VERSION "created by dbc creator v1.0"

NS_ :

BS_:

BU_: T_Box GW DMS DVR HUT Tester

BO_ 482 HCU_HC8: 8 GW
 SG_ HCU_PhoneChrgnModeResp : 15|1@0+ (1,0) [0|1] ""  T_Box
 SG_ HCU_PhoneChrgnReqResp : 14|1@0+ (1,0) [0|1] ""  T_Box
 SG_ HCU_HUTChrgnModeResp : 13|1@0+ (1,0) [0|1] ""  T_Box
 SG_ HCU_HUTChrgnReqResp : 12|1@0+ (1,0) [0|1] ""  T_Box
 SG_ HCU_TboxEngStrtReq : 11|1@0+ (1,0) [0|1] ""  T_Box
 SG_ HCU_TotalScore : 23|3@0+ (1,0) [0|5] ""  HUT
 SG_ HCU_IntelBattTempMagResp : 19|1@0+ (1,0) [0|1] ""  T_Box
 SG_ HCU_RemtVehStartReq : 18|1@0+ (1,0) [0|1] ""  T_Box
 SG_ HCU_HC8_0x1E2 : 7|64@0+ (1,0) [0|0] ""  HUT

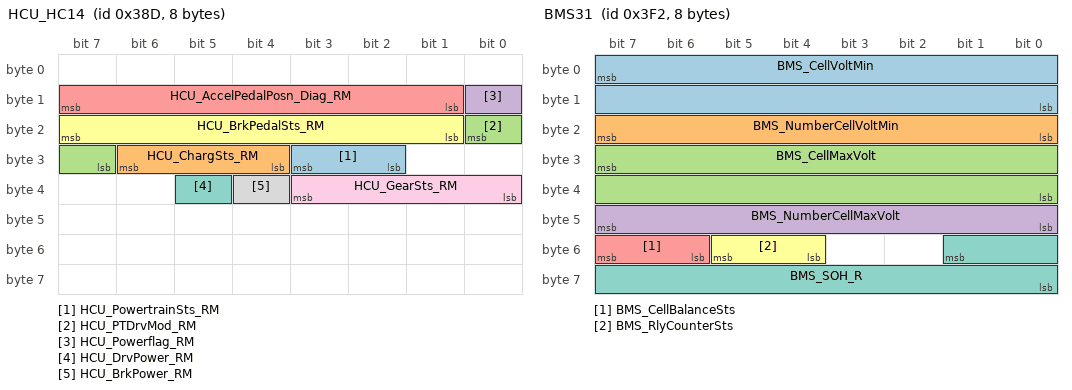
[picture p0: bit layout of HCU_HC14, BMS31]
BO_ 909 HCU_HC14: 8 GW
 SG_ HCU_PowertrainSts_RM : 27|2@0+ (1,0) [0|3] ""  T_Box
 SG_ HCU_ChargSts_RM : 30|3@0+ (1,0) [0|7] ""  T_Box
 SG_ HCU_PTDrvMod_RM : 16|2@0+ (1,0) [0|3] ""  T_Box
 SG_ HCU_Powerflag_RM : 8|1@0+ (1,0) [0|1] ""  T_Box
 SG_ HCU_AccelPedalPosn_Diag_RM : 15|7@0+ (1,0) [0|100] "%"  T_Box
 SG_ HCU_BrkPedalSts_RM : 23|7@0+ (1,0) [0|101] ""  T_Box
 SG_ HCU_DrvPower_RM : 37|1@0+ (1,0) [0|1] ""  T_Box
 SG_ HCU_BrkPower_RM : 36|1@0+ (1,0) [0|1] ""  T_Box
 SG_ HCU_GearSts_RM : 35|4@0+ (1,0) [0|15] ""  T_Box

BO_ 241 BMS4: 8 GW
 SG_ CheckSum_BMS4 : 7|8@0+ (1,0) [0|255] ""  HUT
 SG_ BMS_PowerDownCmplt : 53|1@0+ (1,0) [0|1] ""  HUT
 SG_ BMS_BattPoweErr : 48|2@0+ (1,0) [0|3] ""  HUT
 SG_ BMS_ErrCategory : 62|3@0+ (1,0) [0|7] ""  HUT
 SG_ BMS_PackCurr : 15|14@0+ (0.2,-1000) [-1000|1000] "A"  HUT
 SG_ BMS_PackVolt : 31|8@0+ (2,0) [0|490] "V"  HUT
 SG_ RollingCounter_BMS4 : 59|4@0+ (1,0) [0|15] ""  HUT
 SG_ dummy_BMS4_0 : 17|2@0+ (1,0) [0|3] ""  HUT
 SG_ dummy_BMS4_1 : 39|8@0+ (1,0) [0|255] ""  HUT
 SG_ dummy_BMS4_2 : 47|8@0+ (1,0) [0|255] ""  HUT
 SG_ dummy_BMS4_3 : 55|2@0+ (1,0) [0|3] ""  HUT
 SG_ dummy_BMS4_4 : 52|4@0+ (1,0) [0|15] ""  HUT
 SG_ BMS4_0xF1 : 7|64@0+ (1,0) [0|0] ""  HUT

BO_ 645 BMS8: 8 GW
 SG_ BMS_BattHeatRunaway : 61|2@0+ (1,0) [0|3] ""  HUT,T_Box
 SG_ BMS8_0x285 : 7|64@0+ (1,0) [0|0] ""  HUT

BO_ 708 BMS35: 8 GW
 SG_ BMS_BattSOC : 15|10@0+ (0.1,0) [0|100] "%"  HUT
 SG_ BMS_BattSOCLimResp : 42|3@0+ (1,0) [0|7] ""  HUT
 SG_ BMS35_0x2C4 : 7|64@0+ (1,0) [0|0] ""  HUT

BO_ 850 BMS19: 8 GW
 SG_ BMS_RemtPreHeatSts : 21|3@0+ (1,0) [0|7] ""  T_Box
 SG_ BMS_BattKeepTempSts : 18|1@0+ (1,0) [0|1] ""  HUT,T_Box
 SG_ BMS_IntelEngIdlChrgnSts : 45|2@0+ (1,0) [0|3] ""  HUT,T_Box
 SG_ BMS19_0x352 : 7|64@0+ (1,0) [0|0] ""  HUT

BO_ 959 BMS22: 8 GW
 SG_ BMS_ChrgDurationTime : 47|10@0+ (1,0) [0|1022] "minute"  HUT
 SG_ BMS22_0x3BF : 7|64@0+ (1,0) [0|0] ""  HUT

BO_ 976 BMS26: 8 GW
 SG_ BMS_BattTempMax : 15|8@0+ (1,-40) [-40|125] "Â°C"  T_Box
 SG_ BMS_BattTempMin : 23|8@0+ (1,-40) [-40|125] "Â°C"  T_Box

BO_ 1009 BMS30: 8 GW
 SG_ BMS_CellUnderVolt : 15|1@0+ (1,0) [0|1] ""  T_Box
 SG_ BMS_CellOverVolt : 14|1@0+ (1,0) [0|1] ""  T_Box
 SG_ BMS_CellDeltaVolt : 13|1@0+ (1,0) [0|1] ""  T_Box
 SG_ BMS_BattUnderVolt : 12|1@0+ (1,0) [0|1] ""  T_Box
 SG_ BMS_BattOverVolt : 11|1@0+ (1,0) [0|1] ""  T_Box
 SG_ BMS_BattUnderTemp : 10|1@0+ (1,0) [0|1] ""  T_Box
 SG_ BMS_SOC_Plaucheck : 9|1@0+ (1,0) [0|1] ""  T_Box
 SG_ BMS_DeltaTemp : 8|1@0+ (1,0) [0|1] ""  T_Box
 SG_ BMS_CANComErr : 23|1@0+ (1,0) [0|1] ""  T_Box
 SG_ BMS_SOCLowWarn : 31|1@0+ (1,0) [0|1] ""  HUT
 SG_ BMS_BattSOCLow : 22|1@0+ (1,0) [0|1] ""  T_Box
 SG_ BMS_BattSOCTooLow : 21|1@0+ (1,0) [0|1] ""  T_Box
 SG_ BMS_BattSOCHigh : 20|1@0+ (1,0) [0|1] ""  T_Box
 SG_ BMS_ChrgnCurrLager : 19|1@0+ (1,0) [0|1] ""  T_Box
 SG_ BMS_DischrgnCurrLager : 18|1@0+ (1,0) [0|1] ""  T_Box
 SG_ BMS_ModuleMismatchWarn : 17|1@0+ (1,0) [0|1] ""  T_Box
 SG_ BMS_cohrnc : 16|1@0+ (1,0) [0|1] ""  T_Box
 SG_ BMS_moduleNumber : 43|4@0+ (1,1) [1|9] ""  T_Box
 SG_ BMS_NumModuleTempSnsr : 28|5@0+ (1,1) [1|18] ""  T_Box
 SG_ BMS_NumCell : 39|8@0+ (1,1) [1|108] ""  T_Box
 SG_ BMS30_0x3F1 : 7|64@0+ (1,0) [0|0] ""  HUT

BO_ 1010 BMS31: 8 GW
 SG_ BMS_CellVoltMin : 7|16@0+ (0.001,0) [0|5] "V"  T_Box
 SG_ BMS_NumberCellVoltMin : 23|8@0+ (1,1) [1|108] ""  T_Box
 SG_ BMS_CellMaxVolt : 31|16@0+ (0.001,0) [0|5] "V"  T_Box
 SG_ BMS_NumberCellMaxVolt : 47|8@0+ (1,1) [1|108] ""  T_Box
 SG_ BMS_CellBalanceSts : 55|2@0+ (1,0) [0|3] ""  T_Box
 SG_ BMS_RlyCounterSts : 53|2@0+ (1,0) [0|3] ""  T_Box
 SG_ BMS_SOH_R : 49|10@0+ (0.1,100) [100|200] "%"  T_Box

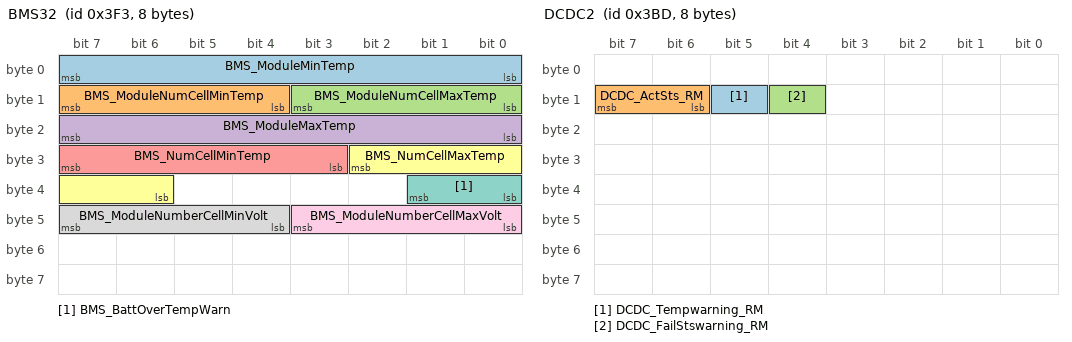
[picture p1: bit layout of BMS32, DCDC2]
BO_ 1011 BMS32: 8 GW
 SG_ BMS_ModuleMinTemp : 7|8@0+ (1,-40) [-40|90] "ÂºC"  T_Box
 SG_ BMS_ModuleNumCellMinTemp : 15|4@0+ (1,1) [1|9] ""  T_Box
 SG_ BMS_ModuleNumCellMaxTemp : 11|4@0+ (1,1) [1|9] ""  T_Box
 SG_ BMS_ModuleMaxTemp : 23|8@0+ (1,-40) [-40|90] "ÂºC"  T_Box
 SG_ BMS_NumCellMinTemp : 31|5@0+ (1,1) [1|18] "_"  T_Box
 SG_ BMS_NumCellMaxTemp : 26|5@0+ (1,1) [1|18] "_"  T_Box
 SG_ BMS_BattOverTempWarn : 33|2@0+ (1,0) [0|3] ""  T_Box
 SG_ BMS_ModuleNumberCellMinVolt : 47|4@0+ (1,1) [1|9] ""  T_Box
 SG_ BMS_ModuleNumberCellMaxVolt : 43|4@0+ (1,1) [1|9] ""  T_Box

BO_ 790 OBC1: 8 GW
 SG_ OBC_ModSts : 19|4@0+ (1,0) [0|15] ""  HUT
 SG_ OBC1_0x316 : 7|64@0+ (1,0) [0|0] ""  HUT

BO_ 791 OBC2: 8 GW
 SG_ OBC_ConnectSts : 15|2@0+ (1,0) [0|3] ""  HUT
 SG_ OBC2_0x317 : 7|64@0+ (1,0) [0|0] ""  HUT

BO_ 96 HCU_FD1: 64 GW
 SG_ HCU_AccelPedalPosn_Diag : 79|8@0+ (0.3937,0) [0|100.395] "%"  HUT
 SG_ HCU_AccelPedalPosn_DiagValid : 85|1@0+ (1,0) [0|1] ""  HUT
 SG_ TMCU_ActRotSpd : 111|16@0+ (1,-16382) [-16382|16383] "rpm"  HUT
 SG_ HCU_PowertrainSts : 303|5@0+ (1,0) [0|31] ""  HUT
 SG_ HCU_RaceLaunchSts : 319|3@0+ (1,0) [0|7] ""  HUT
 SG_ HCU_RaceLaunchAvail : 287|2@0+ (1,0) [0|3] ""  HUT
 SG_ HCU_FD1_0x60 : 7|512@0+ (1,0) [0|0] ""  HUT

BO_ 330 HCU_PT5: 8 GW
 SG_ HCU_DrvMod : 15|4@0+ (1,0) [0|15] ""  HUT
 SG_ HCUImmoAuthRes : 21|2@0+ (1,0) [0|3] ""  HUT
 SG_ HCU_EVLmpSts : 16|1@0+ (1,0) [0|1] ""  HUT
 SG_ HCU_ECODrvHabit_Indcn : 31|8@0+ (0.1,-10) [-10|10] ""  HUT
 SG_ HCU_TotDrvReqPower : 39|8@0+ (1,-100) [-100|100] "%"  HUT
 SG_ HCU_AvailPower_TM : 55|8@0+ (0.5,0) [0|50] "%"  HUT
 SG_ HCU_PT5_0x14A : 7|64@0+ (1,0) [0|0] ""  HUT

BO_ 584 HCU_PT7: 8 GW
 SG_ CheckSum_HCU_PT7 : 7|8@0+ (1,0) [0|255] ""  HUT
 SG_ HCU_HybSysErr_1 : 15|1@0+ (1,0) [0|1] ""  HUT
 SG_ HCU_HybSysErr_2 : 14|1@0+ (1,0) [0|1] ""  HUT
 SG_ HCU_HybSysErr_3 : 13|1@0+ (1,0) [0|1] ""  HUT
 SG_ HCU_HybSysErr_4 : 12|1@0+ (1,0) [0|1] ""  HUT
 SG_ HCU_HybSysErr_5 : 11|1@0+ (1,0) [0|1] ""  HUT
 SG_ HCU_HybSysErr_6 : 10|1@0+ (1,0) [0|1] ""  HUT
 SG_ HCU_HybSysErr_7 : 9|1@0+ (1,0) [0|1] ""  HUT
 SG_ HCU_12VSysErrLmpSts : 8|1@0+ (1,0) [0|1] ""  HUT
 SG_ HCU_HybSysErrLmpSts : 27|2@0+ (1,0) [0|3] ""  HUT
 SG_ HCU_PowerRedWarnLmpCmd : 25|1@0+ (1,0) [0|1] ""  HUT
 SG_ HCU_12VSysErr_1 : 24|1@0+ (1,0) [0|1] ""  HUT
 SG_ HCU_12VSysErr_2 : 39|1@0+ (1,0) [0|1] ""  HUT
 SG_ HCU_RdyLmpSts : 37|1@0+ (1,0) [0|1] ""  HUT
 SG_ HCU_ModSwtFail : 63|4@0+ (1,0) [0|15] ""  HUT
 SG_ HCU_EnrgFlowInd : 55|5@0+ (1,0) [0|31] ""  HUT
 SG_ HCU_OPDSts : 43|3@0+ (1,0) [0|7] ""  HUT
 SG_ HCU_OPDLmpSts : 36|1@0+ (1,0) [0|1] ""  HUT
 SG_ RollingCounter_HCU_PT7 : 59|4@0+ (1,0) [0|15] ""  HUT
 SG_ dummy_HCU_PT7_0 : 23|8@0+ (1,0) [0|255] ""  HUT
 SG_ dummy_HCU_PT7_1 : 31|4@0+ (1,0) [0|15] ""  HUT
 SG_ dummy_HCU_PT7_2 : 38|1@0+ (1,0) [0|1] ""  HUT
 SG_ dummy_HCU_PT7_3 : 35|4@0+ (1,0) [0|15] ""  HUT
 SG_ dummy_HCU_PT7_4 : 47|4@0+ (1,0) [0|15] ""  HUT
 SG_ dummy_HCU_PT7_5 : 40|1@0+ (1,0) [0|1] ""  HUT
 SG_ dummy_HCU_PT7_6 : 50|3@0+ (1,0) [0|7] ""  HUT
 SG_ HCU_PT7_0x248 : 7|64@0+ (1,0) [0|0] ""  HUT

BO_ 448 HCU_PT8: 8 GW
 SG_ HCU_ChrgSysLmpSts : 18|3@0+ (1,0) [0|7] ""  HUT
 SG_ HCU_ChrgSysErr_1 : 31|1@0+ (1,0) [0|1] ""  HUT
 SG_ HCU_ChrgSysErr_2 : 30|1@0+ (1,0) [0|1] ""  HUT
 SG_ HCU_ChrgSysErr_3 : 29|1@0+ (1,0) [0|1] ""  HUT
 SG_ HCU_ChrgSysErr_4 : 28|1@0+ (1,0) [0|1] ""  HUT
 SG_ HCU_ChrgSysErr_5 : 27|1@0+ (1,0) [0|1] ""  HUT
 SG_ HCU_ChrgSysErr_6 : 26|1@0+ (1,0) [0|1] ""  HUT
 SG_ HCU_ChrgSysErr_7 : 25|1@0+ (1,0) [0|1] ""  HUT
 SG_ HCU_ChrgSysErr_8 : 24|1@0+ (1,0) [0|1] ""  HUT
 SG_ HCU_PT8_0x1C0 : 7|64@0+ (1,0) [0|0] ""  HUT

BO_ 762 HCU_PT4: 8 GW
 SG_ CheckSum_HCU_PT4 : 7|8@0+ (1,0) [0|255] ""  HUT
 SG_ HCU_BattPowerRedWarn : 17|2@0+ (1,0) [0|3] ""  HUT
 SG_ HCU_EnerSavePowerMod : 29|2@0+ (1,0) [0|3] ""  HUT
 SG_ HCU_SOCLow_Indcn : 25|1@0+ (1,0) [0|1] ""  HUT
 SG_ HCU_RemoveChrgLine_Indcn : 24|1@0+ (1,0) [0|1] ""  HUT
 SG_ HCU_WadeModeSetSts : 37|1@0+ (1,0) [0|1] ""  HUT
 SG_ HCU_Shift_P_Indcn : 36|1@0+ (1,0) [0|1] ""  HUT
 SG_ HCU_ConnectChrgLine_Indcn : 35|1@0+ (1,0) [0|1] ""  HUT
 SG_ HCU_EgyRecFB : 47|2@0+ (1,0) [0|3] ""  HUT
 SG_ HCU_ACStsReq : 50|2@0+ (1,0) [0|3] ""  HUT
 SG_ HCU_RefuReq : 23|3@0+ (1,0) [0|7] ""  HUT
 SG_ HCU_OilTankCoverSts : 45|1@0+ (1,0) [0|1] ""  HUT
 SG_ HCU_InhbChrgInfo : 44|1@0+ (1,0) [0|1] ""  HUT
 SG_ OPDParkWarnReq : 27|1@0+ (1,0) [0|1] ""  HUT
 SG_ HCU_OPDFail : 31|2@0+ (1,0) [0|3] ""  HUT
 SG_ CarWashMode_StsDisp : 62|3@0+ (1,0) [0|7] ""  HUT
 SG_ CarWashMode_Sts : 63|1@0+ (1,0) [0|1] ""  HUT
 SG_ HCU_RefuBtnSts : 48|1@0+ (1,0) [0|1] ""  T_Box,HUT
 SG_ RollingCounter_HCU_PT4 : 59|4@0+ (1,0) [0|15] ""  HUT
 SG_ dummy_HCU_PT4_0 : 15|8@0+ (1,0) [0|255] ""  HUT
 SG_ dummy_HCU_PT4_1 : 20|3@0+ (1,0) [0|7] ""  HUT
 SG_ dummy_HCU_PT4_2 : 26|1@0+ (1,0) [0|1] ""  HUT
 SG_ dummy_HCU_PT4_3 : 39|2@0+ (1,0) [0|3] ""  HUT
 SG_ dummy_HCU_PT4_4 : 34|3@0+ (1,0) [0|7] ""  HUT
 SG_ dummy_HCU_PT4_5 : 43|4@0+ (1,0) [0|15] ""  HUT
 SG_ dummy_HCU_PT4_6 : 55|5@0+ (1,0) [0|31] ""  HUT
 SG_ HCU_PT4_0x2FA : 7|64@0+ (1,0) [0|0] ""  HUT

BO_ 513 HCU_HP5: 8 GW
 SG_ Checksum_HCU_HP5 : 7|8@0+ (1,0) [0|255] ""  HUT
 SG_ HCU_EnrgFlowInd_DHT : 15|6@0+ (1,0) [0|63] ""  HUT
 SG_ HCU_PrsBrkWarn : 23|2@0+ (1,0) [0|3] ""  HUT
 SG_ DrvModDisp_0x201 : 39|3@0+ (1,0) [0|7] ""  HUT
 SG_ DrvModDispSts_0x201 : 36|2@0+ (1,0) [0|3] ""  HUT
 SG_ DrvGearDisp : 34|3@0+ (1,0) [0|7] ""  HUT
 SG_ DrvGearDispSts_0x201 : 47|2@0+ (1,0) [0|3] ""  HUT
 SG_ HCU_ShftNotAlwd_Warn : 45|2@0+ (1,0) [0|3] ""  HUT
 SG_ DrvFaiMsg_0x201 : 43|4@0+ (1,0) [0|15] ""  HUT
 SG_ RollingCounter_HCU_HP5 : 59|4@0+ (1,0) [0|15] ""  HUT
 SG_ dummy_HCU_HP5_0 : 9|2@0+ (1,0) [0|3] ""  HUT
 SG_ dummy_HCU_HP5_1 : 21|6@0+ (1,0) [0|63] ""  HUT
 SG_ dummy_HCU_HP5_2 : 31|8@0+ (1,0) [0|255] ""  HUT
 SG_ dummy_HCU_HP5_3 : 55|8@0+ (1,0) [0|255] ""  HUT
 SG_ dummy_HCU_HP5_4 : 63|4@0+ (1,0) [0|15] ""  HUT
 SG_ HCU_HP5_0x201 : 7|64@0+ (1,0) [0|0] ""  HUT

BO_ 288 Ibooster_FD2: 64 GW
 SG_ IB_Warn : 46|1@0+ (1,0) [0|1] ""  HUT
 SG_ Ibooster_FD2_0x120 : 7|512@0+ (1,0) [0|0] ""  HUT

BO_ 200 ESP11: 8 GW
 SG_ ESP_HMI_WarningOn : 41|2@0+ (1,0) [0|3] ""  HUT
 SG_ ESP11_0xC8 : 7|64@0+ (1,0) [0|0] ""  HUT

BO_ 216 ESP10: 8 GW
 SG_ TgtRcprtnTrqSts : 47|2@0+ (1,0) [0|3] ""  HUT
 SG_ ESP10_0xD8 : 7|64@0+ (1,0) [0|0] ""  HUT

BO_ 957 DCDC2: 8 GW
 SG_ DCDC_Tempwarning_RM : 13|1@0+ (1,0) [0|1] ""  T_Box
 SG_ DCDC_ActSts_RM : 15|2@0+ (1,0) [0|3] ""  T_Box
 SG_ DCDC_FailStswarning_RM : 12|1@0+ (1,0) [0|1] ""  T_Box

BO_ 969 TMCU_FD3: 8 GW
 SG_ TMCU_Amount_RM : 15|8@0+ (1,0) [1|253] ""  T_Box
 SG_ TMCU_MotorSerNumber_RM : 7|8@0+ (1,0) [1|253] ""  T_Box
 SG_ TMCU_InvActTemp_RM : 23|8@0+ (1,-40) [-40|210] "Â°C"  T_Box
 SG_ TMCU_ActSpd_RM : 31|16@0+ (1,-20000) [-20000|45531] "rpm"  HUT,T_Box
 SG_ TMCU_ActTrq_RM : 47|16@0+ (0.1,-2000) [-2000|4553.1] "Nm"  T_Box
 SG_ TMCU_FD3_0x3C9 : 7|64@0+ (1,0) [0|0] ""  HUT

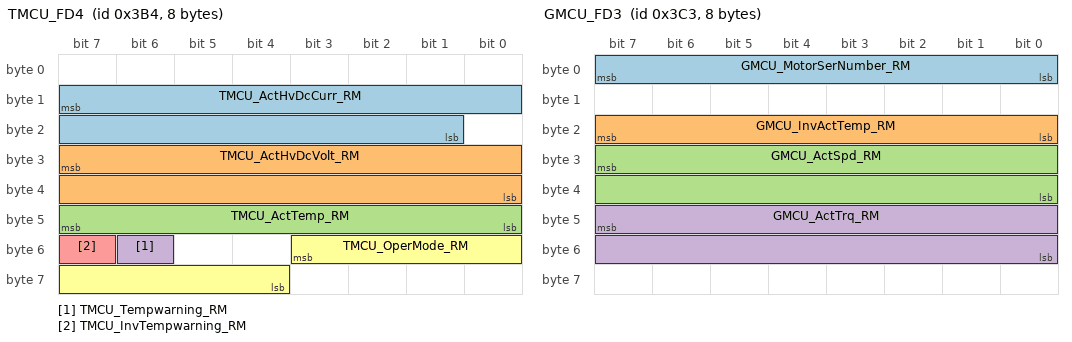
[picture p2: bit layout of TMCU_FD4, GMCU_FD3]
BO_ 948 TMCU_FD4: 8 GW
 SG_ TMCU_ActHvDcCurr_RM : 15|15@0+ (0.1,-1000) [-1000|1000] "A"  T_Box
 SG_ TMCU_ActHvDcVolt_RM : 31|16@0+ (0.1,0) [0|6000] "V"  T_Box
 SG_ TMCU_ActTemp_RM : 47|8@0+ (1,-40) [-40|210] "Â°C"  T_Box
 SG_ TMCU_Tempwarning_RM : 54|1@0+ (1,0) [0|1] ""  T_Box
 SG_ TMCU_InvTempwarning_RM : 55|1@0+ (1,0) [0|1] ""  T_Box
 SG_ TMCU_OperMode_RM : 51|8@0+ (1,0) [0|255] ""  T_Box

BO_ 977 BMS_FD5: 64 GW
 SG_ BMS_BattModuleTe_11 : 135|8@0+ (1,-40) [-40|125] "Â°C"  T_Box
 SG_ BMS_BattModuleTe_12 : 143|8@0+ (1,-40) [-40|125] "Â°C"  T_Box
 SG_ BMS_BattModuleTe_21 : 151|8@0+ (1,-40) [-40|125] "Â°C"  T_Box
 SG_ BMS_BattModuleTe_22 : 159|8@0+ (1,-40) [-40|125] "Â°C"  T_Box
 SG_ BMS_BattModuleTe_31 : 167|8@0+ (1,-40) [-40|125] "Â°C"  T_Box
 SG_ BMS_BattModuleTe_32 : 175|8@0+ (1,-40) [-40|125] "Â°C"  T_Box
 SG_ BMS_BattModuleTe_41 : 183|8@0+ (1,-40) [-40|125] "Â°C"  T_Box
 SG_ BMS_BattModuleTe_42 : 191|8@0+ (1,-40) [-40|125] "Â°C"  T_Box
 SG_ BMS_BattModuleTe_51 : 71|8@0+ (1,-40) [-40|125] "ÂºC"  T_Box
 SG_ BMS_BattModuleTe_52 : 79|8@0+ (1,-40) [-40|125] "ÂºC"  T_Box
 SG_ BMS_BattModuleTe_61 : 87|8@0+ (1,-40) [-40|125] "ÂºC"  T_Box
 SG_ BMS_BattModuleTe_62 : 95|8@0+ (1,-40) [-40|125] "ÂºC"  T_Box
 SG_ BMS_BattModuleTe_71 : 103|8@0+ (1,-40) [-40|125] "ÂºC"  T_Box
 SG_ BMS_BattModuleTe_72 : 111|8@0+ (1,-40) [-40|125] "ÂºC"  T_Box
 SG_ BMS_BattModuleTe_81 : 119|8@0+ (1,-40) [-40|125] "ÂºC"  T_Box
 SG_ BMS_BattModuleTe_82 : 127|8@0+ (1,-40) [-40|125] "ÂºC"  T_Box
 SG_ BMS_SingleCellVolt_1 : 263|16@0+ (0.001,0) [0|60] "V"  T_Box
 SG_ BMS_SingleCellVolt_2 : 279|16@0+ (0.001,0) [0|60] "V"  T_Box
 SG_ BMS_SingleCellVolt_3 : 295|16@0+ (0.001,0) [0|60] "V"  T_Box
 SG_ BMS_SingleCellVolt_4 : 311|16@0+ (0.001,0) [0|60] "V"  T_Box
 SG_ BMS_SingleCellVolt_5 : 327|16@0+ (0.001,0) [0|60] "V"  T_Box
 SG_ BMS_SingleCellVolt_6 : 343|16@0+ (0.001,0) [0|60] "V"  T_Box
 SG_ BMS_SingleCellVolt_7 : 359|16@0+ (0.001,0) [0|60] "V"  T_Box
 SG_ BMS_SingleCellVolt_8 : 375|16@0+ (0.001,0) [0|60] "V"  T_Box
 SG_ BMS_SingleCellVolt_9 : 391|16@0+ (0.001,0) [0|60] "V"  T_Box
 SG_ BMS_SingleCellVolt_10 : 407|16@0+ (0.001,0) [0|60] "V"  T_Box
 SG_ BMS_SingleCellVolt_11 : 423|16@0+ (0.001,0) [0|60] "V"  T_Box
 SG_ BMS_SingleCellVolt_12 : 439|16@0+ (0.001,0) [0|60] "V"  T_Box

BO_ 978 BMS_FD6: 64 GW
 SG_ BMS_SingleCellVolt_13 : 7|16@0+ (0.001,0) [0|60] "V"  T_Box
 SG_ BMS_SingleCellVolt_14 : 23|16@0+ (0.001,0) [0|60] "V"  T_Box
 SG_ BMS_SingleCellVolt_15 : 39|16@0+ (0.001,0) [0|60] "V"  T_Box
 SG_ BMS_SingleCellVolt_16 : 55|16@0+ (0.001,0) [0|60] "V"  T_Box
 SG_ BMS_SingleCellVolt_17 : 71|16@0+ (0.001,0) [0|60] "V"  T_Box
 SG_ BMS_SingleCellVolt_18 : 87|16@0+ (0.001,0) [0|60] "V"  T_Box
 SG_ BMS_SingleCellVolt_19 : 103|16@0+ (0.001,0) [0|60] "V"  T_Box
 SG_ BMS_SingleCellVolt_20 : 119|16@0+ (0.001,0) [0|60] "V"  T_Box
 SG_ BMS_SingleCellVolt_21 : 135|16@0+ (0.001,0) [0|60] "V"  T_Box
 SG_ BMS_SingleCellVolt_22 : 151|16@0+ (0.001,0) [0|60] "V"  T_Box
 SG_ BMS_SingleCellVolt_23 : 167|16@0+ (0.001,0) [0|60] "V"  T_Box
 SG_ BMS_SingleCellVolt_24 : 183|16@0+ (0.001,0) [0|60] "V"  T_Box
 SG_ BMS_SingleCellVolt_25 : 199|16@0+ (0.001,0) [0|60] "V"  T_Box
 SG_ BMS_SingleCellVolt_26 : 215|16@0+ (0.001,0) [0|60] "V"  T_Box
 SG_ BMS_SingleCellVolt_27 : 231|16@0+ (0.001,0) [0|60] "V"  T_Box
 SG_ BMS_SingleCellVolt_28 : 247|16@0+ (0.001,0) [0|60] "V"  T_Box
 SG_ BMS_SingleCellVolt_29 : 263|16@0+ (0.001,0) [0|60] "V"  T_Box
 SG_ BMS_SingleCellVolt_30 : 279|16@0+ (0.001,0) [0|60] "V"  T_Box
 SG_ BMS_SingleCellVolt_31 : 295|16@0+ (0.001,0) [0|60] "V"  T_Box
 SG_ BMS_SingleCellVolt_32 : 311|16@0+ (0.001,0) [0|60] "V"  T_Box
 SG_ BMS_SingleCellVolt_33 : 327|16@0+ (0.001,0) [0|60] "V"  T_Box
 SG_ BMS_SingleCellVolt_34 : 343|16@0+ (0.001,0) [0|60] "V"  T_Box
 SG_ BMS_SingleCellVolt_35 : 359|16@0+ (0.001,0) [0|60] "V"  T_Box
 SG_ BMS_SingleCellVolt_36 : 375|16@0+ (0.001,0) [0|60] "V"  T_Box
 SG_ BMS_SingleCellVolt_37 : 391|16@0+ (0.001,0) [0|60] "V"  T_Box
 SG_ BMS_SingleCellVolt_38 : 407|16@0+ (0.001,0) [0|60] "V"  T_Box
 SG_ BMS_SingleCellVolt_39 : 423|16@0+ (0.001,0) [0|60] "V"  T_Box
 SG_ BMS_SingleCellVolt_40 : 439|16@0+ (0.001,0) [0|60] "V"  T_Box

BO_ 979 BMS_FD7: 64 GW
 SG_ BMS_SingleCellVolt_41 : 7|16@0+ (0.001,0) [0|60] "V"  T_Box
 SG_ BMS_SingleCellVolt_42 : 23|16@0+ (0.001,0) [0|60] "V"  T_Box
 SG_ BMS_SingleCellVolt_43 : 39|16@0+ (0.001,0) [0|60] "V"  T_Box
 SG_ BMS_SingleCellVolt_44 : 55|16@0+ (0.001,0) [0|60] "V"  T_Box
 SG_ BMS_SingleCellVolt_45 : 71|16@0+ (0.001,0) [0|60] "V"  T_Box
 SG_ BMS_SingleCellVolt_46 : 87|16@0+ (0.001,0) [0|60] "V"  T_Box
 SG_ BMS_SingleCellVolt_47 : 103|16@0+ (0.001,0) [0|60] "V"  T_Box
 SG_ BMS_SingleCellVolt_48 : 119|16@0+ (0.001,0) [0|60] "V"  T_Box
 SG_ BMS_SingleCellVolt_49 : 135|16@0+ (0.001,0) [0|60] "V"  T_Box
 SG_ BMS_SingleCellVolt_50 : 151|16@0+ (0.001,0) [0|60] "V"  T_Box
 SG_ BMS_SingleCellVolt_51 : 167|16@0+ (0.001,0) [0|60] "V"  T_Box
 SG_ BMS_SingleCellVolt_52 : 183|16@0+ (0.001,0) [0|60] "V"  T_Box
 SG_ BMS_SingleCellVolt_53 : 199|16@0+ (0.001,0) [0|60] "V"  T_Box
 SG_ BMS_SingleCellVolt_54 : 215|16@0+ (0.001,0) [0|60] "V"  T_Box
 SG_ BMS_SingleCellVolt_55 : 231|16@0+ (0.001,0) [0|60] "V"  T_Box
 SG_ BMS_SingleCellVolt_56 : 247|16@0+ (0.001,0) [0|60] "V"  T_Box
 SG_ BMS_SingleCellVolt_57 : 263|16@0+ (0.001,0) [0|60] "V"  T_Box
 SG_ BMS_SingleCellVolt_58 : 279|16@0+ (0.001,0) [0|60] "V"  T_Box
 SG_ BMS_SingleCellVolt_59 : 295|16@0+ (0.001,0) [0|60] "V"  T_Box
 SG_ BMS_SingleCellVolt_60 : 311|16@0+ (0.001,0) [0|60] "V"  T_Box
 SG_ BMS_SingleCellVolt_61 : 327|16@0+ (0.001,0) [0|60] "V"  T_Box
 SG_ BMS_SingleCellVolt_62 : 343|16@0+ (0.001,0) [0|60] "V"  T_Box
 SG_ BMS_SingleCellVolt_63 : 359|16@0+ (0.001,0) [0|60] "V"  T_Box
 SG_ BMS_SingleCellVolt_64 : 375|16@0+ (0.001,0) [0|60] "V"  T_Box
 SG_ BMS_SingleCellVolt_65 : 391|16@0+ (0.001,0) [0|60] "V"  T_Box
 SG_ BMS_SingleCellVolt_66 : 407|16@0+ (0.001,0) [0|60] "V"  T_Box
 SG_ BMS_SingleCellVolt_67 : 423|16@0+ (0.001,0) [0|60] "V"  T_Box
 SG_ BMS_SingleCellVolt_68 : 439|16@0+ (0.001,0) [0|60] "V"  T_Box

BO_ 980 BMS_FD8: 64 GW
 SG_ BMS_SingleCellVolt_69 : 7|16@0+ (0.001,0) [0|60] "V"  T_Box
 SG_ BMS_SingleCellVolt_70 : 23|16@0+ (0.001,0) [0|60] "V"  T_Box
 SG_ BMS_SingleCellVolt_71 : 39|16@0+ (0.001,0) [0|60] "V"  T_Box
 SG_ BMS_SingleCellVolt_72 : 55|16@0+ (0.001,0) [0|60] "V"  T_Box
 SG_ BMS_SingleCellVolt_73 : 71|16@0+ (0.001,0) [0|60] "V"  T_Box
 SG_ BMS_SingleCellVolt_74 : 87|16@0+ (0.001,0) [0|60] "V"  T_Box
 SG_ BMS_SingleCellVolt_75 : 103|16@0+ (0.001,0) [0|60] "V"  T_Box
 SG_ BMS_SingleCellVolt_76 : 119|16@0+ (0.001,0) [0|60] "V"  T_Box
 SG_ BMS_SingleCellVolt_77 : 135|16@0+ (0.001,0) [0|60] "V"  T_Box
 SG_ BMS_SingleCellVolt_78 : 151|16@0+ (0.001,0) [0|60] "V"  T_Box
 SG_ BMS_SingleCellVolt_79 : 167|16@0+ (0.001,0) [0|60] "V"  T_Box
 SG_ BMS_SingleCellVolt_80 : 183|16@0+ (0.001,0) [0|60] "V"  T_Box
 SG_ BMS_SingleCellVolt_81 : 199|16@0+ (0.001,0) [0|60] "V"  T_Box
 SG_ BMS_SingleCellVolt_82 : 215|16@0+ (0.001,0) [0|60] "V"  T_Box
 SG_ BMS_SingleCellVolt_83 : 231|16@0+ (0.001,0) [0|60] "V"  T_Box
 SG_ BMS_SingleCellVolt_84 : 247|16@0+ (0.001,0) [0|60] "V"  T_Box
 SG_ BMS_SingleCellVolt_85 : 263|16@0+ (0.001,0) [0|60] "V"  T_Box
 SG_ BMS_SingleCellVolt_86 : 279|16@0+ (0.001,0) [0|60] "V"  T_Box
 SG_ BMS_SingleCellVolt_87 : 295|16@0+ (0.001,0) [0|60] "V"  T_Box
 SG_ BMS_SingleCellVolt_88 : 311|16@0+ (0.001,0) [0|60] "V"  T_Box
 SG_ BMS_SingleCellVolt_89 : 327|16@0+ (0.001,0) [0|60] "V"  T_Box
 SG_ BMS_SingleCellVolt_90 : 343|16@0+ (0.001,0) [0|60] "V"  T_Box
 SG_ BMS_SingleCellVolt_91 : 359|16@0+ (0.001,0) [0|60] "V"  T_Box
 SG_ BMS_SingleCellVolt_92 : 375|16@0+ (0.001,0) [0|60] "V"  T_Box
 SG_ BMS_SingleCellVolt_93 : 391|16@0+ (0.001,0) [0|60] "V"  T_Box
 SG_ BMS_SingleCellVolt_94 : 407|16@0+ (0.001,0) [0|60] "V"  T_Box
 SG_ BMS_SingleCellVolt_95 : 423|16@0+ (0.001,0) [0|60] "V"  T_Box
 SG_ BMS_SingleCellVolt_96 : 439|16@0+ (0.001,0) [0|60] "V"  T_Box

BO_ 981 BMS_FD9: 64 GW
 SG_ BMS_SingleCellVolt_97 : 7|16@0+ (0.001,0) [0|60] "V"  T_Box
 SG_ BMS_SingleCellVolt_98 : 23|16@0+ (0.001,0) [0|60] "V"  T_Box
 SG_ BMS_SingleCellVolt_99 : 39|16@0+ (0.001,0) [0|60] "V"  T_Box
 SG_ BMS_SingleCellVolt_100 : 55|16@0+ (0.001,0) [0|60] "V"  T_Box
 SG_ BMS_SingleCellVolt_101 : 71|16@0+ (0.001,0) [0|60] "V"  T_Box
 SG_ BMS_SingleCellVolt_102 : 87|16@0+ (0.001,0) [0|60] "V"  T_Box
 SG_ BMS_SingleCellVolt_103 : 103|16@0+ (0.001,0) [0|60] "V"  T_Box
 SG_ BMS_SingleCellVolt_104 : 119|16@0+ (0.001,0) [0|60] "V"  T_Box
 SG_ BMS_SingleCellVolt_105 : 135|16@0+ (0.001,0) [0|60] "V"  T_Box
 SG_ BMS_SingleCellVolt_106 : 151|16@0+ (0.001,0) [0|60] "V"  T_Box
 SG_ BMS_SingleCellVolt_107 : 167|16@0+ (0.001,0) [0|60] "V"  T_Box
 SG_ BMS_SingleCellVolt_108 : 183|16@0+ (0.001,0) [0|60] "V"  T_Box
 SG_ BMS_SingleCellVolt_109 : 199|16@0+ (0.001,0) [0|60] "V"  T_Box
 SG_ BMS_SingleCellVolt_110 : 215|16@0+ (0.001,0) [0|60] "V"  T_Box
 SG_ BMS_SingleCellVolt_111 : 231|16@0+ (0.001,0) [0|60] "V"  T_Box
 SG_ BMS_SingleCellVolt_112 : 247|16@0+ (0.001,0) [0|60] "V"  T_Box
 SG_ BMS_BattModuleTe_91 : 263|8@0+ (1,-40) [-40|125] "Â°C"  T_Box
 SG_ BMS_BattModuleTe_92 : 271|8@0+ (1,-40) [-40|125] "Â°C"  T_Box
 SG_ BMS_DTCNumber : 279|9@0+ (1,0) [0|501] ""  T_Box
 SG_ BMS_SWVersion_PHEV : 286|16@0+ (1,0) [0|65535] ""  T_Box
 SG_ BMS_NumberCellVoltMin_RM : 311|8@0+ (1,0) [1|250] ""  T_Box
 SG_ BMS_ModuleMaxTemp_RM : 319|8@0+ (1,-40) [-40|210] "â„ƒ"  T_Box
 SG_ BMS_BattModuleTe_13 : 391|8@0+ (1,-40) [-40|125] "Â°C"  T_Box
 SG_ BMS_BattModuleTe_23 : 399|8@0+ (1,-40) [-40|125] "Â°C"  T_Box
 SG_ BMS_BattModuleTe_33 : 407|8@0+ (1,-40) [-40|125] "Â°C"  T_Box
 SG_ BMS_BattModuleTe_43 : 415|8@0+ (1,-40) [-40|125] "Â°C"  T_Box
 SG_ BMS_BattModuleTe_53 : 423|8@0+ (1,-40) [-40|125] "Â°C"  T_Box
 SG_ BMS_BattModuleTe_63 : 431|8@0+ (1,-40) [-40|125] "Â°C"  T_Box

BO_ 1008 BMS_FD12: 64 GW
 SG_ BMS_CellMaxVolt_RM : 327|16@0+ (0.001,0) [0|15] "V"  T_Box
 SG_ BMS_CellVoltMin_RM : 343|16@0+ (0.001,0) [0|15] "V"  T_Box
 SG_ BMS_NumCellMaxTemp_RM : 359|8@0+ (1,0) [1|250] ""  T_Box
 SG_ BMS_NumCellMinTemp_RM : 367|8@0+ (1,0) [1|250] ""  T_Box
 SG_ BMS_ModuleMinTemp_RM : 375|8@0+ (1,-40) [-40|210] "â„ƒ"  T_Box
 SG_ BMS_NumberCellVoltMax_RM : 383|8@0+ (1,0) [1|250] ""  T_Box
 SG_ BMS_SocJumpWarn_RM : 391|1@0+ (1,0) [0|1] ""  T_Box
 SG_ BMS_PackOverChrgWarn_RM : 390|1@0+ (1,0) [0|1] ""  T_Box
 SG_ BMS_IsolationRValue_RM : 399|16@0+ (1,0) [0|60000] "Kohm"  T_Box
 SG_ BMS_PackCurr_RM : 415|15@0+ (0.1,-1000) [-1000|1000] "A"  T_Box
 SG_ BMS_SocOverWarn_RM : 416|1@0+ (1,0) [0|1] ""  T_Box
 SG_ BMS_BattOverTempRank_RM : 431|1@0+ (1,0) [0|1] ""  T_Box
 SG_ BMS_BattOverVoltRank_RM : 430|1@0+ (1,0) [0|1] ""  T_Box
 SG_ BMS_BattSOCLowRank_RM : 429|1@0+ (1,0) [0|1] ""  T_Box
 SG_ BMS_VCUIsolateErr_RM : 428|1@0+ (1,0) [0|1] ""  T_Box
 SG_ BMS_BattUnderVoltRank_RM : 427|1@0+ (1,0) [0|1] ""  T_Box
 SG_ BMS_CellDeltaVoltRank_RM : 426|1@0+ (1,0) [0|1] ""  T_Box
 SG_ BMS_CellOverVoltRank_RM : 425|1@0+ (1,0) [0|1] ""  T_Box
 SG_ BMS_CellUnderVoltRank_RM : 424|1@0+ (1,0) [0|1] ""  T_Box
 SG_ BMS_DeltaTempRank_RM : 439|1@0+ (1,0) [0|1] ""  T_Box
 SG_ BMS_PackMismatchWarn_RM : 438|1@0+ (1,0) [0|1] ""  T_Box
 SG_ BMS_PackVolt_RM : 437|14@0+ (0.1,0) [0|1000] "V"  T_Box
 SG_ BMS_SysNumberCellVoltMax_RM : 455|8@0+ (1,0) [1|250] ""  T_Box
 SG_ BMS_SysNumberCellVoltMin_RM : 463|8@0+ (1,0) [1|250] ""  T_Box
 SG_ BMS_SysNumCellMaxTemp_RM : 471|8@0+ (1,0) [0|250] ""  T_Box
 SG_ BMS_SysNumCellMinTemp_RM : 479|8@0+ (1,0) [0|250] ""  T_Box
 SG_ BMS_BattSysNum_RM : 487|8@0+ (1,0) [0|250] ""  T_Box

BO_ 483 BMS_FD14: 8 GW
 SG_ BMS_BattKeepTempResp_PHEV : 11|2@0+ (1,0) [0|3] ""  T_Box

BO_ 147 TMCU6: 8 GW
 SG_ TMCU_ActPosRotSpd : 15|16@0+ (1,0) [0|65534] "rpm"  HUT,T_Box,DMS,DVR
 SG_ TMCU6_0x93 : 7|64@0+ (1,0) [0|0] ""  HUT

BO_ 193 DHT_FD1: 64 GW
 SG_ CheckSum_DHT1 : 71|8@0+ (1,0) [0|255] ""  HUT
 SG_ TCU_ClutchHotWarning : 73|2@0+ (1,0) [0|3] ""  HUT
 SG_ TCU_ErrCategory : 103|8@0+ (1,0) [0|255] ""  HUT
 SG_ RollingCounter_DHT1 : 123|4@0+ (1,0) [0|15] ""  HUT
 SG_ dummy_DHT_FD1_8 : 79|6@0+ (1,0) [0|63] ""  HUT
 SG_ dummy_DHT_FD1_9 : 87|8@0+ (1,0) [0|255] ""  HUT
 SG_ dummy_DHT_FD1_10 : 95|8@0+ (1,0) [0|255] ""  HUT
 SG_ dummy_DHT_FD1_11 : 111|8@0+ (1,0) [0|255] ""  HUT
 SG_ dummy_DHT_FD1_12 : 119|8@0+ (1,0) [0|255] ""  HUT
 SG_ dummy_DHT_FD1_13 : 127|4@0+ (1,0) [0|15] ""  HUT
 SG_ DHT_FD1_0xC1 : 7|512@0+ (1,0) [0|0] ""  HUT

BO_ 282 HCU_HP6: 8 GW
 SG_ HCU_GearSts : 36|4@0+ (1,0) [0|15] ""  HUT,T_Box,DMS
 SG_ HCU_HP6_0x11A : 7|64@0+ (1,0) [0|0] ""  HUT

BO_ 265 IFC1: 8 GW
 SG_ IFCTrqOvlCmdProtnValue : 15|14@0+ (1,0) [0|16383] ""  HUT
 SG_ IFCTrqOvlCmdReqValue : 39|11@0+ (0.01,-10.23) [-10.23|10.24] "Nm"  HUT
 SG_ IFC1_0x109 : 7|64@0+ (1,0) [0|0] ""  HUT

BO_ 350 CR_FD1: 64 GW
 SG_ CR_FCTA_Resp : 79|1@0+ (1,0) [0|1] ""  HUT
 SG_ CR_FCTB_Resp : 78|1@0+ (1,0) [0|1] ""  HUT
 SG_ CR_BliSts : 86|1@0+ (1,0) [0|1] ""  HUT
 SG_ FCTA_Warn : 75|1@0+ (1,0) [0|1] ""  HUT
 SG_ FCTBTrig : 83|1@0+ (1,0) [0|1] ""  HUT
 SG_ FCTA_B_FuncSts : 77|2@0+ (1,0) [0|3] ""  HUT
 SG_ FCTA_B_TTC : 110|6@0+ (0.1,0) [0|6.3] "s"  HUT
 SG_ CR_FD1_0x15E : 7|512@0+ (1,0) [0|0] ""  HUT

BO_ 692 ACC_FD3: 64 GW
 SG_ AEB_LePedDetn : 41|2@0+ (1,0) [0|3] "" Vector__XXX
 SG_ AEB_LePedDy : 15|8@0+ (0.1,-8) [-8|8] "m" Vector__XXX
 SG_ AEB_LePedTyp : 55|3@0+ (1,0) [0|7] "" Vector__XXX
 SG_ AEB_LePed_collisionprob : 63|1@0+ (1,0) [0|1] "" Vector__XXX
 SG_ AEB_RiPedDetn : 49|2@0+ (1,0) [0|3] "" Vector__XXX
 SG_ AEB_RiPedDy : 23|8@0+ (0.1,-8) [-8|8] "m" Vector__XXX
 SG_ AEB_RiPedTyp : 52|3@0+ (1,0) [0|7] "" Vector__XXX
 SG_ AEB_RiPed_collisionprob : 62|1@0+ (1,0) [0|1] "" Vector__XXX
 SG_ AEB_LeCyclistDy : 31|8@0+ (0.1,-8) [-8|8] "m" Vector__XXX
 SG_ AEB_LeCyclist_collisionprob : 61|1@0+ (1,0) [0|1] "" Vector__XXX
 SG_ AEB_RiCyclistDy : 39|8@0+ (0.1,-8) [-8|8] "m" Vector__XXX
 SG_ AEB_RiCyclist_collisionprob : 60|1@0+ (1,0) [0|1] "" Vector__XXX
 SG_ JAPedObjExist : 47|6@0+ (0.015625,0) [0|0.984375] "%"  HUT
 SG_ AEBJAObjID : 79|8@0+ (1,0) [0|255] ""  HUT
 SG_ AEBJAObjExist : 87|6@0+ (0.015625,0) [0|0.984375] "%"  HUT
 SG_ JAPedObjID : 119|8@0+ (1,0) [0|255] ""  HUT
 SG_ AEBJAObjVideoCfmd : 81|1@0+ (1,0) [0|1] ""  HUT
 SG_ AEBJAObjVx : 95|12@0+ (0.0625,-128) [-128|127] "ms"  HUT
 SG_ AEBJAObjDx : 99|12@0+ (0.0625,0) [0|255.9375] "m"  HUT
 SG_ JAPedObjVideoCfmd : 80|1@0+ (1,0) [0|1] ""  HUT
 SG_ AEBJAObjState : 127|3@0+ (1,0) [0|7] ""  HUT
 SG_ AEBJAObjCntAlive : 143|12@0+ (17,0) [0|65535] ""  HUT
 SG_ AEBJAObjDy : 147|11@0+ (0.125,-128) [-128|127.875] "m"  HUT
 SG_ JAPedObjState : 191|3@0+ (1,0) [0|7] ""  HUT
 SG_ AEBJAObjObstcl : 152|5@0+ (0.03125,0) [0|0.96875] "%"  HUT
 SG_ AEBJAObjVy : 163|10@0+ (0.125,-64) [-64|63.875] "ms"  HUT
 SG_ AEBJAObjAx : 169|10@0+ (0.03125,-16) [-16|15.96875] "ms2"  HUT
 SG_ AEBJAObjAy : 207|10@0+ (0.03125,-16) [-16|15.96875] "ms2"  HUT
 SG_ JAPedObjObstcl : 213|5@0+ (0.03125,0) [0|0.96875] "%"  HUT
 SG_ JAPedObjDy : 223|11@0+ (0.125,-128) [-128|127.875] "m"  HUT
 SG_ JAPedObjDx : 228|12@0+ (0.0625,0) [0|255.9375] "m"  HUT
 SG_ FCWAEB_JATTC : 247|6@0+ (0.1,0) [0|6.3] "s"  HUT
 SG_ JAPedObjVx : 271|12@0+ (0.0625,-128) [-128|127] "ms"  HUT
 SG_ JAPedObjVy : 295|10@0+ (0.125,-64) [-64|63.875] "ms"  HUT
 SG_ JAPedObjAy : 301|10@0+ (0.03125,-16) [-16|15.96875] "ms2"  HUT
 SG_ JAPedObjCntAlive : 275|12@0+ (17,0) [0|65535] ""  HUT
 SG_ FCWAEB_longTTC : 365|6@0+ (0.1,0) [0|6.3] "s"  HUT
 SG_ FCWAEB_crossingTTC : 375|6@0+ (0.1,0) [0|6.3] "s"  HUT
 SG_ JAPedObjAx : 335|10@0+ (0.03125,-16) [-16|15.96875] "ms2"  HUT
 SG_ AEB_LePedDx : 399|9@0+ (0.5,0) [0|150] "m" Vector__XXX
 SG_ AEB_RiPedDx : 406|9@0+ (0.5,0) [0|150] "m" Vector__XXX
 SG_ AEB_LeCyclistDetn : 413|2@0+ (1,0) [0|3] "" Vector__XXX
 SG_ AEB_LeCyclistDx : 423|9@0+ (0.5,0) [0|150] "m" Vector__XXX
 SG_ AEB_LeCyclistTyp : 411|3@0+ (1,0) [0|7] "" Vector__XXX
 SG_ AEB_RiCyclistDetn : 430|2@0+ (1,0) [0|3] "" Vector__XXX
 SG_ AEB_RiCyclistDx : 428|9@0+ (0.5,0) [0|150] "m" Vector__XXX
 SG_ AEB_RiCyclistTyp : 435|3@0+ (1,0) [0|7] "" Vector__XXX
 SG_ ACC_FD3_0x2B4 : 7|512@0+ (1,0) [0|0] ""  HUT

BO_ 778 RSDS_FD2: 64 GW
 SG_ RCTA_B_TTC : 15|6@0+ (0.1,0) [0|6.3] "s"  HUT
 SG_ BSD_LCA_Left_TTC : 9|6@0+ (0.1,0) [0|6.3] "s"  HUT
 SG_ BSD_LCA_Right_TTC : 19|6@0+ (0.1,0) [0|6.3] "s"  HUT
 SG_ RCW_TTC : 29|6@0+ (0.1,0) [0|6.3] "s"  HUT
 SG_ RSDS_LeTgt_01 : 79|1@0+ (1,0) [0|1] ""  HUT
 SG_ RSDS_LeTgt_01_dx : 87|10@0+ (0.1,-90) [-90|5] "m"  HUT
 SG_ RSDS_LeTgt_01_dy : 78|7@0+ (0.1,0) [0|8] "m"  HUT
 SG_ RSDS_LeTgt_02 : 93|1@0+ (1,0) [0|1] ""  HUT
 SG_ RSDS_LeTgt_02_dx : 92|10@0+ (0.1,-90) [-90|5] "m"  HUT
 SG_ RSDS_LeTgt_02_dy : 98|7@0+ (0.1,0) [0|8] "m"  HUT
 SG_ RSDS_RiTgt_01 : 107|1@0+ (1,0) [0|1] ""  HUT
 SG_ RSDS_RiTgt_01_dx : 106|10@0+ (0.1,-90) [-90|5] "m"  HUT
 SG_ RSDS_RiTgt_01_dy : 143|7@0+ (0.1,-8) [-8|0] "m"  HUT
 SG_ RSDS_RiTgt_02 : 136|1@0+ (1,0) [0|1] ""  HUT
 SG_ RSDS_RiTgt_02_dx : 151|10@0+ (0.1,-90) [-90|5] "m"  HUT
 SG_ RSDS_RiTgt_02_dy : 157|7@0+ (0.1,-8) [-8|0] "m"  HUT
 SG_ RSDS_MidTgt_01 : 166|1@0+ (1,0) [0|1] ""  HUT
 SG_ RSDS_MidTgt_01_dx : 165|10@0+ (0.1,-90) [-90|5] "m"  HUT
 SG_ RSDS_MidTgt_01_dy : 171|7@0+ (0.1,-4) [-4|4] "m"  HUT
 SG_ RSDS_MidTgt_02 : 180|1@0+ (1,0) [0|1] ""  HUT
 SG_ RSDS_MidTgt_02_dx : 207|10@0+ (0.1,-90) [-90|5] "m"  HUT
 SG_ RSDS_MidTgt_02_dy : 213|7@0+ (0.1,-4) [-4|4] "m"  HUT
 SG_ RSDS_FD2_0x30A : 7|512@0+ (1,0) [0|0] ""  HUT

BO_ 415 IFC_FD5: 64 GW
 SG_ IFC_Line01_Dy : 15|13@0+ (0.01,-30) [-30|30] "m"  HUT
 SG_ IFC_Line01_Curv : 18|15@0+ (1.6E-005,-0.25) [-0.25|0.25] "1m"  HUT
 SG_ IFC_Line01_CurvChange : 35|20@0+ (5E-008,-0.024) [-0.024|0.024] "1(m*m)"  HUT
 SG_ IFC_Line01_Type : 63|4@0+ (1,0) [0|15] ""  HUT
 SG_ IFC_Line02_Dy : 79|13@0+ (0.01,-30) [-30|30] "m"  HUT
 SG_ IFC_Line02_Curv : 82|15@0+ (1.6E-005,-0.25) [-0.25|0.25] "1m"  HUT
 SG_ IFC_Line02_CurvChange : 99|20@0+ (5E-008,-0.024) [-0.024|0.024] "1(m*m)"  HUT
 SG_ IFC_Line02_Type : 127|4@0+ (1,0) [0|15] ""  HUT
 SG_ IFC_Line03_Dy : 143|13@0+ (0.01,-30) [-30|30] "m"  HUT
 SG_ IFC_Line03_Curv : 146|15@0+ (1.6E-005,-0.25) [-0.25|0.25] "1m"  HUT
 SG_ IFC_Line03_CurvChange : 163|20@0+ (5E-008,-0.024) [-0.024|0.024] "1(m*m)"  HUT
 SG_ IFC_Line03_Type : 191|4@0+ (1,0) [0|15] ""  HUT
 SG_ IFC_Line04_Dy : 207|13@0+ (0.01,-30) [-30|30] "m"  HUT
 SG_ IFC_Line04_Curv : 210|15@0+ (1.6E-005,-0.25) [-0.25|0.25] "1m"  HUT
 SG_ IFC_Line04_CurvChange : 227|20@0+ (5E-008,-0.024) [-0.024|0.024] "1(m*m)"  HUT
 SG_ IFC_Line04_Type : 255|4@0+ (1,0) [0|15] ""  HUT
 SG_ IFC_Roadedge01_Dy : 271|13@0+ (0.01,-30) [-30|30] "m"  HUT
 SG_ IFC_Roadedge01_Curv : 274|15@0+ (1.6E-005,-0.25) [-0.25|0.25] "1m"  HUT
 SG_ IFC_Roadedge01_CurvChange : 291|20@0+ (5E-008,-0.024) [-0.024|0.024] "1(m*m)"  HUT
 SG_ IFC_Roadedge01_Type : 319|4@0+ (1,0) [0|15] ""  HUT
 SG_ IFC_Roadedge02_Dy : 335|13@0+ (0.01,-30) [-30|30] "m"  HUT
 SG_ IFC_Roadedge02_Curv : 338|15@0+ (1.6E-005,-0.25) [-0.25|0.25] "1m"  HUT
 SG_ IFC_Roadedge02_CurvChange : 355|20@0+ (5E-008,-0.024) [-0.024|0.024] "1(m*m)"  HUT
 SG_ IFC_Roadedge02_Type : 383|4@0+ (1,0) [0|15] ""  HUT
 SG_ IFC_FD5_0x19F : 7|512@0+ (1,0) [0|0] ""  HUT

BO_ 546 IFC_FD6: 64 GW
 SG_ IFC_Line01_DxStart : 15|15@0+ (0.01,0) [0|200] "m"  HUT
 SG_ IFC_Line01_DxEnd : 16|15@0+ (0.01,0) [0|200] "m"  HUT
 SG_ IFC_Line01_HeadingAngle : 33|9@0+ (0.01,-2) [-2|2] "rad"  HUT
 SG_ IFC_Line02_HeadingAngle : 40|9@0+ (0.01,-2) [-2|2] "rad"  HUT
 SG_ IFC_Line02_DxStart : 79|15@0+ (0.01,0) [0|200] "m"  HUT
 SG_ IFC_Line02_DxEnd : 95|15@0+ (0.01,0) [0|200] "m"  HUT
 SG_ IFC_Line03_DxStart : 111|15@0+ (0.01,0) [0|200] "m"  HUT
 SG_ IFC_Line03_DxEnd : 143|15@0+ (0.01,0) [0|200] "m"  HUT
 SG_ IFC_Line03_HeadingAngle : 144|9@0+ (0.01,-2) [-2|2] "rad"  HUT
 SG_ IFC_Line04_DxStart : 167|15@0+ (0.01,0) [0|200] "m"  HUT
 SG_ IFC_Line04_HeadingAngle : 168|9@0+ (0.01,-2) [-2|2] "rad"  HUT
 SG_ IFC_Line04_DxEnd : 207|15@0+ (0.01,0) [0|200] "m"  HUT
 SG_ IFC_Roadedge01_DxStart : 223|15@0+ (0.01,0) [0|200] "m"  HUT
 SG_ IFC_Roadedge01_DxEnd : 239|15@0+ (0.01,0) [0|200] "m"  HUT
 SG_ IFC_Roadedge01_HeadingAngle : 271|9@0+ (0.01,-2) [-2|2] "rad"  HUT
 SG_ IFC_Roadedge02_DxStart : 278|15@0+ (0.01,0) [0|200] "m"  HUT
 SG_ IFC_Roadedge02_DxEnd : 295|15@0+ (0.01,0) [0|200] "m"  HUT
 SG_ IFC_Roadedge02_HeadingAngle : 296|9@0+ (0.01,-2) [-2|2] "rad"  HUT
 SG_ IFC_FD6_0x222 : 7|512@0+ (1,0) [0|0] ""  HUT

BO_ 705 DSM1: 8 GW
 SG_ ChairMemPosnSetSwtFB : 11|3@0+ (1,0) [0|7] ""  HUT
 SG_ DrvSeatMassgModeSts : 26|3@0+ (1,0) [0|7] ""  HUT
 SG_ DrvSeatMassgLvlSetSts : 39|3@0+ (1,0) [0|7] ""  HUT
 SG_ DrvSeatLumSMAdjSts : 36|3@0+ (1,0) [0|7] ""  HUT
 SG_ DSM1_0x2C1 : 7|64@0+ (1,0) [0|0] ""  HUT

BO_ 491 HUT39: 8 HUT
 SG_ DrvSeatMassgLvlSet : 23|3@0+ (1,0) [0|7] ""  GW
 SG_ DrvSeatMassgModSet : 33|3@0+ (1,0) [0|7] ""  GW
 SG_ DrvBehvTestSetUp : 17|2@0+ (1,0) [0|3] ""  DMS
 SG_ GazeAreaIntracSetUp : 25|2@0+ (1,0) [0|3] ""  DMS
 SG_ HUT39_0x1EB : 7|64@0+ (1,0) [0|0] "" Vector__XXX

BO_ 694 HUT26: 8 HUT
 SG_ DrvSeatSupportPosnSwt : 35|3@0+ (1,0) [0|7] ""  GW
 SG_ HUT26_0x2B6 : 7|64@0+ (1,0) [0|0] "" Vector__XXX

BO_ 963 GMCU_FD3: 8 GW
 SG_ GMCU_MotorSerNumber_RM : 7|8@0+ (1,0) [1|253] ""  T_Box
 SG_ GMCU_InvActTemp_RM : 23|8@0+ (1,-40) [-40|210] "Â°C"  T_Box
 SG_ GMCU_ActSpd_RM : 31|16@0+ (1,-20000) [-20000|45531] "rpm"  T_Box
 SG_ GMCU_ActTrq_RM : 47|16@0+ (0.1,-2000) [-2000|4553.1] "Nm"  T_Box

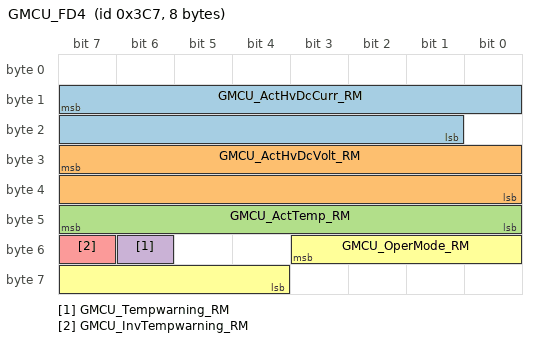
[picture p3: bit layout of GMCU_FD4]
BO_ 967 GMCU_FD4: 8 GW
 SG_ GMCU_ActHvDcCurr_RM : 15|15@0+ (0.1,-1000) [-1000|1000] "A"  T_Box
 SG_ GMCU_ActHvDcVolt_RM : 31|16@0+ (0.1,0) [0|6000] "V"  T_Box
 SG_ GMCU_ActTemp_RM : 47|8@0+ (1,-40) [-40|210] "Â°C"  T_Box
 SG_ GMCU_Tempwarning_RM : 54|1@0+ (1,0) [0|1] ""  T_Box
 SG_ GMCU_InvTempwarning_RM : 55|1@0+ (1,0) [0|1] ""  T_Box
 SG_ GMCU_OperMode_RM : 51|8@0+ (1,0) [0|255] ""  T_Box

BO_ 763 VMDR1: 8 GW
 SG_ MbrMonrEnaSts : 15|1@0+ (1,0) [0|1] ""  HUT
 SG_ VMDR1_0x2FB : 7|64@0+ (1,0) [0|0] ""  HUT

BO_ 731 ALCM1: 8 GW
 SG_ ALCMSwtSts : 8|1@0+ (1,0) [0|1] ""  HUT
 SG_ ALCM1_0x2DB : 7|64@0+ (1,0) [0|0] ""  HUT

BO_ 1888 DiagFuncReq: 8 Tester
 SG_ DiagFuncReq : 7|64@0+ (1,0) [0|1.84467440737096E+019] ""  GW,T_Box,HUT,DMS,DVR

BO_ 1889 GW_Phy_Req: 8 Tester
 SG_ GW_Phy_Req : 7|64@0+ (1,0) [0|1.84467440737096E+019] ""  GW

BO_ 1918 T_Box_Phy_Req: 8 Tester
 SG_ T_Box_Phy_Req : 7|64@0+ (1,0) [0|1.84467440737096E+019] ""  GW,T_Box

BO_ 1907 HUT_Phy_Req: 8 Tester
 SG_ HUT_Phy_Req : 7|64@0+ (1,0) [0|1.84467440737096E+019] ""  GW,HUT

BO_ 1566 DMS_Phy_Req: 8 Tester
 SG_ DMS_Phy_Req : 7|64@0+ (1,0) [0|1.84467440737096E+019] ""  GW,DMS

BO_ 1560 DVR_Phy_Req: 8 Tester
 SG_ DVR_Phy_Req : 7|64@0+ (1,0) [0|1.84467440737096E+019] ""  GW,DVR

BO_ 1953 GW_Phy_Resp: 8 GW
 SG_ GW_Phy_Resp : 7|64@0+ (1,0) [0|1.84467440737096E+019] ""  Tester

BO_ 1982 T_Box_Phy_Resp: 8 T_Box
 SG_ T_Box_Phy_Resp : 7|64@0+ (1,0) [0|1.84467440737096E+019] ""  GW

BO_ 1971 HUT_Phy_Resp: 8 HUT
 SG_ HUT_Phy_Resp : 7|64@0+ (1,0) [0|1.84467440737096E+019] ""  GW,Tester

BO_ 1567 DMS_Phy_Resp: 8 DMS
 SG_ DMS_Phy_Resp : 7|64@0+ (1,0) [0|1.84467440737096E+019] ""  GW,Tester

BO_ 1561 DVR_Phy_Resp: 8 DVR
 SG_ DVR_Phy_Resp : 7|64@0+ (1,0) [0|1.84467440737096E+019] ""  GW,Tester

BO_ 1290 T_Box_NM: 8 T_Box
 SG_ Destination_T_Box_NM : 7|8@0+ (1,0) [0|255] ""  GW,HUT,DMS,DVR
 SG_ OpCode_T_Box_NM : 15|8@0+ (1,0) [0|255] ""  GW,HUT,DMS,DVR

BO_ 1289 HUT_NM: 8 HUT
 SG_ Destination_HUT_NM : 7|8@0+ (1,0) [0|255] ""  GW,T_Box,DMS,DVR
 SG_ OpCode_HUT_NM : 15|8@0+ (1,0) [0|255] ""  GW,T_Box,DMS,DVR

BO_ 1302 DMS_NM: 8 DMS
 SG_ Destination_DMS_NM : 7|8@0+ (1,0) [0|255] ""  GW,T_Box,HUT,DVR
 SG_ OpCode_DMS_NM : 15|8@0+ (1,0) [0|255] ""  GW,T_Box,HUT,DVR

BO_ 1303 DVR_NM: 8 DVR
 SG_ Destination_DVR_NM : 7|8@0+ (1,0) [0|255] ""  GW,T_Box,HUT,DMS
 SG_ OpCode_DVR_NM : 15|8@0+ (1,0) [0|255] ""  GW,T_Box,HUT,DMS

BO_ 1281 GW_NM: 8 GW
 SG_ Destination_GW_NM : 7|8@0+ (1,0) [0|255] ""  T_Box,HUT,DMS,DVR
 SG_ OpCode_GW_NM : 15|8@0+ (1,0) [0|255] ""  T_Box,HUT,DMS,DVR

BO_ 1122 HUT_Sync_Req: 16 HUT
 SG_ SyncRequestMessageId : 7|8@0+ (1,0) [0|0] ""  GW
 SG_ SyncRequstReseverData : 15|56@0+ (1,0) [0|0] ""  GW
 SG_ HUT_Sync_Req_0x462 : 7|128@0+ (1,0) [0|0] "" Vector__XXX

BO_ 1121 GW_Sync_Req: 16 GW
 SG_ ResetCount : 31|16@0+ (1,0) [0|0] ""  HUT
 SG_ CMACMessageInfo : 47|88@0+ (1,0) [0|0] ""  HUT
 SG_ TripCount : 7|24@0+ (1,0) [0|0] ""  HUT

CM_ SG_ 482 HCU_PhoneChrgnModeResp "After HCU received signal\"Phone_ChrgnMode\" , HCU shall make a Response to TBOX to confirm wether received successful or not";
CM_ SG_ 482 HCU_PhoneChrgnReqResp "After HCU received signal\"Phone_ChrgnReq\" , HCU shall make a Response to TBOX to confirm wether received successful or not";
CM_ SG_ 482 HCU_HUTChrgnModeResp "After HCU received signal\"HUT_ChrgnMode\" , HCU shall make a Response to TBOX to confirm wether received successful or not";
CM_ SG_ 482 HCU_HUTChrgnReqResp "After HCU received signal\"HUT_ChrgnReq\" , HCU shall make a Response to TBOX to confirm wether received successful or not";
CM_ SG_ 482 HCU_TboxEngStrtReq "Start engine request by Cellphone operation for Intelligent Engine";
CM_ SG_ 482 HCU_TotalScore "the Total score of the  driverâ€˜s drive style and  energy consumption in this dirve cycle";
CM_ SG_ 482 HCU_IntelBattTempMagResp "Intelligent Battery Temperature Management Setting Request";
CM_ SG_ 482 HCU_RemtVehStartReq "Vehicle  Remot start request";
CM_ SG_ 909 HCU_PowertrainSts_RM "Powertrain Status.";
CM_ SG_ 909 HCU_ChargSts_RM "Charging  statue";
CM_ SG_ 909 HCU_PTDrvMod_RM "Powertrain current drive mode";
CM_ SG_ 909 HCU_Powerflag_RM "Power flag";
CM_ SG_ 909 HCU_AccelPedalPosn_Diag_RM "Physical acceleration pedal position.
it represents the physical value of acceleration pedal even in CCACC case, in which case normal acceleration pedal is replaced by virtual pedal position.";
CM_ SG_ 909 HCU_BrkPedalSts_RM "indicates the brake pedal is pressed or not or incorrect for
plausibility check.";
CM_ SG_ 909 HCU_DrvPower_RM "the drive power status to T_Box";
CM_ SG_ 909 HCU_BrkPower_RM "the brake power status to T_Box";
CM_ SG_ 909 HCU_GearSts_RM "the gear status to T_Box";
CM_ SG_ 241 CheckSum_BMS4 "Use the checksum strategy from document â€œEnd-to-End Communication Protection Specificationâ€";
CM_ SG_ 241 BMS_PowerDownCmplt "BMS power down complete .
BMS Inform HCU All Main relay have been open";
CM_ SG_ 241 BMS_BattPoweErr "Battray  Power Error";
CM_ SG_ 241 BMS_ErrCategory "BMS error CategoryIP Received
P0:
0x0:No Error
0x1:Warning
0x2:Derating
0x3:Reserved
0x4:Reserved
0x5:Error
0x6:Reserved
0x7:Emergency Open
P2+P4HEVPHEV:
0x0:No Error
0x1:Warning
0x2:Derating
0x3:Instrument Displayï¼ˆYellowï¼‰
0x4:Range Limitedï¼ˆYellowï¼‰
0x5:Pre-charge Lockedï¼ˆRedï¼‰
0x6:Delayed Openï¼ˆRedï¼‰
0x7:Emergency Open(Red)";
CM_ SG_ 241 BMS_PackCurr "Pack CurrentIP Received
positive value :discharging
negative value : charging";
CM_ SG_ 241 BMS_PackVolt "Pack VoltageIP Received";
CM_ SG_ 241 RollingCounter_BMS4 "Rolling counter BMS4";
CM_ SG_ 645 BMS_BattHeatRunaway "Battery  Heat  Runaway";
CM_ SG_ 708 BMS_BattSOC "Battery SOCIP Received";
CM_ SG_ 708 BMS_BattSOCLimResp "After BMS received signal\"BattSOCLim\" , BMS shall make a Response to confirm wether received successful or not";
CM_ SG_ 850 BMS_RemtPreHeatSts "Battery remote reservation heating Status feedback";
CM_ SG_ 850 BMS_BattKeepTempSts "Battery Keep Temperature state";
CM_ SG_ 850 BMS_IntelEngIdlChrgnSts "Intelligent Engine Idle Charging status";
CM_ SG_ 959 BMS_ChrgDurationTime "Charge Duration Time in minute";
CM_ SG_ 976 BMS_BattTempMax "Battery max temperature of module temperature";
CM_ SG_ 976 BMS_BattTempMin "Battery min temperature of module temperature";
CM_ SG_ 1009 BMS_CellUnderVolt "cell under voltage";
CM_ SG_ 1009 BMS_CellOverVolt "cell over voltage warning";
CM_ SG_ 1009 BMS_CellDeltaVolt "cell delta voltage is too larger";
CM_ SG_ 1009 BMS_BattUnderVolt "pack under voltage";
CM_ SG_ 1009 BMS_BattOverVolt "pack over voltage";
CM_ SG_ 1009 BMS_BattUnderTemp "battery temperature is too lower";
CM_ SG_ 1009 BMS_SOC_Plaucheck "Compared with last cycle SOC";
CM_ SG_ 1009 BMS_DeltaTemp "delta temperature is too big";
CM_ SG_ 1009 BMS_CANComErr "BMS CAN communication fault";
CM_ SG_ 1009 BMS_SOCLowWarn "SOC is too low,need to charge,IP need light the lamp.IP receive";
CM_ SG_ 1009 BMS_BattSOCLow "SOC is lower";
CM_ SG_ 1009 BMS_BattSOCTooLow "SOC is too lower";
CM_ SG_ 1009 BMS_BattSOCHigh "SOC is too higher";
CM_ SG_ 1009 BMS_ChrgnCurrLager "charging current is too larger";
CM_ SG_ 1009 BMS_DischrgnCurrLager "discharging current is too larger";
CM_ SG_ 1009 BMS_ModuleMismatchWarn "mismatch warning of module";
CM_ SG_ 1009 BMS_cohrnc "coherence of power battery is bad";
CM_ SG_ 1009 BMS_moduleNumber "number of module";
CM_ SG_ 1009 BMS_NumModuleTempSnsr "number of module temperature sensor";
CM_ SG_ 1009 BMS_NumCell "number of cell";
CM_ SG_ 1010 BMS_CellVoltMin "minimal voltage of cell";
CM_ SG_ 1010 BMS_NumberCellVoltMin "number of minimal voltage of cell";
CM_ SG_ 1010 BMS_CellMaxVolt "maximal voltage of cell";
CM_ SG_ 1010 BMS_NumberCellMaxVolt "number of maximal voltage of cell";
CM_ SG_ 1010 BMS_CellBalanceSts "cell balance state";
CM_ SG_ 1010 BMS_RlyCounterSts "BMS relay counter status";
CM_ SG_ 1010 BMS_SOH_R "SOH( resistance) value";
CM_ SG_ 1011 BMS_ModuleMinTemp "minimal temperature of module";
CM_ SG_ 1011 BMS_ModuleNumCellMinTemp "module number of minimal temperature of cell";
CM_ SG_ 1011 BMS_ModuleNumCellMaxTemp "module number of maximal temperature of cell";
CM_ SG_ 1011 BMS_ModuleMaxTemp "maximal temperature of module";
CM_ SG_ 1011 BMS_NumCellMinTemp "number of minimal temperature of Cell";
CM_ SG_ 1011 BMS_NumCellMaxTemp "number of maximal temperature of Cell";
CM_ SG_ 1011 BMS_BattOverTempWarn "battery temperature is too higher";
CM_ SG_ 1011 BMS_ModuleNumberCellMinVolt "module number of minimal voltage of cell";
CM_ SG_ 1011 BMS_ModuleNumberCellMaxVolt "module number of minimal voltage of cell";
CM_ SG_ 790 OBC_ModSts "mode status of charger";
CM_ SG_ 791 OBC_ConnectSts "OBC charge connect statusIP Received";
CM_ SG_ 96 HCU_AccelPedalPosn_Diag "Physical acceleration pedal position.
it represents the physical value of acceleration pedal even in CCACC case, in which case normal acceleration pedal is replaced by virtual pedal position.IP Received";
CM_ SG_ 96 HCU_AccelPedalPosn_DiagValid "Flag: Physical acceleration pedal position validIP Received";
CM_ SG_ 96 TMCU_ActRotSpd "Actual mechanical speed of EM(Electric Motor)
Actual Positive rotation speed TM(Traction Motor)";
CM_ SG_ 96 HCU_PowertrainSts "Powertrain Status.";
CM_ SG_ 96 HCU_RaceLaunchSts "Race Launch function is active or deactivateIP Received";
CM_ SG_ 96 HCU_RaceLaunchAvail "HCU Race Launch AvailIP Received";
CM_ SG_ 330 HCU_DrvMod "Represents currently active driving mode. It is also used to transmit terrain response modes (sand mud snow)HUTIP Received
P2é¡¹ç›®codingå‘é€:
0x0:AutoNormal Mode started
0x1:EV Mode started
0x2:Save Mode started
0x3:SPORT Mode started
0x5:Snow Mode started
0x8:ECO
0x9-0xF:Reserved
P2+P4HEVPHEVé¡¹ç›®codingå‘é€:
0x0:AutoNormal Mode started
0x1:EV Mode started
0x2:Save Mode started
0x3:SPORT Mode started
0x4:AWD Normal Mode started
0x5:Snow Mode started
0x6:Muddy Mode started
0x7:Sand Mode started
0x8:ECO
0x9-0xF:Reserved";
CM_ SG_ 330 HCUImmoAuthRes "Immo authorisation resultIP";
CM_ SG_ 330 HCU_EVLmpSts "EV lamp signalIP";
CM_ SG_ 330 HCU_ECODrvHabit_Indcn "Economic Indication of driving habitsIP";
CM_ SG_ 330 HCU_TotDrvReqPower "total driver request PowerIP";
CM_ SG_ 330 HCU_AvailPower_TM "rear emotor available powerIP";
CM_ SG_ 584 CheckSum_HCU_PT7 "Use the checksum strategy from document â€œEnd-to-End Communication Protection Specificationâ€";
CM_ SG_ 584 HCU_HybSysErr_1 "Hybrid error indicate word: Hybrid system error stop the vehicle in a safety place.IP";
CM_ SG_ 584 HCU_HybSysErr_2 "Hybrid error indicate word: Hybrid system not available due to collision .IP";
CM_ SG_ 584 HCU_HybSysErr_3 "Hybrid error indicate word: Hybrid system error ,go to the service piont.IP";
CM_ SG_ 584 HCU_HybSysErr_4 "Hybrid error indicate word:Drive system error,go to the service pointIP";
CM_ SG_ 584 HCU_HybSysErr_5 "Hybrid error indicate word: BSG system error ï¼Œgo to the service piont.IP";
CM_ SG_ 584 HCU_HybSysErr_6 "Hybrid error indicate word:  temporary hybrid system limitations drive carefullyIP";
CM_ SG_ 584 HCU_HybSysErr_7 "Hybrid error indicate word: Braking energy recovery system error,go to the service piont.IP";
CM_ SG_ 584 HCU_12VSysErrLmpSts "12V system error indicate lamp  statusIP";
CM_ SG_ 584 HCU_HybSysErrLmpSts "Hybrid system error  indicate lamp statusIP";
CM_ SG_ 584 HCU_PowerRedWarnLmpCmd "The power reduction warning lamp comes on. Whenever a power reduction warning happens.IP";
CM_ SG_ 584 HCU_12VSysErr_1 "12V system error indicate word:12V system error ï¼Œstop the vehicle in a safety place.IP";
CM_ SG_ 584 HCU_12VSysErr_2 "12V system error indicate word:12V system error ï¼Œgo to the service piont.IP";
CM_ SG_ 584 HCU_RdyLmpSts "READY lamp  statusIP";
CM_ SG_ 584 HCU_ModSwtFail "Mode Switch Failure prompt MessageIPHUT Received";
CM_ SG_ 584 HCU_EnrgFlowInd "the mode of current energy flowIP Received";
CM_ SG_ 584 HCU_OPDSts "One Pedal Driving StatusIP Received";
CM_ SG_ 584 HCU_OPDLmpSts "OPD indicator light requestIP Received";
CM_ SG_ 584 RollingCounter_HCU_PT7 "Rolling counter";
CM_ SG_ 448 HCU_ChrgSysLmpSts "Charge system indicate lamp statusIP Received";
CM_ SG_ 448 HCU_ChrgSysErr_1 "Charge system error indicate word:On board charger errorï¼Œ go to the service piont.IP Received";
CM_ SG_ 448 HCU_ChrgSysErr_2 "Charge system error indicate word: Charge system errorï¼Œ charging stoppedIP Received";
CM_ SG_ 448 HCU_ChrgSysErr_3 "Charge system error indicate word:  Charging stopped due to insuff power supply lowIP Received";
CM_ SG_ 448 HCU_ChrgSysErr_4 "Charge system error indicate word:  Charging stopped due to charger over temperatureIP Received";
CM_ SG_ 448 HCU_ChrgSysErr_5 "Charge system error indicate word:  Charging stopped due to battery over temperatureIP Received";
CM_ SG_ 448 HCU_ChrgSysErr_6 "Charge system error indicate word:  Charging stopped due to  battery temperature lowIP Received";
CM_ SG_ 448 HCU_ChrgSysErr_7 "Charge system error indicate word:  Charger output power  lowIP Received";
CM_ SG_ 448 HCU_ChrgSysErr_8 "Charge system error indicate word:  Charging stopped due to charge line not connect rightIP Received";
CM_ SG_ 762 CheckSum_HCU_PT4 "Use the checksum strategy from document â€œEnd-to-End Communication Protection Specificationâ€";
CM_ SG_ 762 HCU_BattPowerRedWarn "battery power reduction warningIP Received";
CM_ SG_ 762 HCU_EnerSavePowerMod "Storage battery power low active , vehicle enter save power mode.HUT";
CM_ SG_ 762 HCU_SOCLow_Indcn "Indicate word:
Battery lowï¼Œcharge immediatelyIP Received";
CM_ SG_ 762 HCU_RemoveChrgLine_Indcn "Indicate word:
Remove the charge lineIP Received";
CM_ SG_ 762 HCU_WadeModeSetSts "Feedback Wade Mode status to HUTHUT";
CM_ SG_ 762 HCU_Shift_P_Indcn "Indicate word:
Shift to P gear levelIP Received";
CM_ SG_ 762 HCU_ConnectChrgLine_Indcn "Indicate word:
connect  the charge lineIP Received";
CM_ SG_ 762 HCU_EgyRecFB "Energy recuperation FeedbackHUT";
CM_ SG_ 762 HCU_ACStsReq "AC status requestHUT";
CM_ SG_ 762 HCU_RefuReq "HCU refueling  RequestIP Received";
CM_ SG_ 762 HCU_OilTankCoverSts "Oil tank cover status";
CM_ SG_ 762 HCU_InhbChrgInfo "Inhibit Charge InformationIP Received";
CM_ SG_ 762 OPDParkWarnReq "OPD Parking Warning Request";
CM_ SG_ 762 HCU_OPDFail "One Pedal Driving Failure Status";
CM_ SG_ 762 CarWashMode_StsDisp "CarWashMode status display";
CM_ SG_ 762 CarWashMode_Sts "Car Wash Mode status";
CM_ SG_ 762 HCU_RefuBtnSts "Refueling button status";
CM_ SG_ 762 RollingCounter_HCU_PT4 "Rolling counter";
CM_ SG_ 513 Checksum_HCU_HP5 "Use the checksum strategy from document â€œEnd-to-End Communication Protection Specificationâ€";
CM_ SG_ 513 HCU_EnrgFlowInd_DHT "the mode of current energy flowHUT";
CM_ SG_ 513 HCU_PrsBrkWarn "Press brake to engage gear";
CM_ SG_ 513 DrvModDisp_0x201 "Driver display drive mode valueIP Received";
CM_ SG_ 513 DrvModDispSts_0x201 "Driver display drive mode statusIP Received";
CM_ SG_ 513 DrvGearDisp "Driver display gear valueIP Received";
CM_ SG_ 513 DrvGearDispSts_0x201 "Driver display gear statusIP Received";
CM_ SG_ 513 HCU_ShftNotAlwd_Warn "gear lever not allowed to switch warning messageIP Received";
CM_ SG_ 513 DrvFaiMsg_0x201 "Driver display failure messagesIP Received";
CM_ SG_ 513 RollingCounter_HCU_HP5 "Rolling counter";
CM_ SG_ 288 IB_Warn "iBooster requests the yellow warning lamp in the dashboardIP Received";
CM_ SG_ 200 ESP_HMI_WarningOn "ESP requests the warning lamp in the dashboardIP Received";
CM_ SG_ 216 TgtRcprtnTrqSts "Status of Target Recuperation torque of GeneratorIP Received";
CM_ SG_ 957 DCDC_Tempwarning_RM "DCDC temperapure warning for  remote monitor";
CM_ SG_ 957 DCDC_ActSts_RM "DCDC states";
CM_ SG_ 957 DCDC_FailStswarning_RM "DCDC state warning for  remote monitor";
CM_ SG_ 969 TMCU_Amount_RM "Actual amount of E-motor for  remote monitor";
CM_ SG_ 969 TMCU_MotorSerNumber_RM "Actual serial number of E-motor for  remote monitor";
CM_ SG_ 969 TMCU_InvActTemp_RM "Actual Virtual Junction Temperature state of hottest Inverter Power-Semiconductor";
CM_ SG_ 969 TMCU_ActSpd_RM "Actual mechanical speed of EM(Electric Motor)";
CM_ SG_ 969 TMCU_ActTrq_RM "Actual torque at EM(Electric Motor)   shaft";
CM_ SG_ 948 TMCU_ActHvDcCurr_RM "Actual HV DC(High Voltage Direct Current link) Current";
CM_ SG_ 948 TMCU_ActHvDcVolt_RM "Actual HV DC(High Voltage Direct Current) voltage";
CM_ SG_ 948 TMCU_ActTemp_RM "Actual Temperature of hottest sensor element in EM(Electric Motor)  Winding";
CM_ SG_ 948 TMCU_Tempwarning_RM "Actual Temperature warrning of hottest sensor element in EM(Electric Motor)  Winding";
CM_ SG_ 948 TMCU_InvTempwarning_RM "Actual Temperature warrning of hottest sensor element in EM Inverter(Electric Motor)  Winding";
CM_ SG_ 948 TMCU_OperMode_RM "Actual operation mode of Actuation Motor";
CM_ SG_ 977 BMS_BattModuleTe_11 "module temperature of power battery_1";
CM_ SG_ 977 BMS_BattModuleTe_12 "module temperature of power battery_1";
CM_ SG_ 977 BMS_BattModuleTe_21 "module temperature of power battery_2";
CM_ SG_ 977 BMS_BattModuleTe_22 "module temperature of power battery_2";
CM_ SG_ 977 BMS_BattModuleTe_31 "module temperature of power battery_3";
CM_ SG_ 977 BMS_BattModuleTe_32 "module temperature of power battery_3";
CM_ SG_ 977 BMS_BattModuleTe_41 "module temperature of power battery_4";
CM_ SG_ 977 BMS_BattModuleTe_42 "module temperature of power battery_4";
CM_ SG_ 977 BMS_BattModuleTe_51 "module temperature of power battery_5";
CM_ SG_ 977 BMS_BattModuleTe_52 "module temperature of power battery_5";
CM_ SG_ 977 BMS_BattModuleTe_61 "module temperature of power battery_6";
CM_ SG_ 977 BMS_BattModuleTe_62 "module temperature of power battery_6";
CM_ SG_ 977 BMS_BattModuleTe_71 "module temperature of power battery_7";
CM_ SG_ 977 BMS_BattModuleTe_72 "module temperature of power battery_7";
CM_ SG_ 977 BMS_BattModuleTe_81 "module temperature of power battery_8";
CM_ SG_ 977 BMS_BattModuleTe_82 "module temperature of power battery_8";
CM_ SG_ 977 BMS_SingleCellVolt_1 "Single cell vlotage of power battery1";
CM_ SG_ 977 BMS_SingleCellVolt_2 "Single cell vlotage of power battery2";
CM_ SG_ 977 BMS_SingleCellVolt_3 "Single cell vlotage of power battery3";
CM_ SG_ 977 BMS_SingleCellVolt_4 "Single cell vlotage of power battery4";
CM_ SG_ 977 BMS_SingleCellVolt_5 "Single cell vlotage of power battery5";
CM_ SG_ 977 BMS_SingleCellVolt_6 "Single cell vlotage of power battery6";
CM_ SG_ 977 BMS_SingleCellVolt_7 "Single cell vlotage of power battery7";
CM_ SG_ 977 BMS_SingleCellVolt_8 "Single cell vlotage of power battery8";
CM_ SG_ 977 BMS_SingleCellVolt_9 "Single cell vlotage of power battery9";
CM_ SG_ 977 BMS_SingleCellVolt_10 "Single cell vlotage of power battery10";
CM_ SG_ 977 BMS_SingleCellVolt_11 "Single cell vlotage of power battery11";
CM_ SG_ 977 BMS_SingleCellVolt_12 "Single cell vlotage of power battery12";
CM_ SG_ 978 BMS_SingleCellVolt_13 "Single cell vlotage of power battery13";
CM_ SG_ 978 BMS_SingleCellVolt_14 "Single cell vlotage of power battery14";
CM_ SG_ 978 BMS_SingleCellVolt_15 "Single cell vlotage of power battery15";
CM_ SG_ 978 BMS_SingleCellVolt_16 "Single cell vlotage of power battery16";
CM_ SG_ 978 BMS_SingleCellVolt_17 "Single cell vlotage of power battery17";
CM_ SG_ 978 BMS_SingleCellVolt_18 "Single cell vlotage of power battery18";
CM_ SG_ 978 BMS_SingleCellVolt_19 "Single cell vlotage of power battery19";
CM_ SG_ 978 BMS_SingleCellVolt_20 "Single cell vlotage of power battery20";
CM_ SG_ 978 BMS_SingleCellVolt_21 "Single cell vlotage of power battery21";
CM_ SG_ 978 BMS_SingleCellVolt_22 "Single cell vlotage of power battery22";
CM_ SG_ 978 BMS_SingleCellVolt_23 "Single cell vlotage of power battery23";
CM_ SG_ 978 BMS_SingleCellVolt_24 "Single cell vlotage of power battery24";
CM_ SG_ 978 BMS_SingleCellVolt_25 "Single cell vlotage of power battery25";
CM_ SG_ 978 BMS_SingleCellVolt_26 "Single cell vlotage of power battery26";
CM_ SG_ 978 BMS_SingleCellVolt_27 "Single cell vlotage of power battery27";
CM_ SG_ 978 BMS_SingleCellVolt_28 "Single cell vlotage of power battery28";
CM_ SG_ 978 BMS_SingleCellVolt_29 "Single cell vlotage of power battery29";
CM_ SG_ 978 BMS_SingleCellVolt_30 "Single cell vlotage of power battery30";
CM_ SG_ 978 BMS_SingleCellVolt_31 "Single cell vlotage of power battery31";
CM_ SG_ 978 BMS_SingleCellVolt_32 "Single cell vlotage of power battery32";
CM_ SG_ 978 BMS_SingleCellVolt_33 "Single cell vlotage of power battery33";
CM_ SG_ 978 BMS_SingleCellVolt_34 "Single cell vlotage of power battery34";
CM_ SG_ 978 BMS_SingleCellVolt_35 "Single cell vlotage of power battery35";
CM_ SG_ 978 BMS_SingleCellVolt_36 "Single cell vlotage of power battery36";
CM_ SG_ 978 BMS_SingleCellVolt_37 "Single cell vlotage of power battery37";
CM_ SG_ 978 BMS_SingleCellVolt_38 "Single cell vlotage of power battery38";
CM_ SG_ 978 BMS_SingleCellVolt_39 "Single cell vlotage of power battery39";
CM_ SG_ 978 BMS_SingleCellVolt_40 "Single cell vlotage of power battery40";
CM_ SG_ 979 BMS_SingleCellVolt_41 "Single cell vlotage of power battery41";
CM_ SG_ 979 BMS_SingleCellVolt_42 "Single cell vlotage of power battery42";
CM_ SG_ 979 BMS_SingleCellVolt_43 "Single cell vlotage of power battery43";
CM_ SG_ 979 BMS_SingleCellVolt_44 "Single cell vlotage of power battery44";
CM_ SG_ 979 BMS_SingleCellVolt_45 "Single cell vlotage of power battery45";
CM_ SG_ 979 BMS_SingleCellVolt_46 "Single cell vlotage of power battery46";
CM_ SG_ 979 BMS_SingleCellVolt_47 "Single cell vlotage of power battery47";
CM_ SG_ 979 BMS_SingleCellVolt_48 "Single cell vlotage of power battery48";
CM_ SG_ 979 BMS_SingleCellVolt_49 "Single cell vlotage of power battery49";
CM_ SG_ 979 BMS_SingleCellVolt_50 "Single cell vlotage of power battery50";
CM_ SG_ 979 BMS_SingleCellVolt_51 "Single cell vlotage of power battery51";
CM_ SG_ 979 BMS_SingleCellVolt_52 "Single cell vlotage of power battery52";
CM_ SG_ 979 BMS_SingleCellVolt_53 "Single cell vlotage of power battery53";
CM_ SG_ 979 BMS_SingleCellVolt_54 "Single cell vlotage of power battery54";
CM_ SG_ 979 BMS_SingleCellVolt_55 "Single cell vlotage of power battery55";
CM_ SG_ 979 BMS_SingleCellVolt_56 "Single cell vlotage of power battery56";
CM_ SG_ 979 BMS_SingleCellVolt_57 "Single cell vlotage of power battery57";
CM_ SG_ 979 BMS_SingleCellVolt_58 "Single cell vlotage of power battery58";
CM_ SG_ 979 BMS_SingleCellVolt_59 "Single cell vlotage of power battery59";
CM_ SG_ 979 BMS_SingleCellVolt_60 "Single cell vlotage of power battery60";
CM_ SG_ 979 BMS_SingleCellVolt_61 "Single cell vlotage of power battery61";
CM_ SG_ 979 BMS_SingleCellVolt_62 "Single cell vlotage of power battery62";
CM_ SG_ 979 BMS_SingleCellVolt_63 "Single cell vlotage of power battery63";
CM_ SG_ 979 BMS_SingleCellVolt_64 "Single cell vlotage of power battery64";
CM_ SG_ 979 BMS_SingleCellVolt_65 "Single cell vlotage of power battery65";
CM_ SG_ 979 BMS_SingleCellVolt_66 "Single cell vlotage of power battery66";
CM_ SG_ 979 BMS_SingleCellVolt_67 "Single cell vlotage of power battery67";
CM_ SG_ 979 BMS_SingleCellVolt_68 "Single cell vlotage of power battery68";
CM_ SG_ 980 BMS_SingleCellVolt_69 "Single cell vlotage of power battery69";
CM_ SG_ 980 BMS_SingleCellVolt_70 "Single cell vlotage of power battery70";
CM_ SG_ 980 BMS_SingleCellVolt_71 "Single cell vlotage of power battery71";
CM_ SG_ 980 BMS_SingleCellVolt_72 "Single cell vlotage of power battery72";
CM_ SG_ 980 BMS_SingleCellVolt_73 "Single cell vlotage of power battery73";
CM_ SG_ 980 BMS_SingleCellVolt_74 "Single cell vlotage of power battery74";
CM_ SG_ 980 BMS_SingleCellVolt_75 "Single cell vlotage of power battery75";
CM_ SG_ 980 BMS_SingleCellVolt_76 "Single cell vlotage of power battery76";
CM_ SG_ 980 BMS_SingleCellVolt_77 "Single cell vlotage of power battery77";
CM_ SG_ 980 BMS_SingleCellVolt_78 "Single cell vlotage of power battery78";
CM_ SG_ 980 BMS_SingleCellVolt_79 "Single cell vlotage of power battery79";
CM_ SG_ 980 BMS_SingleCellVolt_80 "Single cell vlotage of power battery80";
CM_ SG_ 980 BMS_SingleCellVolt_81 "Single cell vlotage of power battery81";
CM_ SG_ 980 BMS_SingleCellVolt_82 "Single cell vlotage of power battery82";
CM_ SG_ 980 BMS_SingleCellVolt_83 "Single cell vlotage of power battery83";
CM_ SG_ 980 BMS_SingleCellVolt_84 "Single cell vlotage of power battery84";
CM_ SG_ 980 BMS_SingleCellVolt_85 "Single cell vlotage of power battery85";
CM_ SG_ 980 BMS_SingleCellVolt_86 "Single cell vlotage of power battery86";
CM_ SG_ 980 BMS_SingleCellVolt_87 "Single cell vlotage of power battery87";
CM_ SG_ 980 BMS_SingleCellVolt_88 "Single cell vlotage of power battery88";
CM_ SG_ 980 BMS_SingleCellVolt_89 "Single cell vlotage of power battery89";
CM_ SG_ 980 BMS_SingleCellVolt_90 "Single cell vlotage of power battery90";
CM_ SG_ 980 BMS_SingleCellVolt_91 "Single cell vlotage of power battery91";
CM_ SG_ 980 BMS_SingleCellVolt_92 "Single cell vlotage of power battery92";
CM_ SG_ 980 BMS_SingleCellVolt_93 "Single cell vlotage of power battery93";
CM_ SG_ 980 BMS_SingleCellVolt_94 "Single cell vlotage of power battery94";
CM_ SG_ 980 BMS_SingleCellVolt_95 "Single cell vlotage of power battery95";
CM_ SG_ 980 BMS_SingleCellVolt_96 "Single cell vlotage of power battery96";
CM_ SG_ 981 BMS_SingleCellVolt_97 "Single cell vlotage of power battery97";
CM_ SG_ 981 BMS_SingleCellVolt_98 "Single cell vlotage of power battery98";
CM_ SG_ 981 BMS_SingleCellVolt_99 "Single cell vlotage of power battery99";
CM_ SG_ 981 BMS_SingleCellVolt_100 "Single cell vlotage of power battery100";
CM_ SG_ 981 BMS_SingleCellVolt_101 "Single cell vlotage of power battery101";
CM_ SG_ 981 BMS_SingleCellVolt_102 "Single cell vlotage of power battery102";
CM_ SG_ 981 BMS_SingleCellVolt_103 "Single cell vlotage of power battery103";
CM_ SG_ 981 BMS_SingleCellVolt_104 "Single cell vlotage of power battery104";
CM_ SG_ 981 BMS_SingleCellVolt_105 "Single cell vlotage of power battery105";
CM_ SG_ 981 BMS_SingleCellVolt_106 "Single cell vlotage of power battery106";
CM_ SG_ 981 BMS_SingleCellVolt_107 "Single cell vlotage of power battery107";
CM_ SG_ 981 BMS_SingleCellVolt_108 "Single cell vlotage of power battery108";
CM_ SG_ 981 BMS_SingleCellVolt_109 "Single cell vlotage of power battery109";
CM_ SG_ 981 BMS_SingleCellVolt_110 "Single cell vlotage of power battery110";
CM_ SG_ 981 BMS_SingleCellVolt_111 "Single cell vlotage of power battery111";
CM_ SG_ 981 BMS_SingleCellVolt_112 "Single cell vlotage of power battery112";
CM_ SG_ 981 BMS_BattModuleTe_91 "module temperature of power battery_9";
CM_ SG_ 981 BMS_BattModuleTe_92 "module temperature of power battery_9";
CM_ SG_ 981 BMS_DTCNumber "BMS DTC Number";
CM_ SG_ 981 BMS_SWVersion_PHEV "BMS software version";
CM_ SG_ 981 BMS_NumberCellVoltMin_RM "Min Cell voltage position number";
CM_ SG_ 981 BMS_ModuleMaxTemp_RM "maximun module temperature";
CM_ SG_ 981 BMS_BattModuleTe_13 "module temperature of power battery_1";
CM_ SG_ 981 BMS_BattModuleTe_23 "module temperature of power battery_2";
CM_ SG_ 981 BMS_BattModuleTe_33 "module temperature of power battery_3";
CM_ SG_ 981 BMS_BattModuleTe_43 "module temperature of power battery_4";
CM_ SG_ 981 BMS_BattModuleTe_53 "module temperature of power battery_5";
CM_ SG_ 981 BMS_BattModuleTe_63 "module temperature of power battery_6";
CM_ SG_ 1008 BMS_CellMaxVolt_RM "maximun cell voltage";
CM_ SG_ 1008 BMS_CellVoltMin_RM "minimun cell voltage";
CM_ SG_ 1008 BMS_NumCellMaxTemp_RM "Max temperature position number of sensor";
CM_ SG_ 1008 BMS_NumCellMinTemp_RM "Min temperature position number of sensor";
CM_ SG_ 1008 BMS_ModuleMinTemp_RM "minimun module temperature";
CM_ SG_ 1008 BMS_NumberCellVoltMax_RM "Max Cell voltage position number";
CM_ SG_ 1008 BMS_SocJumpWarn_RM "BMS_SocJumpWarn Rank";
CM_ SG_ 1008 BMS_PackOverChrgWarn_RM "BMS_Pack Over Charge warning Rank";
CM_ SG_ 1008 BMS_IsolationRValue_RM "Isolation resistance value";
CM_ SG_ 1008 BMS_PackCurr_RM "Pack Current";
CM_ SG_ 1008 BMS_SocOverWarn_RM "BMS_Soc over warning Rank";
CM_ SG_ 1008 BMS_BattOverTempRank_RM "battery temperature is too higher";
CM_ SG_ 1008 BMS_BattOverVoltRank_RM "battery pack over voltage Rank";
CM_ SG_ 1008 BMS_BattSOCLowRank_RM "SOC low Rank";
CM_ SG_ 1008 BMS_VCUIsolateErr_RM "BMS_VCU Isolate  Error";
CM_ SG_ 1008 BMS_BattUnderVoltRank_RM "battery pack under voltage Rank";
CM_ SG_ 1008 BMS_CellDeltaVoltRank_RM "cell delta voltage Rank";
CM_ SG_ 1008 BMS_CellOverVoltRank_RM "cell over voltage Rank";
CM_ SG_ 1008 BMS_CellUnderVoltRank_RM "cell under voltage Rank";
CM_ SG_ 1008 BMS_DeltaTempRank_RM "delta temperature Rank";
CM_ SG_ 1008 BMS_PackMismatchWarn_RM "BMS_Pack Mismatchwarning Rank";
CM_ SG_ 1008 BMS_PackVolt_RM "Pack Voltage";
CM_ SG_ 1008 BMS_SysNumberCellVoltMax_RM "Max Cell voltage position system number";
CM_ SG_ 1008 BMS_SysNumberCellVoltMin_RM "Min Cell voltage position system number";
CM_ SG_ 1008 BMS_SysNumCellMaxTemp_RM "Min temperature position system number of sensor";
CM_ SG_ 1008 BMS_SysNumCellMinTemp_RM "Max temperature position system number of sensor";
CM_ SG_ 1008 BMS_BattSysNum_RM "Power battery system number";
CM_ SG_ 483 BMS_BattKeepTempResp_PHEV "Setting battery keep temperature Request";
CM_ SG_ 147 TMCU_ActPosRotSpd "Actual Positive rotation speed TM(Traction Motor)";
CM_ SG_ 193 CheckSum_DHT1 "Use the checksum strategy from document â€œEnd-to-End Communication Protection Specificationâ€";
CM_ SG_ 193 TCU_ClutchHotWarning "Warning for clutch hot";
CM_ SG_ 193 TCU_ErrCategory "Shift system error CategoryIP receive";
CM_ SG_ 193 RollingCounter_DHT1 "Rolling Counter";
CM_ SG_ 282 HCU_GearSts "the actual gear selector lever position";
CM_ SG_ 265 IFCTrqOvlCmdProtnValue "Lane Keeping Assist Torque overlay Command Protection Value";
CM_ SG_ 265 IFCTrqOvlCmdReqValue "Lane Keeping Assist Torque overlay Command Request ValuePositive means steers left, negative means steers right";
CM_ SG_ 350 CR_FCTA_Resp "Indicate FCTAï¼ˆFront Cross Traffic AlertÂ ï¼‰ Switch status";
CM_ SG_ 350 CR_FCTB_Resp "Indicate FCTBï¼ˆFront Cross Traffic BrakeÂ ï¼‰ Switch status";
CM_ SG_ 350 CR_BliSts "indicate Corner Radar blindness Status";
CM_ SG_ 350 FCTA_Warn "indicate FCTA Warning Level";
CM_ SG_ 350 FCTBTrig "indicate Corner Radar brake Status for ESP";
CM_ SG_ 350 FCTA_B_FuncSts "Indicate FCTA_B fuction system working status";
CM_ SG_ 350 FCTA_B_TTC "FCTAFCTB TTC";
CM_ SG_ 692 AEB_LePedDetn "AEB left crossing Pedestrian detectionSC_CANFD To:AR_HUD";
CM_ SG_ 692 AEB_LePedDy "Lateral distance of the AEB left crossing PedestrianSC_CANFD To:AR_HUD";
CM_ SG_ 692 AEB_LePedTyp "Types of the AEB left crossing PedestrianSC_CANFD To:AR_HUD";
CM_ SG_ 692 AEB_LePed_collisionprob "probability of the AEB left crossing PedestrianSC_CANFD To:AR_HUD";
CM_ SG_ 692 AEB_RiPedDetn "AEB right crossing Pedestrian detectionSC_CANFD To:AR_HUD";
CM_ SG_ 692 AEB_RiPedDy "Lateral distance of the AEB right crossing PedestrianSC_CANFD To:AR_HUD";
CM_ SG_ 692 AEB_RiPedTyp "Types of the AEB right crossing PedestrianSC_CANFD To:AR_HUD";
CM_ SG_ 692 AEB_RiPed_collisionprob "probability of the AEB Right crossing PedestrianSC_CANFD To:AR_HUD";
CM_ SG_ 692 AEB_LeCyclistDy "Lateral distance of the AEB left crossing CyclistSC_CANFD To:AR_HUD";
CM_ SG_ 692 AEB_LeCyclist_collisionprob "probability of the AEB left crossing CyclistSC_CANFD To:AR_HUD";
CM_ SG_ 692 AEB_RiCyclistDy "Lateral distance of the AEB right crossing CyclistSC_CANFD To:AR_HUD";
CM_ SG_ 692 AEB_RiCyclist_collisionprob "probability of the AEB  right crossing CyclistSC_CANFD To:AR_HUD";
CM_ SG_ 692 JAPedObjExist "The possibility of Pedestrian objecttive existenceSC_CANFD:To VIMS";
CM_ SG_ 692 AEBJAObjID "AEBJA objecttive IDSC_CANFD:To VIMS";
CM_ SG_ 692 AEBJAObjExist "The possibility of AEBJA objecttive existenceSC_CANFD:To VIMS";
CM_ SG_ 692 JAPedObjID "Pedestrian objective IDSC_CANFD:To VIMS";
CM_ SG_ 692 AEBJAObjVideoCfmd "AEBJA objective and Video Camera FusionSC_CANFD:To VIMS";
CM_ SG_ 692 AEBJAObjVx "Longitudinal relative speed of the AEBJA objecttive with the ego vehicleSC_CANFD:To VIMS";
CM_ SG_ 692 AEBJAObjDx "Longitudinal distance of the AEBJA objecttive with the ego vehicleSC_CANFD:To VIMS";
CM_ SG_ 692 JAPedObjVideoCfmd "Pedestrian objective and Video Camera FusionSC_CANFD:To VIMS";
CM_ SG_ 692 AEBJAObjState "Indicate AEBJA objective StatusSC_CANFD:To VIMS";
CM_ SG_ 692 AEBJAObjCntAlive "Indicate the duration of the AEBJA objecttiveSC_CANFD:To VIMS";
CM_ SG_ 692 AEBJAObjDy "Lateral distance of the AEBJA objecttive with the ego vehicleSC_CANFD:To VIMS";
CM_ SG_ 692 JAPedObjState "Pedestrian objective StatusSC_CANFD:To VIMS";
CM_ SG_ 692 AEBJAObjObstcl "AEBJA Target are the possibility of obstaclesSC_CANFD:To VIMS";
CM_ SG_ 692 AEBJAObjVy "Lateral relative speed of the AEBJA target vehicle with the ego vehicleSC_CANFD:To VIMS";
CM_ SG_ 692 AEBJAObjAx "Longitudinal relative speed of the AEBJA target with the ego vehicleSC_CANFD:To VIMS";
CM_ SG_ 692 AEBJAObjAy "Lateral ACCeleration of the AEBJA target with the ego vehicleSC_CANFD:To VIMS";
CM_ SG_ 692 JAPedObjObstcl "Target Pedestrian are the possibility of obstaclesSC_CANFD:To VIMS";
CM_ SG_ 692 JAPedObjDy "Lateral distance of the target Pedestrian with the ego vehicleSC_CANFD:To VIMS";
CM_ SG_ 692 JAPedObjDx "Longitudinal distance of the target Pedestrian with the ego vehicleSC_CANFD:To VIMS";
CM_ SG_ 692 FCWAEB_JATTC "FCWAEB JA turn across TTCSC_CANFD:To HUT";
CM_ SG_ 692 JAPedObjVx "Longitudinal relative speed of the target Pedestrian with the ego vehicleSC_CANFD:To VIMS";
CM_ SG_ 692 JAPedObjVy "Lateral relative speed of the Pedestrian objective with the ego vehicleSC_CANFD:To VIMS";
CM_ SG_ 692 JAPedObjAy "Lateral ACCeleration of Pedestrian objective with ego vehicleSC_CANFD:To VIMS";
CM_ SG_ 692 JAPedObjCntAlive "Indicate the duration of the Pedestrian objective's existenceSC_CANFD:To VIMS";
CM_ SG_ 692 FCWAEB_longTTC "FCWAEB longitude TTC(Time to collision)SC_CANFD:To HUT";
CM_ SG_ 692 FCWAEB_crossingTTC "FCWAEB crossing TTCSC_CANFD:To HUT";
CM_ SG_ 692 JAPedObjAx "Longitudinal ACCeleration of Pedestrian objective with ego vehicleSC_CANFD:To VIMS";
CM_ SG_ 692 AEB_LePedDx "Longitudinal distance of the AEB left crossing PedestrianSC-CANFD To:AR_HUD";
CM_ SG_ 692 AEB_RiPedDx "Longitudinal distance of the AEB right crossing PedestrianSC-CANFD To:AR_HUD";
CM_ SG_ 692 AEB_LeCyclistDetn "AEB left crossing Cyclist detectionSC-CANFD To:AR_HUD";
CM_ SG_ 692 AEB_LeCyclistDx "Longitudinal distance of the AEB left crossing CyclistSC-CANFD To:AR_HUD";
CM_ SG_ 692 AEB_LeCyclistTyp "Types of the AEB left crossing CyclistSC-CANFD To:AR_HUD";
CM_ SG_ 692 AEB_RiCyclistDetn "AEB right crossing Cyclist detectionSC-CANFD To:AR_HUD";
CM_ SG_ 692 AEB_RiCyclistDx "Longitudinal distance of the AEB right crossing CyclistSC-CANFD To:AR_HUD";
CM_ SG_ 692 AEB_RiCyclistTyp "Types of the AEB right crossing CyclistSC-CANFD To:AR_HUD";
CM_ SG_ 778 RCTA_B_TTC "RCTARCTB TTCSC_CANFD To: HUT";
CM_ SG_ 778 BSD_LCA_Left_TTC "Left  BSD_LCA  TTCSC_CANFD To: HUT";
CM_ SG_ 778 BSD_LCA_Right_TTC "Right  BSD_LCA  TTCSC_CANFD To: HUT";
CM_ SG_ 778 RCW_TTC "RCW TTC(Rear collision warning)SC_CANFD To: HUT";
CM_ SG_ 778 RSDS_LeTgt_01 "left first targrt from RSDSSC_CANFD To: HUT";
CM_ SG_ 778 RSDS_LeTgt_01_dx "left first targrt of dx  from RSDSSC_CANFD To: HUT";
CM_ SG_ 778 RSDS_LeTgt_01_dy "left first targrt of dy  from RSDSSC_CANFD To: HUT";
CM_ SG_ 778 RSDS_LeTgt_02 "left second targrt from RSDSSC_CANFD To: HUT";
CM_ SG_ 778 RSDS_LeTgt_02_dx "left second targrt of dx  from RSDSSC_CANFD To: HUT";
CM_ SG_ 778 RSDS_LeTgt_02_dy "left second targrt of dy  from RSDSSC_CANFD To: HUT";
CM_ SG_ 778 RSDS_RiTgt_01 "right first targrt from RSDSSC_CANFD To: HUT";
CM_ SG_ 778 RSDS_RiTgt_01_dx "right first targrt of dx  from RSDSSC_CANFD To: HUT";
CM_ SG_ 778 RSDS_RiTgt_01_dy "right first targrt of dy  from RSDSSC_CANFD To: HUT";
CM_ SG_ 778 RSDS_RiTgt_02 "right second targrt from RSDSSC_CANFD To: HUT";
CM_ SG_ 778 RSDS_RiTgt_02_dx "right second targrt of dx  from RSDSSC_CANFD To: HUT";
CM_ SG_ 778 RSDS_RiTgt_02_dy "right second targrt of dy  from RSDSSC_CANFD To: HUT";
CM_ SG_ 778 RSDS_MidTgt_01 "left first targrt from RSDSSC_CANFD To: HUT";
CM_ SG_ 778 RSDS_MidTgt_01_dx "middle first targrt of dx  from RSDSSC_CANFD To: HUT";
CM_ SG_ 778 RSDS_MidTgt_01_dy "middle first targrt of dy  from RSDSSC_CANFD To: HUT";
CM_ SG_ 778 RSDS_MidTgt_02 "middle second targrt from RSDSSC_CANFD To: HUT";
CM_ SG_ 778 RSDS_MidTgt_02_dx "middle second targrt of dx  from RSDSSC_CANFD To: HUT";
CM_ SG_ 778 RSDS_MidTgt_02_dy "middle second targrt of dy  from RSDSSC_CANFD To: HUT";
CM_ SG_ 415 IFC_Line01_Dy "Dy at position of DxStart  (not always x=0, because of high values for 2nd segment)SC_CANFD To:HUT,AR_HUD";
CM_ SG_ 415 IFC_Line01_Curv "Curvature of the Line, also called kappaSC_CANFD To:HUT,AR_HUD";
CM_ SG_ 415 IFC_Line01_CurvChange "Currvature change or alteration of the Line, also called kappaDtSC_CANFD To:HUT,AR_HUD";
CM_ SG_ 415 IFC_Line01_Type "Type of the LineSC_CANFD To:HUT,AR_HUD";
CM_ SG_ 415 IFC_Line02_Dy "Dy at position of DxStart  (not always x=0, because of high values for 2nd segment)SC_CANFD To:HUT,AR_HUD";
CM_ SG_ 415 IFC_Line02_Curv "Curvature of the Line, also called kappaSC_CANFD To:HUT,AR_HUD";
CM_ SG_ 415 IFC_Line02_CurvChange "Currvature change or alteration of the Line, also called kappaDtSC_CANFD To:HUT,AR_HUD";
CM_ SG_ 415 IFC_Line02_Type "Type of the LineSC_CANFD To:HUT,AR_HUD";
CM_ SG_ 415 IFC_Line03_Dy "Dy at position of DxStart  (not always x=0, because of high values for 2nd segment)SC_CANFD To:HUT,AR_HUD";
CM_ SG_ 415 IFC_Line03_Curv "Curvature of the Line, also called kappaSC_CANFD To:HUT,AR_HUD";
CM_ SG_ 415 IFC_Line03_CurvChange "Currvature change or alteration of the Line, also called kappaDtSC_CANFD To:HUT,AR_HUD";
CM_ SG_ 415 IFC_Line03_Type "Type of the LineSC_CANFD To:HUT,AR_HUD";
CM_ SG_ 415 IFC_Line04_Dy "Dy at position of DxStart  (not always x=0, because of high values for 2nd segment)SC_CANFD To:HUT,AR_HUD";
CM_ SG_ 415 IFC_Line04_Curv "Curvature of the Line, also called kappaSC_CANFD To:HUT,AR_HUD";
CM_ SG_ 415 IFC_Line04_CurvChange "Currvature change or alteration of the Line, also called kappaDtSC_CANFD To:HUT,AR_HUD";
CM_ SG_ 415 IFC_Line04_Type "Type of the LineSC_CANFD To:HUT,AR_HUD";
CM_ SG_ 415 IFC_Roadedge01_Dy "Dy at position of DxStart  (not always x=0, because of high values for 2nd segment)SC_CANFD To:HUT,AR_HUD";
CM_ SG_ 415 IFC_Roadedge01_Curv "Curvature of the Line, also called kappaSC_CANFD To:HUT,AR_HUD";
CM_ SG_ 415 IFC_Roadedge01_CurvChange "Currvature change or alteration of the Line, also called kappaDtSC_CANFD To:HUT,AR_HUD";
CM_ SG_ 415 IFC_Roadedge01_Type "Type of the LineSC_CANFD To:HUT,AR_HUD";
CM_ SG_ 415 IFC_Roadedge02_Dy "Dy at position of DxStart  (not always x=0, because of high values for 2nd segment)SC_CANFD To:HUT,AR_HUD";
CM_ SG_ 415 IFC_Roadedge02_Curv "Curvature of the Line, also called kappaSC_CANFD To:HUT,AR_HUD";
CM_ SG_ 415 IFC_Roadedge02_CurvChange "Currvature change or alteration of the Line, also called kappaDtSC_CANFD To:HUT,AR_HUD";
CM_ SG_ 415 IFC_Roadedge02_Type "Type of the LineSC_CANFD To:HUT,AR_HUD";
CM_ SG_ 546 IFC_Line01_DxStart "Longitudinal start point of the line, also called dxStartSC_CANFD To:HUT,AR_HUD";
CM_ SG_ 546 IFC_Line01_DxEnd "Longitudinal range of the line, also called dxEndSC_CANFD To:HUT,AR_HUD";
CM_ SG_ 546 IFC_Line01_HeadingAngle "Heading angle, difference in yaw angle between vehicle heading and LineSC_CANFD To:HUT,AR_HUD";
CM_ SG_ 546 IFC_Line02_HeadingAngle "Heading angle, difference in yaw angle between vehicle heading and LineSC_CANFD To:HUT,AR_HUD";
CM_ SG_ 546 IFC_Line02_DxStart "Longitudinal start point of the line, also called dxStartSC_CANFD To:HUT,AR_HUD";
CM_ SG_ 546 IFC_Line02_DxEnd "Longitudinal range of the line, also called dxEndSC_CANFD To:HUT,AR_HUD";
CM_ SG_ 546 IFC_Line03_DxStart "Longitudinal start point of the line, also called dxStartSC_CANFD To:HUT,AR_HUD";
CM_ SG_ 546 IFC_Line03_DxEnd "Longitudinal range of the line, also called dxEndSC_CANFD To:HUT,AR_HUD";
CM_ SG_ 546 IFC_Line03_HeadingAngle "Heading angle, difference in yaw angle between vehicle heading and LineSC_CANFD To:HUT,AR_HUD";
CM_ SG_ 546 IFC_Line04_DxStart "Longitudinal start point of the line, also called dxStartSC_CANFD To:HUT,AR_HUD";
CM_ SG_ 546 IFC_Line04_HeadingAngle "Heading angle, difference in yaw angle between vehicle heading and LineSC_CANFD To:HUT,AR_HUD";
CM_ SG_ 546 IFC_Line04_DxEnd "Longitudinal range of the line, also called dxEndSC_CANFD To:HUT,AR_HUD";
CM_ SG_ 546 IFC_Roadedge01_DxStart "Longitudinal start point of the line, also called dxStartSC_CANFD To:HUT,AR_HUD";
CM_ SG_ 546 IFC_Roadedge01_DxEnd "Longitudinal range of the line, also called dxEndSC_CANFD To:HUT,AR_HUD";
CM_ SG_ 546 IFC_Roadedge01_HeadingAngle "Heading angle, difference in yaw angle between vehicle heading and LineSC_CANFD To:HUT,AR_HUD";
CM_ SG_ 546 IFC_Roadedge02_DxStart "Longitudinal start point of the line, also called dxStartSC_CANFD To:HUT,AR_HUD";
CM_ SG_ 546 IFC_Roadedge02_DxEnd "Longitudinal range of the line, also called dxEndSC_CANFD To:HUT,AR_HUD";
CM_ SG_ 546 IFC_Roadedge02_HeadingAngle "Heading angle, difference in yaw angle between vehicle heading and LineSC_CANFD To:HUT,AR_HUD";
CM_ SG_ 705 ChairMemPosnSetSwtFB "FeedbackÂ ofÂ Â ChairÂ MemoryÂ PositionÂ SetÂ switchSC-CANFD To:HUT";
CM_ SG_ 705 DrvSeatMassgModeSts "Driver Seat Massage Mode Status";
CM_ SG_ 705 DrvSeatMassgLvlSetSts "Driver Seat Massage Level Set Status";
CM_ SG_ 705 DrvSeatLumSMAdjSts "Driver Seat Lumbar Support Module Adjust Status";
CM_ SG_ 491 DrvSeatMassgLvlSet "Driver Seat massage level setBD1-CAN:To DSC";
CM_ SG_ 491 DrvSeatMassgModSet "Driver Seat massage mode setBD1-CAN:To DSC";
CM_ SG_ 491 DrvBehvTestSetUp "Driver Behaviora Test function disable or enable";
CM_ SG_ 491 GazeAreaIntracSetUp "Gaze Area HMI interaction function disable or enable";
CM_ SG_ 694 DrvSeatSupportPosnSwt "Driver Seat support position switchBD1-CAN:To DSC";
CM_ SG_ 963 GMCU_MotorSerNumber_RM "Actual serial number of E-motor for  remote monitor";
CM_ SG_ 963 GMCU_InvActTemp_RM "Actual Virtual Junction Temperature state of hottest Inverter Power-Semiconductor";
CM_ SG_ 963 GMCU_ActSpd_RM "Actual mechanical speed of EM(Electric Motor)";
CM_ SG_ 963 GMCU_ActTrq_RM "Actual torque at EM(Electric Motor)   shaft";
CM_ SG_ 967 GMCU_ActHvDcCurr_RM "Actual HV DC(High Voltage Direct Current link) Current";
CM_ SG_ 967 GMCU_ActHvDcVolt_RM "Actual HV DC(High Voltage Direct Current) voltage";
CM_ SG_ 967 GMCU_ActTemp_RM "Actual Temperature of hottest sensor element in EM(Electric Motor)  Winding";
CM_ SG_ 967 GMCU_Tempwarning_RM "Actual Temperature warrning of hottest sensor element in EM(Electric Motor)  Winding";
CM_ SG_ 967 GMCU_InvTempwarning_RM "Actual Temperature warrning of hottest sensor element in EM Inverter(Electric Motor)  Winding";
CM_ SG_ 967 GMCU_OperMode_RM "Actual operation mode of Actuation Motor";
CM_ SG_ 763 MbrMonrEnaSts "member monitoring enable statusSC_CANFD:To HUT";
CM_ SG_ 731 ALCMSwtSts "ALCM Switch status";
BA_DEF_ BO_  "DiagRequest" ENUM  "No","Yes";
BA_DEF_ BO_  "DiagResponse" ENUM  "No","Yes";
BA_DEF_ BO_  "DiagState" ENUM  "No","Yes";
BA_DEF_ BO_  "GenMsgCycleTime" INT 0 65535;
BA_DEF_ BO_  "GenMsgCycleTimeFast" INT 0 65535;
BA_DEF_ BO_  "GenMsgILSupport" ENUM  "No","Yes";
BA_DEF_ BO_  "GenMsgNrOfRepetition" INT 0 65535;
BA_DEF_ BO_  "GenMsgSendType" ENUM  "Cyclic","CyclicAndSpontanX","Event";
BA_DEF_ BO_  "NmAsrMessage" ENUM  "No","Yes";
BA_DEF_ BO_  "SCP_AuthInfoTxLength" INT 0 512;
BA_DEF_ BO_  "SCP_DataId" INT 0 65535;
BA_DEF_ BO_  "SCP_FreshnessValueLength" INT 0 512;
BA_DEF_ BO_  "SCP_FreshnessValueTxLength" INT 0 512;
BA_DEF_ BO_  "SC_Message" ENUM  "NO","YES";
BA_DEF_ BO_  "VFrameFormat" ENUM  "StandardCAN","ExtendedCAN","reserved","reserved","reserved","reserved","reserved","reserved","reserved","reserved","reserved","reserved","reserved","reserved","StandardCAN_FD","ExtendedCAN_FD";
BA_DEF_ SG_  "GenSigCycleTime" INT 0 65535;
BA_DEF_ SG_  "GenSigSendType" ENUM  "Cyclic","OnWrite","OnWriteWithRepetition","OnChange","OnChangeWithRepetition","NotUsed","NotUsed","NoSigSendType";
BA_DEF_ SG_  "GenSigStartValue" FLOAT 0 100000000000;
BA_DEF_ SG_  "TransparentInitValue" STRING ;
BA_DEF_ SG_  "SystemSignalLongSymbol" STRING ;
BA_DEF_DEF_  "DiagRequest" "No";
BA_DEF_DEF_  "DiagResponse" "No";
BA_DEF_DEF_  "DiagState" "No";
BA_DEF_DEF_  "GenMsgCycleTime" 0;
BA_DEF_DEF_  "GenMsgCycleTimeFast" 0;
BA_DEF_DEF_  "GenMsgILSupport" "No";
BA_DEF_DEF_  "GenMsgNrOfRepetition" 0;
BA_DEF_DEF_  "GenMsgSendType" "Cyclic";
BA_DEF_DEF_  "NmAsrMessage" "No";
BA_DEF_DEF_  "SCP_AuthInfoTxLength" 0;
BA_DEF_DEF_  "SCP_DataId" 0;
BA_DEF_DEF_  "SCP_FreshnessValueLength" 0;
BA_DEF_DEF_  "SCP_FreshnessValueTxLength" 0;
BA_DEF_DEF_  "SC_Message" "NO";
BA_DEF_DEF_  "VFrameFormat" "";
BA_DEF_DEF_  "GenSigCycleTime" 0;
BA_DEF_DEF_  "GenSigSendType" "Cyclic";
BA_DEF_DEF_  "GenSigStartValue" 0;
BA_DEF_DEF_  "TransparentInitValue" "";
BA_DEF_DEF_  "SystemSignalLongSymbol" "";
BA_ "GenMsgSendType" BO_ 482 2;
BA_ "GenMsgNrOfRepetition" BO_ 482 5;
BA_ "GenMsgILSupport" BO_ 482 1;
BA_ "GenMsgCycleTimeFast" BO_ 482 20;
BA_ "VFrameFormat" BO_ 482 14;
BA_ "GenMsgILSupport" BO_ 909 1;
BA_ "GenMsgCycleTime" BO_ 909 1000;
BA_ "VFrameFormat" BO_ 909 14;
BA_ "GenMsgILSupport" BO_ 241 1;
BA_ "GenMsgCycleTime" BO_ 241 10;
BA_ "VFrameFormat" BO_ 241 14;
BA_ "GenMsgILSupport" BO_ 645 1;
BA_ "GenMsgCycleTime" BO_ 645 100;
BA_ "VFrameFormat" BO_ 645 14;
BA_ "GenMsgILSupport" BO_ 708 1;
BA_ "GenMsgCycleTime" BO_ 708 100;
BA_ "VFrameFormat" BO_ 708 14;
BA_ "GenMsgILSupport" BO_ 850 1;
BA_ "GenMsgCycleTime" BO_ 850 500;
BA_ "VFrameFormat" BO_ 850 14;
BA_ "GenMsgILSupport" BO_ 959 1;
BA_ "GenMsgCycleTime" BO_ 959 1000;
BA_ "VFrameFormat" BO_ 959 14;
BA_ "GenMsgILSupport" BO_ 976 1;
BA_ "GenMsgCycleTime" BO_ 976 1000;
BA_ "VFrameFormat" BO_ 976 14;
BA_ "GenMsgILSupport" BO_ 1009 1;
BA_ "GenMsgCycleTime" BO_ 1009 1000;
BA_ "VFrameFormat" BO_ 1009 14;
BA_ "GenMsgILSupport" BO_ 1010 1;
BA_ "GenMsgCycleTime" BO_ 1010 1000;
BA_ "VFrameFormat" BO_ 1010 14;
BA_ "GenMsgILSupport" BO_ 1011 1;
BA_ "GenMsgCycleTime" BO_ 1011 1000;
BA_ "VFrameFormat" BO_ 1011 14;
BA_ "GenMsgILSupport" BO_ 790 1;
BA_ "GenMsgCycleTime" BO_ 790 200;
BA_ "VFrameFormat" BO_ 790 14;
BA_ "GenMsgILSupport" BO_ 791 1;
BA_ "GenMsgCycleTime" BO_ 791 200;
BA_ "VFrameFormat" BO_ 791 14;
BA_ "GenMsgILSupport" BO_ 96 1;
BA_ "GenMsgCycleTime" BO_ 96 10;
BA_ "VFrameFormat" BO_ 96 14;
BA_ "GenMsgILSupport" BO_ 330 1;
BA_ "GenMsgCycleTime" BO_ 330 20;
BA_ "VFrameFormat" BO_ 330 14;
BA_ "GenMsgILSupport" BO_ 584 1;
BA_ "GenMsgCycleTime" BO_ 584 50;
BA_ "VFrameFormat" BO_ 584 14;
BA_ "GenMsgILSupport" BO_ 448 1;
BA_ "GenMsgCycleTime" BO_ 448 50;
BA_ "VFrameFormat" BO_ 448 14;
BA_ "GenMsgILSupport" BO_ 762 1;
BA_ "GenMsgCycleTime" BO_ 762 100;
BA_ "VFrameFormat" BO_ 762 14;
BA_ "GenMsgILSupport" BO_ 513 1;
BA_ "GenMsgCycleTime" BO_ 513 50;
BA_ "VFrameFormat" BO_ 513 14;
BA_ "GenMsgILSupport" BO_ 288 1;
BA_ "GenMsgCycleTime" BO_ 288 20;
BA_ "VFrameFormat" BO_ 288 14;
BA_ "GenMsgILSupport" BO_ 200 1;
BA_ "GenMsgCycleTime" BO_ 200 10;
BA_ "VFrameFormat" BO_ 200 14;
BA_ "GenMsgILSupport" BO_ 216 1;
BA_ "GenMsgCycleTime" BO_ 216 10;
BA_ "VFrameFormat" BO_ 216 14;
BA_ "GenMsgILSupport" BO_ 957 1;
BA_ "GenMsgCycleTime" BO_ 957 1000;
BA_ "VFrameFormat" BO_ 957 14;
BA_ "GenMsgILSupport" BO_ 969 1;
BA_ "GenMsgCycleTime" BO_ 969 1000;
BA_ "VFrameFormat" BO_ 969 14;
BA_ "GenMsgILSupport" BO_ 948 1;
BA_ "GenMsgCycleTime" BO_ 948 1000;
BA_ "VFrameFormat" BO_ 948 14;
BA_ "GenMsgILSupport" BO_ 977 1;
BA_ "GenMsgCycleTime" BO_ 977 1000;
BA_ "VFrameFormat" BO_ 977 14;
BA_ "GenMsgILSupport" BO_ 978 1;
BA_ "GenMsgCycleTime" BO_ 978 1000;
BA_ "VFrameFormat" BO_ 978 14;
BA_ "GenMsgILSupport" BO_ 979 1;
BA_ "GenMsgCycleTime" BO_ 979 1000;
BA_ "VFrameFormat" BO_ 979 14;
BA_ "GenMsgILSupport" BO_ 980 1;
BA_ "GenMsgCycleTime" BO_ 980 1000;
BA_ "VFrameFormat" BO_ 980 14;
BA_ "GenMsgILSupport" BO_ 981 1;
BA_ "GenMsgCycleTime" BO_ 981 1000;
BA_ "VFrameFormat" BO_ 981 14;
BA_ "GenMsgILSupport" BO_ 1008 1;
BA_ "GenMsgCycleTime" BO_ 1008 1000;
BA_ "VFrameFormat" BO_ 1008 14;
BA_ "GenMsgSendType" BO_ 483 2;
BA_ "GenMsgNrOfRepetition" BO_ 483 5;
BA_ "GenMsgILSupport" BO_ 483 1;
BA_ "GenMsgCycleTimeFast" BO_ 483 20;
BA_ "VFrameFormat" BO_ 483 14;
BA_ "GenMsgILSupport" BO_ 147 1;
BA_ "GenMsgCycleTime" BO_ 147 10;
BA_ "VFrameFormat" BO_ 147 14;
BA_ "GenMsgILSupport" BO_ 193 1;
BA_ "GenMsgCycleTime" BO_ 193 10;
BA_ "VFrameFormat" BO_ 193 14;
BA_ "GenMsgILSupport" BO_ 282 1;
BA_ "GenMsgCycleTime" BO_ 282 20;
BA_ "VFrameFormat" BO_ 282 14;
BA_ "GenMsgILSupport" BO_ 265 1;
BA_ "GenMsgCycleTime" BO_ 265 20;
BA_ "VFrameFormat" BO_ 265 14;
BA_ "GenMsgILSupport" BO_ 350 1;
BA_ "GenMsgCycleTime" BO_ 350 20;
BA_ "VFrameFormat" BO_ 350 14;
BA_ "GenMsgILSupport" BO_ 692 1;
BA_ "GenMsgCycleTime" BO_ 692 100;
BA_ "VFrameFormat" BO_ 692 14;
BA_ "GenMsgILSupport" BO_ 778 1;
BA_ "GenMsgCycleTime" BO_ 778 200;
BA_ "VFrameFormat" BO_ 778 14;
BA_ "GenMsgILSupport" BO_ 415 1;
BA_ "GenMsgCycleTime" BO_ 415 50;
BA_ "VFrameFormat" BO_ 415 14;
BA_ "GenMsgILSupport" BO_ 546 1;
BA_ "GenMsgCycleTime" BO_ 546 50;
BA_ "VFrameFormat" BO_ 546 14;
BA_ "GenMsgILSupport" BO_ 705 1;
BA_ "GenMsgCycleTime" BO_ 705 100;
BA_ "VFrameFormat" BO_ 705 14;
BA_ "GenMsgSendType" BO_ 491 2;
BA_ "GenMsgNrOfRepetition" BO_ 491 5;
BA_ "GenMsgILSupport" BO_ 491 1;
BA_ "GenMsgCycleTimeFast" BO_ 491 20;
BA_ "VFrameFormat" BO_ 491 14;
BA_ "GenMsgILSupport" BO_ 694 1;
BA_ "GenMsgCycleTime" BO_ 694 100;
BA_ "VFrameFormat" BO_ 694 14;
BA_ "GenMsgILSupport" BO_ 963 1;
BA_ "GenMsgCycleTime" BO_ 963 1000;
BA_ "VFrameFormat" BO_ 963 14;
BA_ "GenMsgILSupport" BO_ 967 1;
BA_ "GenMsgCycleTime" BO_ 967 1000;
BA_ "VFrameFormat" BO_ 967 14;
BA_ "GenMsgILSupport" BO_ 763 1;
BA_ "GenMsgCycleTime" BO_ 763 100;
BA_ "VFrameFormat" BO_ 763 14;
BA_ "GenMsgSendType" BO_ 731 2;
BA_ "GenMsgNrOfRepetition" BO_ 731 5;
BA_ "GenMsgILSupport" BO_ 731 1;
BA_ "GenMsgCycleTimeFast" BO_ 731 20;
BA_ "VFrameFormat" BO_ 731 14;
BA_ "GenMsgSendType" BO_ 1888 2;
BA_ "DiagState" BO_ 1888 1;
BA_ "VFrameFormat" BO_ 1888 14;
BA_ "GenMsgSendType" BO_ 1889 2;
BA_ "DiagRequest" BO_ 1889 1;
BA_ "VFrameFormat" BO_ 1889 14;
BA_ "GenMsgSendType" BO_ 1918 2;
BA_ "DiagRequest" BO_ 1918 1;
BA_ "VFrameFormat" BO_ 1918 14;
BA_ "GenMsgSendType" BO_ 1907 2;
BA_ "DiagRequest" BO_ 1907 1;
BA_ "VFrameFormat" BO_ 1907 14;
BA_ "GenMsgSendType" BO_ 1566 2;
BA_ "DiagRequest" BO_ 1566 1;
BA_ "VFrameFormat" BO_ 1566 14;
BA_ "GenMsgSendType" BO_ 1560 2;
BA_ "DiagRequest" BO_ 1560 1;
BA_ "VFrameFormat" BO_ 1560 14;
BA_ "GenMsgSendType" BO_ 1953 2;
BA_ "DiagResponse" BO_ 1953 1;
BA_ "VFrameFormat" BO_ 1953 14;
BA_ "GenMsgSendType" BO_ 1982 2;
BA_ "DiagResponse" BO_ 1982 1;
BA_ "VFrameFormat" BO_ 1982 14;
BA_ "GenMsgSendType" BO_ 1971 2;
BA_ "DiagResponse" BO_ 1971 1;
BA_ "VFrameFormat" BO_ 1971 14;
BA_ "GenMsgSendType" BO_ 1567 2;
BA_ "DiagResponse" BO_ 1567 1;
BA_ "VFrameFormat" BO_ 1567 14;
BA_ "GenMsgSendType" BO_ 1561 2;
BA_ "DiagResponse" BO_ 1561 1;
BA_ "VFrameFormat" BO_ 1561 14;
BA_ "VFrameFormat" BO_ 1290 0;
BA_ "NmAsrMessage" BO_ 1290 1;
BA_ "GenMsgSendType" BO_ 1290 2;
BA_ "VFrameFormat" BO_ 1289 0;
BA_ "NmAsrMessage" BO_ 1289 1;
BA_ "GenMsgSendType" BO_ 1289 2;
BA_ "VFrameFormat" BO_ 1302 0;
BA_ "NmAsrMessage" BO_ 1302 1;
BA_ "GenMsgSendType" BO_ 1302 2;
BA_ "VFrameFormat" BO_ 1303 0;
BA_ "NmAsrMessage" BO_ 1303 1;
BA_ "GenMsgSendType" BO_ 1303 2;
BA_ "VFrameFormat" BO_ 1281 0;
BA_ "NmAsrMessage" BO_ 1281 1;
BA_ "GenMsgSendType" BO_ 1281 2;
BA_ "GenMsgSendType" BO_ 1122 2;
BA_ "GenMsgILSupport" BO_ 1122 1;
BA_ "VFrameFormat" BO_ 1122 14;
BA_ "SC_Message" BO_ 1121 1;
BA_ "SCP_FreshnessValueTxLength" BO_ 1121 40;
BA_ "SCP_FreshnessValueLength" BO_ 1121 40;
BA_ "SCP_DataId" BO_ 1121 1121;
BA_ "SCP_AuthInfoTxLength" BO_ 1121 88;
BA_ "VFrameFormat" BO_ 1121 14;
BA_ "GenSigSendType" SG_ 482 HCU_PhoneChrgnModeResp 2;
BA_ "GenSigSendType" SG_ 482 HCU_PhoneChrgnReqResp 2;
BA_ "GenSigSendType" SG_ 482 HCU_HUTChrgnModeResp 2;
BA_ "GenSigSendType" SG_ 482 HCU_HUTChrgnReqResp 2;
BA_ "GenSigSendType" SG_ 482 HCU_TboxEngStrtReq 2;
BA_ "GenSigSendType" SG_ 482 HCU_TotalScore 2;
BA_ "GenSigSendType" SG_ 482 HCU_IntelBattTempMagResp 2;
BA_ "GenSigSendType" SG_ 482 HCU_RemtVehStartReq 2;
BA_ "TransparentInitValue" SG_ 482 HCU_HC8_0x1E2 "0 0 0 0 0 0 0 0 ";
BA_ "GenSigSendType" SG_ 482 HCU_HC8_0x1E2 2;
BA_ "GenSigCycleTime" SG_ 909 HCU_PowertrainSts_RM 1000;
BA_ "GenSigStartValue" SG_ 909 HCU_ChargSts_RM 3;
BA_ "GenSigCycleTime" SG_ 909 HCU_ChargSts_RM 1000;
BA_ "GenSigCycleTime" SG_ 909 HCU_PTDrvMod_RM 1000;
BA_ "GenSigCycleTime" SG_ 909 HCU_Powerflag_RM 1000;
BA_ "GenSigCycleTime" SG_ 909 HCU_AccelPedalPosn_Diag_RM 1000;
BA_ "GenSigCycleTime" SG_ 909 HCU_BrkPedalSts_RM 1000;
BA_ "GenSigCycleTime" SG_ 909 HCU_DrvPower_RM 1000;
BA_ "GenSigCycleTime" SG_ 909 HCU_BrkPower_RM 1000;
BA_ "GenSigCycleTime" SG_ 909 HCU_GearSts_RM 1000;
BA_ "GenSigCycleTime" SG_ 241 CheckSum_BMS4 10;
BA_ "GenSigCycleTime" SG_ 241 BMS_PowerDownCmplt 10;
BA_ "GenSigCycleTime" SG_ 241 BMS_BattPoweErr 10;
BA_ "GenSigCycleTime" SG_ 241 BMS_ErrCategory 10;
BA_ "GenSigCycleTime" SG_ 241 BMS_PackCurr 10;
BA_ "GenSigStartValue" SG_ 241 BMS_PackVolt 178;
BA_ "GenSigCycleTime" SG_ 241 BMS_PackVolt 10;
BA_ "GenSigCycleTime" SG_ 241 RollingCounter_BMS4 10;
BA_ "TransparentInitValue" SG_ 241 BMS4_0xF1 "0 0 0 178 0 0 0 0 ";
BA_ "GenSigCycleTime" SG_ 241 BMS4_0xF1 10;
BA_ "GenSigCycleTime" SG_ 645 BMS_BattHeatRunaway 100;
BA_ "TransparentInitValue" SG_ 645 BMS8_0x285 "0 0 0 0 0 0 0 0 ";
BA_ "GenSigCycleTime" SG_ 645 BMS8_0x285 100;
BA_ "GenSigCycleTime" SG_ 708 BMS_BattSOC 100;
BA_ "GenSigStartValue" SG_ 708 BMS_BattSOCLimResp 6;
BA_ "GenSigCycleTime" SG_ 708 BMS_BattSOCLimResp 100;
BA_ "TransparentInitValue" SG_ 708 BMS35_0x2C4 "0 0 0 0 0 6 0 0 ";
BA_ "GenSigCycleTime" SG_ 708 BMS35_0x2C4 100;
BA_ "GenSigCycleTime" SG_ 850 BMS_RemtPreHeatSts 500;
BA_ "GenSigCycleTime" SG_ 850 BMS_BattKeepTempSts 500;
BA_ "GenSigCycleTime" SG_ 850 BMS_IntelEngIdlChrgnSts 500;
BA_ "TransparentInitValue" SG_ 850 BMS19_0x352 "0 0 0 0 0 0 0 0 ";
BA_ "GenSigCycleTime" SG_ 850 BMS19_0x352 500;
BA_ "GenSigCycleTime" SG_ 959 BMS_ChrgDurationTime 1000;
BA_ "TransparentInitValue" SG_ 959 BMS22_0x3BF "0 0 0 0 0 0 0 0 ";
BA_ "GenSigCycleTime" SG_ 959 BMS22_0x3BF 1000;
BA_ "GenSigStartValue" SG_ 976 BMS_BattTempMax 65;
BA_ "GenSigCycleTime" SG_ 976 BMS_BattTempMax 1000;
BA_ "GenSigStartValue" SG_ 976 BMS_BattTempMin 65;
BA_ "GenSigCycleTime" SG_ 976 BMS_BattTempMin 1000;
BA_ "GenSigCycleTime" SG_ 1009 BMS_CellUnderVolt 1000;
BA_ "GenSigCycleTime" SG_ 1009 BMS_CellOverVolt 1000;
BA_ "GenSigCycleTime" SG_ 1009 BMS_CellDeltaVolt 1000;
BA_ "GenSigCycleTime" SG_ 1009 BMS_BattUnderVolt 1000;
BA_ "GenSigCycleTime" SG_ 1009 BMS_BattOverVolt 1000;
BA_ "GenSigCycleTime" SG_ 1009 BMS_BattUnderTemp 1000;
BA_ "GenSigCycleTime" SG_ 1009 BMS_SOC_Plaucheck 1000;
BA_ "GenSigCycleTime" SG_ 1009 BMS_DeltaTemp 1000;
BA_ "GenSigCycleTime" SG_ 1009 BMS_CANComErr 1000;
BA_ "GenSigCycleTime" SG_ 1009 BMS_SOCLowWarn 1000;
BA_ "GenSigCycleTime" SG_ 1009 BMS_BattSOCLow 1000;
BA_ "GenSigCycleTime" SG_ 1009 BMS_BattSOCTooLow 1000;
BA_ "GenSigCycleTime" SG_ 1009 BMS_BattSOCHigh 1000;
BA_ "GenSigCycleTime" SG_ 1009 BMS_ChrgnCurrLager 1000;
BA_ "GenSigCycleTime" SG_ 1009 BMS_DischrgnCurrLager 1000;
BA_ "GenSigCycleTime" SG_ 1009 BMS_ModuleMismatchWarn 1000;
BA_ "GenSigCycleTime" SG_ 1009 BMS_cohrnc 1000;
BA_ "GenSigStartValue" SG_ 1009 BMS_moduleNumber 1;
BA_ "GenSigCycleTime" SG_ 1009 BMS_moduleNumber 1000;
BA_ "GenSigStartValue" SG_ 1009 BMS_NumModuleTempSnsr 1;
BA_ "GenSigCycleTime" SG_ 1009 BMS_NumModuleTempSnsr 1000;
BA_ "GenSigStartValue" SG_ 1009 BMS_NumCell 1;
BA_ "GenSigCycleTime" SG_ 1009 BMS_NumCell 1000;
BA_ "TransparentInitValue" SG_ 1009 BMS30_0x3F1 "0 0 0 1 1 1 0 0 ";
BA_ "GenSigCycleTime" SG_ 1009 BMS30_0x3F1 1000;
BA_ "GenSigCycleTime" SG_ 1010 BMS_CellVoltMin 1000;
BA_ "GenSigCycleTime" SG_ 1010 BMS_NumberCellVoltMin 1000;
BA_ "GenSigCycleTime" SG_ 1010 BMS_CellMaxVolt 1000;
BA_ "GenSigCycleTime" SG_ 1010 BMS_NumberCellMaxVolt 1000;
BA_ "GenSigCycleTime" SG_ 1010 BMS_CellBalanceSts 1000;
BA_ "GenSigCycleTime" SG_ 1010 BMS_RlyCounterSts 1000;
BA_ "GenSigCycleTime" SG_ 1010 BMS_SOH_R 1000;
BA_ "GenSigStartValue" SG_ 1011 BMS_ModuleMinTemp 65;
BA_ "GenSigCycleTime" SG_ 1011 BMS_ModuleMinTemp 1000;
BA_ "GenSigStartValue" SG_ 1011 BMS_ModuleNumCellMinTemp 1;
BA_ "GenSigCycleTime" SG_ 1011 BMS_ModuleNumCellMinTemp 1000;
BA_ "GenSigStartValue" SG_ 1011 BMS_ModuleNumCellMaxTemp 1;
BA_ "GenSigCycleTime" SG_ 1011 BMS_ModuleNumCellMaxTemp 1000;
BA_ "GenSigStartValue" SG_ 1011 BMS_ModuleMaxTemp 65;
BA_ "GenSigCycleTime" SG_ 1011 BMS_ModuleMaxTemp 1000;
BA_ "GenSigStartValue" SG_ 1011 BMS_NumCellMinTemp 1;
BA_ "GenSigCycleTime" SG_ 1011 BMS_NumCellMinTemp 1000;
BA_ "GenSigStartValue" SG_ 1011 BMS_NumCellMaxTemp 1;
BA_ "GenSigCycleTime" SG_ 1011 BMS_NumCellMaxTemp 1000;
BA_ "GenSigCycleTime" SG_ 1011 BMS_BattOverTempWarn 1000;
BA_ "GenSigStartValue" SG_ 1011 BMS_ModuleNumberCellMinVolt 1;
BA_ "GenSigCycleTime" SG_ 1011 BMS_ModuleNumberCellMinVolt 1000;
BA_ "GenSigStartValue" SG_ 1011 BMS_ModuleNumberCellMaxVolt 1;
BA_ "GenSigCycleTime" SG_ 1011 BMS_ModuleNumberCellMaxVolt 1000;
BA_ "GenSigStartValue" SG_ 790 OBC_ModSts 1;
BA_ "GenSigCycleTime" SG_ 790 OBC_ModSts 200;
BA_ "TransparentInitValue" SG_ 790 OBC1_0x316 "0 0 1 0 0 0 0 0 ";
BA_ "GenSigCycleTime" SG_ 790 OBC1_0x316 200;
BA_ "GenSigCycleTime" SG_ 791 OBC_ConnectSts 200;
BA_ "TransparentInitValue" SG_ 791 OBC2_0x317 "0 0 0 0 0 0 0 0 ";
BA_ "GenSigCycleTime" SG_ 791 OBC2_0x317 200;
BA_ "GenSigCycleTime" SG_ 96 HCU_AccelPedalPosn_Diag 10;
BA_ "GenSigStartValue" SG_ 96 HCU_AccelPedalPosn_DiagValid 1;
BA_ "GenSigCycleTime" SG_ 96 HCU_AccelPedalPosn_DiagValid 10;
BA_ "GenSigStartValue" SG_ 96 TMCU_ActRotSpd 65534;
BA_ "GenSigCycleTime" SG_ 96 TMCU_ActRotSpd 10;
BA_ "GenSigCycleTime" SG_ 96 HCU_PowertrainSts 10;
BA_ "GenSigCycleTime" SG_ 96 HCU_RaceLaunchSts 10;
BA_ "GenSigCycleTime" SG_ 96 HCU_RaceLaunchAvail 10;
BA_ "TransparentInitValue" SG_ 96 HCU_FD1_0x60 "0 0 0 0 0 0 0 0 0 0 32 0 0 255 254 0 0 0 0 0 0 0 0 0 0 0 0 0 0 0 0 0 0 0 0 0 0 0 0 0 0 0 0 0 0 0 0 0 0 0 0 0 0 0 0 0 0 0 0 0 0 0 0 0 ";
BA_ "GenSigCycleTime" SG_ 96 HCU_FD1_0x60 10;
BA_ "GenSigCycleTime" SG_ 330 HCU_DrvMod 20;
BA_ "GenSigCycleTime" SG_ 330 HCUImmoAuthRes 20;
BA_ "GenSigCycleTime" SG_ 330 HCU_EVLmpSts 20;
BA_ "GenSigStartValue" SG_ 330 HCU_ECODrvHabit_Indcn 100;
BA_ "GenSigCycleTime" SG_ 330 HCU_ECODrvHabit_Indcn 20;
BA_ "GenSigStartValue" SG_ 330 HCU_TotDrvReqPower 100;
BA_ "GenSigCycleTime" SG_ 330 HCU_TotDrvReqPower 20;
BA_ "GenSigCycleTime" SG_ 330 HCU_AvailPower_TM 20;
BA_ "TransparentInitValue" SG_ 330 HCU_PT5_0x14A "0 0 0 100 100 0 0 0 ";
BA_ "GenSigCycleTime" SG_ 330 HCU_PT5_0x14A 20;
BA_ "GenSigCycleTime" SG_ 584 CheckSum_HCU_PT7 50;
BA_ "GenSigCycleTime" SG_ 584 HCU_HybSysErr_1 50;
BA_ "GenSigCycleTime" SG_ 584 HCU_HybSysErr_2 50;
BA_ "GenSigCycleTime" SG_ 584 HCU_HybSysErr_3 50;
BA_ "GenSigCycleTime" SG_ 584 HCU_HybSysErr_4 50;
BA_ "GenSigCycleTime" SG_ 584 HCU_HybSysErr_5 50;
BA_ "GenSigCycleTime" SG_ 584 HCU_HybSysErr_6 50;
BA_ "GenSigCycleTime" SG_ 584 HCU_HybSysErr_7 50;
BA_ "GenSigCycleTime" SG_ 584 HCU_12VSysErrLmpSts 50;
BA_ "GenSigCycleTime" SG_ 584 HCU_HybSysErrLmpSts 50;
BA_ "GenSigCycleTime" SG_ 584 HCU_PowerRedWarnLmpCmd 50;
BA_ "GenSigCycleTime" SG_ 584 HCU_12VSysErr_1 50;
BA_ "GenSigCycleTime" SG_ 584 HCU_12VSysErr_2 50;
BA_ "GenSigCycleTime" SG_ 584 HCU_RdyLmpSts 50;
BA_ "GenSigCycleTime" SG_ 584 HCU_ModSwtFail 50;
BA_ "GenSigCycleTime" SG_ 584 HCU_EnrgFlowInd 50;
BA_ "GenSigCycleTime" SG_ 584 HCU_OPDSts 50;
BA_ "GenSigCycleTime" SG_ 584 HCU_OPDLmpSts 50;
BA_ "GenSigCycleTime" SG_ 584 RollingCounter_HCU_PT7 50;
BA_ "TransparentInitValue" SG_ 584 HCU_PT7_0x248 "0 0 0 0 0 0 0 0 ";
BA_ "GenSigCycleTime" SG_ 584 HCU_PT7_0x248 50;
BA_ "GenSigCycleTime" SG_ 448 HCU_ChrgSysLmpSts 50;
BA_ "GenSigCycleTime" SG_ 448 HCU_ChrgSysErr_1 50;
BA_ "GenSigCycleTime" SG_ 448 HCU_ChrgSysErr_2 50;
BA_ "GenSigCycleTime" SG_ 448 HCU_ChrgSysErr_3 50;
BA_ "GenSigCycleTime" SG_ 448 HCU_ChrgSysErr_4 50;
BA_ "GenSigCycleTime" SG_ 448 HCU_ChrgSysErr_5 50;
BA_ "GenSigCycleTime" SG_ 448 HCU_ChrgSysErr_6 50;
BA_ "GenSigCycleTime" SG_ 448 HCU_ChrgSysErr_7 50;
BA_ "GenSigCycleTime" SG_ 448 HCU_ChrgSysErr_8 50;
BA_ "TransparentInitValue" SG_ 448 HCU_PT8_0x1C0 "0 0 0 0 0 0 0 0 ";
BA_ "GenSigCycleTime" SG_ 448 HCU_PT8_0x1C0 50;
BA_ "GenSigCycleTime" SG_ 762 CheckSum_HCU_PT4 100;
BA_ "GenSigCycleTime" SG_ 762 HCU_BattPowerRedWarn 100;
BA_ "GenSigCycleTime" SG_ 762 HCU_EnerSavePowerMod 100;
BA_ "GenSigCycleTime" SG_ 762 HCU_SOCLow_Indcn 100;
BA_ "GenSigCycleTime" SG_ 762 HCU_RemoveChrgLine_Indcn 100;
BA_ "GenSigCycleTime" SG_ 762 HCU_WadeModeSetSts 100;
BA_ "GenSigCycleTime" SG_ 762 HCU_Shift_P_Indcn 100;
BA_ "GenSigCycleTime" SG_ 762 HCU_ConnectChrgLine_Indcn 100;
BA_ "GenSigCycleTime" SG_ 762 HCU_EgyRecFB 100;
BA_ "GenSigStartValue" SG_ 762 HCU_ACStsReq 2;
BA_ "GenSigCycleTime" SG_ 762 HCU_ACStsReq 100;
BA_ "GenSigCycleTime" SG_ 762 HCU_RefuReq 100;
BA_ "GenSigCycleTime" SG_ 762 HCU_OilTankCoverSts 100;
BA_ "GenSigCycleTime" SG_ 762 HCU_InhbChrgInfo 100;
BA_ "GenSigCycleTime" SG_ 762 OPDParkWarnReq 100;
BA_ "GenSigCycleTime" SG_ 762 HCU_OPDFail 100;
BA_ "GenSigCycleTime" SG_ 762 CarWashMode_StsDisp 100;
BA_ "GenSigCycleTime" SG_ 762 CarWashMode_Sts 100;
BA_ "GenSigCycleTime" SG_ 762 HCU_RefuBtnSts 100;
BA_ "GenSigCycleTime" SG_ 762 RollingCounter_HCU_PT4 100;
BA_ "TransparentInitValue" SG_ 762 HCU_PT4_0x2FA "0 0 0 0 0 0 4 0 ";
BA_ "GenSigCycleTime" SG_ 762 HCU_PT4_0x2FA 100;
BA_ "GenSigCycleTime" SG_ 513 Checksum_HCU_HP5 50;
BA_ "GenSigCycleTime" SG_ 513 HCU_EnrgFlowInd_DHT 50;
BA_ "GenSigCycleTime" SG_ 513 HCU_PrsBrkWarn 50;
BA_ "GenSigCycleTime" SG_ 513 DrvModDisp_0x201 50;
BA_ "GenSigCycleTime" SG_ 513 DrvModDispSts_0x201 50;
BA_ "GenSigCycleTime" SG_ 513 DrvGearDisp 50;
BA_ "GenSigCycleTime" SG_ 513 DrvGearDispSts_0x201 50;
BA_ "GenSigCycleTime" SG_ 513 HCU_ShftNotAlwd_Warn 50;
BA_ "GenSigCycleTime" SG_ 513 DrvFaiMsg_0x201 50;
BA_ "GenSigCycleTime" SG_ 513 RollingCounter_HCU_HP5 50;
BA_ "TransparentInitValue" SG_ 513 HCU_HP5_0x201 "0 0 0 0 0 0 0 0 ";
BA_ "GenSigCycleTime" SG_ 513 HCU_HP5_0x201 50;
BA_ "GenSigCycleTime" SG_ 288 IB_Warn 20;
BA_ "TransparentInitValue" SG_ 288 Ibooster_FD2_0x120 "0 0 0 0 0 0 0 0 0 0 0 0 0 0 0 0 0 0 0 0 0 0 0 0 0 0 0 0 0 0 0 0 0 0 0 0 0 0 0 0 0 0 0 0 0 0 0 0 0 0 0 0 0 0 0 0 0 0 0 0 0 0 0 0 ";
BA_ "GenSigCycleTime" SG_ 288 Ibooster_FD2_0x120 20;
BA_ "GenSigCycleTime" SG_ 200 ESP_HMI_WarningOn 10;
BA_ "TransparentInitValue" SG_ 200 ESP11_0xC8 "0 0 0 0 0 0 0 0 ";
BA_ "GenSigCycleTime" SG_ 200 ESP11_0xC8 10;
BA_ "GenSigCycleTime" SG_ 216 TgtRcprtnTrqSts 10;
BA_ "TransparentInitValue" SG_ 216 ESP10_0xD8 "0 0 0 0 0 0 0 0 ";
BA_ "GenSigCycleTime" SG_ 216 ESP10_0xD8 10;
BA_ "GenSigCycleTime" SG_ 957 DCDC_Tempwarning_RM 1000;
BA_ "GenSigCycleTime" SG_ 957 DCDC_ActSts_RM 1000;
BA_ "GenSigCycleTime" SG_ 957 DCDC_FailStswarning_RM 1000;
BA_ "GenSigCycleTime" SG_ 969 TMCU_Amount_RM 1000;
BA_ "GenSigCycleTime" SG_ 969 TMCU_MotorSerNumber_RM 1000;
BA_ "GenSigStartValue" SG_ 969 TMCU_InvActTemp_RM 65;
BA_ "GenSigCycleTime" SG_ 969 TMCU_InvActTemp_RM 1000;
BA_ "GenSigStartValue" SG_ 969 TMCU_ActSpd_RM 20000;
BA_ "GenSigCycleTime" SG_ 969 TMCU_ActSpd_RM 1000;
BA_ "GenSigStartValue" SG_ 969 TMCU_ActTrq_RM 20000;
BA_ "GenSigCycleTime" SG_ 969 TMCU_ActTrq_RM 1000;
BA_ "TransparentInitValue" SG_ 969 TMCU_FD3_0x3C9 "0 0 65 78 32 78 32 0 ";
BA_ "GenSigCycleTime" SG_ 969 TMCU_FD3_0x3C9 1000;
BA_ "GenSigStartValue" SG_ 948 TMCU_ActHvDcCurr_RM 1000;
BA_ "GenSigCycleTime" SG_ 948 TMCU_ActHvDcCurr_RM 1000;
BA_ "GenSigCycleTime" SG_ 948 TMCU_ActHvDcVolt_RM 1000;
BA_ "GenSigStartValue" SG_ 948 TMCU_ActTemp_RM 65;
BA_ "GenSigCycleTime" SG_ 948 TMCU_ActTemp_RM 1000;
BA_ "GenSigCycleTime" SG_ 948 TMCU_Tempwarning_RM 1000;
BA_ "GenSigCycleTime" SG_ 948 TMCU_InvTempwarning_RM 1000;
BA_ "GenSigStartValue" SG_ 948 TMCU_OperMode_RM 4;
BA_ "GenSigCycleTime" SG_ 948 TMCU_OperMode_RM 1000;
BA_ "GenSigStartValue" SG_ 977 BMS_BattModuleTe_11 65;
BA_ "GenSigCycleTime" SG_ 977 BMS_BattModuleTe_11 1000;
BA_ "GenSigStartValue" SG_ 977 BMS_BattModuleTe_12 65;
BA_ "GenSigCycleTime" SG_ 977 BMS_BattModuleTe_12 1000;
BA_ "GenSigStartValue" SG_ 977 BMS_BattModuleTe_21 65;
BA_ "GenSigCycleTime" SG_ 977 BMS_BattModuleTe_21 1000;
BA_ "GenSigStartValue" SG_ 977 BMS_BattModuleTe_22 65;
BA_ "GenSigCycleTime" SG_ 977 BMS_BattModuleTe_22 1000;
BA_ "GenSigStartValue" SG_ 977 BMS_BattModuleTe_31 65;
BA_ "GenSigCycleTime" SG_ 977 BMS_BattModuleTe_31 1000;
BA_ "GenSigStartValue" SG_ 977 BMS_BattModuleTe_32 65;
BA_ "GenSigCycleTime" SG_ 977 BMS_BattModuleTe_32 1000;
BA_ "GenSigStartValue" SG_ 977 BMS_BattModuleTe_41 65;
BA_ "GenSigCycleTime" SG_ 977 BMS_BattModuleTe_41 1000;
BA_ "GenSigStartValue" SG_ 977 BMS_BattModuleTe_42 65;
BA_ "GenSigCycleTime" SG_ 977 BMS_BattModuleTe_42 1000;
BA_ "GenSigStartValue" SG_ 977 BMS_BattModuleTe_51 65;
BA_ "GenSigCycleTime" SG_ 977 BMS_BattModuleTe_51 1000;
BA_ "GenSigStartValue" SG_ 977 BMS_BattModuleTe_52 65;
BA_ "GenSigCycleTime" SG_ 977 BMS_BattModuleTe_52 1000;
BA_ "GenSigStartValue" SG_ 977 BMS_BattModuleTe_61 65;
BA_ "GenSigCycleTime" SG_ 977 BMS_BattModuleTe_61 1000;
BA_ "GenSigStartValue" SG_ 977 BMS_BattModuleTe_62 65;
BA_ "GenSigCycleTime" SG_ 977 BMS_BattModuleTe_62 1000;
BA_ "GenSigStartValue" SG_ 977 BMS_BattModuleTe_71 65;
BA_ "GenSigCycleTime" SG_ 977 BMS_BattModuleTe_71 1000;
BA_ "GenSigStartValue" SG_ 977 BMS_BattModuleTe_72 65;
BA_ "GenSigCycleTime" SG_ 977 BMS_BattModuleTe_72 1000;
BA_ "GenSigStartValue" SG_ 977 BMS_BattModuleTe_81 65;
BA_ "GenSigCycleTime" SG_ 977 BMS_BattModuleTe_81 1000;
BA_ "GenSigStartValue" SG_ 977 BMS_BattModuleTe_82 65;
BA_ "GenSigCycleTime" SG_ 977 BMS_BattModuleTe_82 1000;
BA_ "GenSigCycleTime" SG_ 977 BMS_SingleCellVolt_1 1000;
BA_ "GenSigCycleTime" SG_ 977 BMS_SingleCellVolt_2 1000;
BA_ "GenSigCycleTime" SG_ 977 BMS_SingleCellVolt_3 1000;
BA_ "GenSigCycleTime" SG_ 977 BMS_SingleCellVolt_4 1000;
BA_ "GenSigCycleTime" SG_ 977 BMS_SingleCellVolt_5 1000;
BA_ "GenSigCycleTime" SG_ 977 BMS_SingleCellVolt_6 1000;
BA_ "GenSigCycleTime" SG_ 977 BMS_SingleCellVolt_7 1000;
BA_ "GenSigCycleTime" SG_ 977 BMS_SingleCellVolt_8 1000;
BA_ "GenSigCycleTime" SG_ 977 BMS_SingleCellVolt_9 1000;
BA_ "GenSigCycleTime" SG_ 977 BMS_SingleCellVolt_10 1000;
BA_ "GenSigCycleTime" SG_ 977 BMS_SingleCellVolt_11 1000;
BA_ "GenSigCycleTime" SG_ 977 BMS_SingleCellVolt_12 1000;
BA_ "GenSigCycleTime" SG_ 978 BMS_SingleCellVolt_13 1000;
BA_ "GenSigCycleTime" SG_ 978 BMS_SingleCellVolt_14 1000;
BA_ "GenSigCycleTime" SG_ 978 BMS_SingleCellVolt_15 1000;
BA_ "GenSigCycleTime" SG_ 978 BMS_SingleCellVolt_16 1000;
BA_ "GenSigCycleTime" SG_ 978 BMS_SingleCellVolt_17 1000;
BA_ "GenSigCycleTime" SG_ 978 BMS_SingleCellVolt_18 1000;
BA_ "GenSigCycleTime" SG_ 978 BMS_SingleCellVolt_19 1000;
BA_ "GenSigCycleTime" SG_ 978 BMS_SingleCellVolt_20 1000;
BA_ "GenSigCycleTime" SG_ 978 BMS_SingleCellVolt_21 1000;
BA_ "GenSigCycleTime" SG_ 978 BMS_SingleCellVolt_22 1000;
BA_ "GenSigCycleTime" SG_ 978 BMS_SingleCellVolt_23 1000;
BA_ "GenSigCycleTime" SG_ 978 BMS_SingleCellVolt_24 1000;
BA_ "GenSigCycleTime" SG_ 978 BMS_SingleCellVolt_25 1000;
BA_ "GenSigCycleTime" SG_ 978 BMS_SingleCellVolt_26 1000;
BA_ "GenSigCycleTime" SG_ 978 BMS_SingleCellVolt_27 1000;
BA_ "GenSigCycleTime" SG_ 978 BMS_SingleCellVolt_28 1000;
BA_ "GenSigCycleTime" SG_ 978 BMS_SingleCellVolt_29 1000;
BA_ "GenSigCycleTime" SG_ 978 BMS_SingleCellVolt_30 1000;
BA_ "GenSigCycleTime" SG_ 978 BMS_SingleCellVolt_31 1000;
BA_ "GenSigCycleTime" SG_ 978 BMS_SingleCellVolt_32 1000;
BA_ "GenSigCycleTime" SG_ 978 BMS_SingleCellVolt_33 1000;
BA_ "GenSigCycleTime" SG_ 978 BMS_SingleCellVolt_34 1000;
BA_ "GenSigCycleTime" SG_ 978 BMS_SingleCellVolt_35 1000;
BA_ "GenSigCycleTime" SG_ 978 BMS_SingleCellVolt_36 1000;
BA_ "GenSigCycleTime" SG_ 978 BMS_SingleCellVolt_37 1000;
BA_ "GenSigCycleTime" SG_ 978 BMS_SingleCellVolt_38 1000;
BA_ "GenSigCycleTime" SG_ 978 BMS_SingleCellVolt_39 1000;
BA_ "GenSigCycleTime" SG_ 978 BMS_SingleCellVolt_40 1000;
BA_ "GenSigCycleTime" SG_ 979 BMS_SingleCellVolt_41 1000;
BA_ "GenSigCycleTime" SG_ 979 BMS_SingleCellVolt_42 1000;
BA_ "GenSigCycleTime" SG_ 979 BMS_SingleCellVolt_43 1000;
BA_ "GenSigCycleTime" SG_ 979 BMS_SingleCellVolt_44 1000;
BA_ "GenSigCycleTime" SG_ 979 BMS_SingleCellVolt_45 1000;
BA_ "GenSigCycleTime" SG_ 979 BMS_SingleCellVolt_46 1000;
BA_ "GenSigCycleTime" SG_ 979 BMS_SingleCellVolt_47 1000;
BA_ "GenSigCycleTime" SG_ 979 BMS_SingleCellVolt_48 1000;
BA_ "GenSigCycleTime" SG_ 979 BMS_SingleCellVolt_49 1000;
BA_ "GenSigCycleTime" SG_ 979 BMS_SingleCellVolt_50 1000;
BA_ "GenSigCycleTime" SG_ 979 BMS_SingleCellVolt_51 1000;
BA_ "GenSigCycleTime" SG_ 979 BMS_SingleCellVolt_52 1000;
BA_ "GenSigCycleTime" SG_ 979 BMS_SingleCellVolt_53 1000;
BA_ "GenSigCycleTime" SG_ 979 BMS_SingleCellVolt_54 1000;
BA_ "GenSigCycleTime" SG_ 979 BMS_SingleCellVolt_55 1000;
BA_ "GenSigCycleTime" SG_ 979 BMS_SingleCellVolt_56 1000;
BA_ "GenSigCycleTime" SG_ 979 BMS_SingleCellVolt_57 1000;
BA_ "GenSigCycleTime" SG_ 979 BMS_SingleCellVolt_58 1000;
BA_ "GenSigCycleTime" SG_ 979 BMS_SingleCellVolt_59 1000;
BA_ "GenSigCycleTime" SG_ 979 BMS_SingleCellVolt_60 1000;
BA_ "GenSigCycleTime" SG_ 979 BMS_SingleCellVolt_61 1000;
BA_ "GenSigCycleTime" SG_ 979 BMS_SingleCellVolt_62 1000;
BA_ "GenSigCycleTime" SG_ 979 BMS_SingleCellVolt_63 1000;
BA_ "GenSigCycleTime" SG_ 979 BMS_SingleCellVolt_64 1000;
BA_ "GenSigCycleTime" SG_ 979 BMS_SingleCellVolt_65 1000;
BA_ "GenSigCycleTime" SG_ 979 BMS_SingleCellVolt_66 1000;
BA_ "GenSigCycleTime" SG_ 979 BMS_SingleCellVolt_67 1000;
BA_ "GenSigCycleTime" SG_ 979 BMS_SingleCellVolt_68 1000;
BA_ "GenSigCycleTime" SG_ 980 BMS_SingleCellVolt_69 1000;
BA_ "GenSigCycleTime" SG_ 980 BMS_SingleCellVolt_70 1000;
BA_ "GenSigCycleTime" SG_ 980 BMS_SingleCellVolt_71 1000;
BA_ "GenSigCycleTime" SG_ 980 BMS_SingleCellVolt_72 1000;
BA_ "GenSigCycleTime" SG_ 980 BMS_SingleCellVolt_73 1000;
BA_ "GenSigCycleTime" SG_ 980 BMS_SingleCellVolt_74 1000;
BA_ "GenSigCycleTime" SG_ 980 BMS_SingleCellVolt_75 1000;
BA_ "GenSigCycleTime" SG_ 980 BMS_SingleCellVolt_76 1000;
BA_ "GenSigCycleTime" SG_ 980 BMS_SingleCellVolt_77 1000;
BA_ "GenSigCycleTime" SG_ 980 BMS_SingleCellVolt_78 1000;
BA_ "GenSigCycleTime" SG_ 980 BMS_SingleCellVolt_79 1000;
BA_ "GenSigCycleTime" SG_ 980 BMS_SingleCellVolt_80 1000;
BA_ "GenSigCycleTime" SG_ 980 BMS_SingleCellVolt_81 1000;
BA_ "GenSigCycleTime" SG_ 980 BMS_SingleCellVolt_82 1000;
BA_ "GenSigCycleTime" SG_ 980 BMS_SingleCellVolt_83 1000;
BA_ "GenSigCycleTime" SG_ 980 BMS_SingleCellVolt_84 1000;
BA_ "GenSigCycleTime" SG_ 980 BMS_SingleCellVolt_85 1000;
BA_ "GenSigCycleTime" SG_ 980 BMS_SingleCellVolt_86 1000;
BA_ "GenSigCycleTime" SG_ 980 BMS_SingleCellVolt_87 1000;
BA_ "GenSigCycleTime" SG_ 980 BMS_SingleCellVolt_88 1000;
BA_ "GenSigCycleTime" SG_ 980 BMS_SingleCellVolt_89 1000;
BA_ "GenSigCycleTime" SG_ 980 BMS_SingleCellVolt_90 1000;
BA_ "GenSigCycleTime" SG_ 980 BMS_SingleCellVolt_91 1000;
BA_ "GenSigCycleTime" SG_ 980 BMS_SingleCellVolt_92 1000;
BA_ "GenSigCycleTime" SG_ 980 BMS_SingleCellVolt_93 1000;
BA_ "GenSigCycleTime" SG_ 980 BMS_SingleCellVolt_94 1000;
BA_ "GenSigCycleTime" SG_ 980 BMS_SingleCellVolt_95 1000;
BA_ "GenSigCycleTime" SG_ 980 BMS_SingleCellVolt_96 1000;
BA_ "GenSigCycleTime" SG_ 981 BMS_SingleCellVolt_97 1000;
BA_ "GenSigCycleTime" SG_ 981 BMS_SingleCellVolt_98 1000;
BA_ "GenSigCycleTime" SG_ 981 BMS_SingleCellVolt_99 1000;
BA_ "GenSigCycleTime" SG_ 981 BMS_SingleCellVolt_100 1000;
BA_ "GenSigCycleTime" SG_ 981 BMS_SingleCellVolt_101 1000;
BA_ "GenSigCycleTime" SG_ 981 BMS_SingleCellVolt_102 1000;
BA_ "GenSigCycleTime" SG_ 981 BMS_SingleCellVolt_103 1000;
BA_ "GenSigCycleTime" SG_ 981 BMS_SingleCellVolt_104 1000;
BA_ "GenSigCycleTime" SG_ 981 BMS_SingleCellVolt_105 1000;
BA_ "GenSigCycleTime" SG_ 981 BMS_SingleCellVolt_106 1000;
BA_ "GenSigCycleTime" SG_ 981 BMS_SingleCellVolt_107 1000;
BA_ "GenSigCycleTime" SG_ 981 BMS_SingleCellVolt_108 1000;
BA_ "GenSigCycleTime" SG_ 981 BMS_SingleCellVolt_109 1000;
BA_ "GenSigCycleTime" SG_ 981 BMS_SingleCellVolt_110 1000;
BA_ "GenSigCycleTime" SG_ 981 BMS_SingleCellVolt_111 1000;
BA_ "GenSigCycleTime" SG_ 981 BMS_SingleCellVolt_112 1000;
BA_ "GenSigStartValue" SG_ 981 BMS_BattModuleTe_91 65;
BA_ "GenSigCycleTime" SG_ 981 BMS_BattModuleTe_91 1000;
BA_ "GenSigStartValue" SG_ 981 BMS_BattModuleTe_92 65;
BA_ "GenSigCycleTime" SG_ 981 BMS_BattModuleTe_92 1000;
BA_ "GenSigCycleTime" SG_ 981 BMS_DTCNumber 1000;
BA_ "GenSigCycleTime" SG_ 981 BMS_SWVersion_PHEV 1000;
BA_ "GenSigStartValue" SG_ 981 BMS_NumberCellVoltMin_RM 1;
BA_ "GenSigCycleTime" SG_ 981 BMS_NumberCellVoltMin_RM 1000;
BA_ "GenSigCycleTime" SG_ 981 BMS_ModuleMaxTemp_RM 1000;
BA_ "GenSigStartValue" SG_ 981 BMS_BattModuleTe_13 65;
BA_ "GenSigCycleTime" SG_ 981 BMS_BattModuleTe_13 1000;
BA_ "GenSigStartValue" SG_ 981 BMS_BattModuleTe_23 65;
BA_ "GenSigCycleTime" SG_ 981 BMS_BattModuleTe_23 1000;
BA_ "GenSigStartValue" SG_ 981 BMS_BattModuleTe_33 65;
BA_ "GenSigCycleTime" SG_ 981 BMS_BattModuleTe_33 1000;
BA_ "GenSigStartValue" SG_ 981 BMS_BattModuleTe_43 65;
BA_ "GenSigCycleTime" SG_ 981 BMS_BattModuleTe_43 1000;
BA_ "GenSigStartValue" SG_ 981 BMS_BattModuleTe_53 65;
BA_ "GenSigCycleTime" SG_ 981 BMS_BattModuleTe_53 1000;
BA_ "GenSigStartValue" SG_ 981 BMS_BattModuleTe_63 65;
BA_ "GenSigCycleTime" SG_ 981 BMS_BattModuleTe_63 1000;
BA_ "GenSigCycleTime" SG_ 1008 BMS_CellMaxVolt_RM 1000;
BA_ "GenSigCycleTime" SG_ 1008 BMS_CellVoltMin_RM 1000;
BA_ "GenSigStartValue" SG_ 1008 BMS_NumCellMaxTemp_RM 1;
BA_ "GenSigCycleTime" SG_ 1008 BMS_NumCellMaxTemp_RM 1000;
BA_ "GenSigStartValue" SG_ 1008 BMS_NumCellMinTemp_RM 1;
BA_ "GenSigCycleTime" SG_ 1008 BMS_NumCellMinTemp_RM 1000;
BA_ "GenSigCycleTime" SG_ 1008 BMS_ModuleMinTemp_RM 1000;
BA_ "GenSigStartValue" SG_ 1008 BMS_NumberCellVoltMax_RM 1;
BA_ "GenSigCycleTime" SG_ 1008 BMS_NumberCellVoltMax_RM 1000;
BA_ "GenSigCycleTime" SG_ 1008 BMS_SocJumpWarn_RM 1000;
BA_ "GenSigCycleTime" SG_ 1008 BMS_PackOverChrgWarn_RM 1000;
BA_ "GenSigStartValue" SG_ 1008 BMS_IsolationRValue_RM 10000;
BA_ "GenSigCycleTime" SG_ 1008 BMS_IsolationRValue_RM 1000;
BA_ "GenSigCycleTime" SG_ 1008 BMS_PackCurr_RM 1000;
BA_ "GenSigCycleTime" SG_ 1008 BMS_SocOverWarn_RM 1000;
BA_ "GenSigCycleTime" SG_ 1008 BMS_BattOverTempRank_RM 1000;
BA_ "GenSigCycleTime" SG_ 1008 BMS_BattOverVoltRank_RM 1000;
BA_ "GenSigCycleTime" SG_ 1008 BMS_BattSOCLowRank_RM 1000;
BA_ "GenSigCycleTime" SG_ 1008 BMS_VCUIsolateErr_RM 1000;
BA_ "GenSigCycleTime" SG_ 1008 BMS_BattUnderVoltRank_RM 1000;
BA_ "GenSigCycleTime" SG_ 1008 BMS_CellDeltaVoltRank_RM 1000;
BA_ "GenSigCycleTime" SG_ 1008 BMS_CellOverVoltRank_RM 1000;
BA_ "GenSigCycleTime" SG_ 1008 BMS_CellUnderVoltRank_RM 1000;
BA_ "GenSigCycleTime" SG_ 1008 BMS_DeltaTempRank_RM 1000;
BA_ "GenSigCycleTime" SG_ 1008 BMS_PackMismatchWarn_RM 1000;
BA_ "GenSigCycleTime" SG_ 1008 BMS_PackVolt_RM 1000;
BA_ "GenSigStartValue" SG_ 1008 BMS_SysNumberCellVoltMax_RM 1;
BA_ "GenSigCycleTime" SG_ 1008 BMS_SysNumberCellVoltMax_RM 1000;
BA_ "GenSigStartValue" SG_ 1008 BMS_SysNumberCellVoltMin_RM 1;
BA_ "GenSigCycleTime" SG_ 1008 BMS_SysNumberCellVoltMin_RM 1000;
BA_ "GenSigStartValue" SG_ 1008 BMS_SysNumCellMaxTemp_RM 1;
BA_ "GenSigCycleTime" SG_ 1008 BMS_SysNumCellMaxTemp_RM 1000;
BA_ "GenSigStartValue" SG_ 1008 BMS_SysNumCellMinTemp_RM 1;
BA_ "GenSigCycleTime" SG_ 1008 BMS_SysNumCellMinTemp_RM 1000;
BA_ "GenSigStartValue" SG_ 1008 BMS_BattSysNum_RM 1;
BA_ "GenSigCycleTime" SG_ 1008 BMS_BattSysNum_RM 1000;
BA_ "GenSigSendType" SG_ 483 BMS_BattKeepTempResp_PHEV 2;
BA_ "GenSigCycleTime" SG_ 147 TMCU_ActPosRotSpd 10;
BA_ "TransparentInitValue" SG_ 147 TMCU6_0x93 "0 0 0 0 0 0 0 0 ";
BA_ "GenSigCycleTime" SG_ 147 TMCU6_0x93 10;
BA_ "GenSigCycleTime" SG_ 193 CheckSum_DHT1 10;
BA_ "GenSigCycleTime" SG_ 193 TCU_ClutchHotWarning 10;
BA_ "GenSigCycleTime" SG_ 193 TCU_ErrCategory 10;
BA_ "GenSigCycleTime" SG_ 193 RollingCounter_DHT1 10;
BA_ "TransparentInitValue" SG_ 193 DHT_FD1_0xC1 "0 0 0 0 0 0 0 0 0 0 0 0 0 0 0 0 0 0 0 0 0 0 0 0 0 0 0 0 0 0 0 0 0 0 0 0 0 0 0 0 0 0 0 0 0 0 0 0 0 0 0 0 0 0 0 0 0 0 0 0 0 0 0 0 ";
BA_ "GenSigCycleTime" SG_ 193 DHT_FD1_0xC1 10;
BA_ "GenSigStartValue" SG_ 282 HCU_GearSts 14;
BA_ "GenSigCycleTime" SG_ 282 HCU_GearSts 20;
BA_ "TransparentInitValue" SG_ 282 HCU_HP6_0x11A "0 0 0 0 28 0 0 0 ";
BA_ "GenSigCycleTime" SG_ 282 HCU_HP6_0x11A 20;
BA_ "GenSigStartValue" SG_ 265 IFCTrqOvlCmdProtnValue 7169;
BA_ "GenSigCycleTime" SG_ 265 IFCTrqOvlCmdProtnValue 20;
BA_ "GenSigStartValue" SG_ 265 IFCTrqOvlCmdReqValue 1023;
BA_ "GenSigCycleTime" SG_ 265 IFCTrqOvlCmdReqValue 20;
BA_ "TransparentInitValue" SG_ 265 IFC1_0x109 "0 112 4 0 127 224 0 0 ";
BA_ "GenSigCycleTime" SG_ 265 IFC1_0x109 20;
BA_ "GenSigCycleTime" SG_ 350 CR_FCTA_Resp 20;
BA_ "GenSigCycleTime" SG_ 350 CR_FCTB_Resp 20;
BA_ "GenSigCycleTime" SG_ 350 CR_BliSts 20;
BA_ "GenSigCycleTime" SG_ 350 FCTA_Warn 20;
BA_ "GenSigCycleTime" SG_ 350 FCTBTrig 20;
BA_ "GenSigCycleTime" SG_ 350 FCTA_B_FuncSts 20;
BA_ "GenSigCycleTime" SG_ 350 FCTA_B_TTC 20;
BA_ "TransparentInitValue" SG_ 350 CR_FD1_0x15E "0 0 0 0 0 0 0 0 0 0 0 0 0 0 0 0 0 0 0 0 0 0 0 0 0 0 0 0 0 0 0 0 0 0 0 0 0 0 0 0 0 0 0 0 0 0 0 0 0 0 0 0 0 0 0 0 0 0 0 0 0 0 0 0 ";
BA_ "GenSigCycleTime" SG_ 350 CR_FD1_0x15E 20;
BA_ "GenSigCycleTime" SG_ 692 AEB_LePedDetn 100;
BA_ "GenSigCycleTime" SG_ 692 AEB_LePedDy 100;
BA_ "GenSigCycleTime" SG_ 692 AEB_LePedTyp 100;
BA_ "GenSigCycleTime" SG_ 692 AEB_LePed_collisionprob 100;
BA_ "GenSigCycleTime" SG_ 692 AEB_RiPedDetn 100;
BA_ "GenSigCycleTime" SG_ 692 AEB_RiPedDy 100;
BA_ "GenSigCycleTime" SG_ 692 AEB_RiPedTyp 100;
BA_ "GenSigCycleTime" SG_ 692 AEB_RiPed_collisionprob 100;
BA_ "GenSigCycleTime" SG_ 692 AEB_LeCyclistDy 100;
BA_ "GenSigCycleTime" SG_ 692 AEB_LeCyclist_collisionprob 100;
BA_ "GenSigCycleTime" SG_ 692 AEB_RiCyclistDy 100;
BA_ "GenSigCycleTime" SG_ 692 AEB_RiCyclist_collisionprob 100;
BA_ "GenSigCycleTime" SG_ 692 JAPedObjExist 100;
BA_ "GenSigStartValue" SG_ 692 AEBJAObjID 255;
BA_ "GenSigCycleTime" SG_ 692 AEBJAObjID 100;
BA_ "GenSigCycleTime" SG_ 692 AEBJAObjExist 100;
BA_ "GenSigStartValue" SG_ 692 JAPedObjID 255;
BA_ "GenSigCycleTime" SG_ 692 JAPedObjID 100;
BA_ "GenSigCycleTime" SG_ 692 AEBJAObjVideoCfmd 100;
BA_ "GenSigCycleTime" SG_ 692 AEBJAObjVx 100;
BA_ "GenSigCycleTime" SG_ 692 AEBJAObjDx 100;
BA_ "GenSigCycleTime" SG_ 692 JAPedObjVideoCfmd 100;
BA_ "GenSigCycleTime" SG_ 692 AEBJAObjState 100;
BA_ "GenSigCycleTime" SG_ 692 AEBJAObjCntAlive 100;
BA_ "GenSigCycleTime" SG_ 692 AEBJAObjDy 100;
BA_ "GenSigCycleTime" SG_ 692 JAPedObjState 100;
BA_ "GenSigCycleTime" SG_ 692 AEBJAObjObstcl 100;
BA_ "GenSigCycleTime" SG_ 692 AEBJAObjVy 100;
BA_ "GenSigCycleTime" SG_ 692 AEBJAObjAx 100;
BA_ "GenSigCycleTime" SG_ 692 AEBJAObjAy 100;
BA_ "GenSigCycleTime" SG_ 692 JAPedObjObstcl 100;
BA_ "GenSigCycleTime" SG_ 692 JAPedObjDy 100;
BA_ "GenSigCycleTime" SG_ 692 JAPedObjDx 100;
BA_ "GenSigCycleTime" SG_ 692 FCWAEB_JATTC 100;
BA_ "GenSigCycleTime" SG_ 692 JAPedObjVx 100;
BA_ "GenSigCycleTime" SG_ 692 JAPedObjVy 100;
BA_ "GenSigCycleTime" SG_ 692 JAPedObjAy 100;
BA_ "GenSigCycleTime" SG_ 692 JAPedObjCntAlive 100;
BA_ "GenSigCycleTime" SG_ 692 FCWAEB_longTTC 100;
BA_ "GenSigCycleTime" SG_ 692 FCWAEB_crossingTTC 100;
BA_ "GenSigCycleTime" SG_ 692 JAPedObjAx 100;
BA_ "GenSigCycleTime" SG_ 692 AEB_LePedDx 100;
BA_ "GenSigCycleTime" SG_ 692 AEB_RiPedDx 100;
BA_ "GenSigCycleTime" SG_ 692 AEB_LeCyclistDetn 100;
BA_ "GenSigCycleTime" SG_ 692 AEB_LeCyclistDx 100;
BA_ "GenSigCycleTime" SG_ 692 AEB_LeCyclistTyp 100;
BA_ "GenSigCycleTime" SG_ 692 AEB_RiCyclistDetn 100;
BA_ "GenSigCycleTime" SG_ 692 AEB_RiCyclistDx 100;
BA_ "GenSigCycleTime" SG_ 692 AEB_RiCyclistTyp 100;
BA_ "TransparentInitValue" SG_ 692 ACC_FD3_0x2B4 "0 0 0 0 0 0 0 0 0 255 0 0 0 0 255 0 0 0 0 0 0 0 0 0 0 0 0 0 0 0 0 0 0 0 0 0 0 0 0 0 0 0 0 0 0 0 0 0 0 0 0 0 0 0 0 0 0 0 0 0 0 0 0 0 ";
BA_ "GenSigCycleTime" SG_ 692 ACC_FD3_0x2B4 100;
BA_ "GenSigCycleTime" SG_ 778 RCTA_B_TTC 200;
BA_ "GenSigCycleTime" SG_ 778 BSD_LCA_Left_TTC 200;
BA_ "GenSigCycleTime" SG_ 778 BSD_LCA_Right_TTC 200;
BA_ "GenSigCycleTime" SG_ 778 RCW_TTC 200;
BA_ "GenSigCycleTime" SG_ 778 RSDS_LeTgt_01 200;
BA_ "GenSigCycleTime" SG_ 778 RSDS_LeTgt_01_dx 200;
BA_ "GenSigCycleTime" SG_ 778 RSDS_LeTgt_01_dy 200;
BA_ "GenSigCycleTime" SG_ 778 RSDS_LeTgt_02 200;
BA_ "GenSigCycleTime" SG_ 778 RSDS_LeTgt_02_dx 200;
BA_ "GenSigCycleTime" SG_ 778 RSDS_LeTgt_02_dy 200;
BA_ "GenSigCycleTime" SG_ 778 RSDS_RiTgt_01 200;
BA_ "GenSigCycleTime" SG_ 778 RSDS_RiTgt_01_dx 200;
BA_ "GenSigCycleTime" SG_ 778 RSDS_RiTgt_01_dy 200;
BA_ "GenSigCycleTime" SG_ 778 RSDS_RiTgt_02 200;
BA_ "GenSigCycleTime" SG_ 778 RSDS_RiTgt_02_dx 200;
BA_ "GenSigCycleTime" SG_ 778 RSDS_RiTgt_02_dy 200;
BA_ "GenSigCycleTime" SG_ 778 RSDS_MidTgt_01 200;
BA_ "GenSigCycleTime" SG_ 778 RSDS_MidTgt_01_dx 200;
BA_ "GenSigCycleTime" SG_ 778 RSDS_MidTgt_01_dy 200;
BA_ "GenSigCycleTime" SG_ 778 RSDS_MidTgt_02 200;
BA_ "GenSigCycleTime" SG_ 778 RSDS_MidTgt_02_dx 200;
BA_ "GenSigCycleTime" SG_ 778 RSDS_MidTgt_02_dy 200;
BA_ "TransparentInitValue" SG_ 778 RSDS_FD2_0x30A "0 0 0 0 0 0 0 0 0 0 0 0 0 0 0 0 0 0 0 0 0 0 0 0 0 0 0 0 0 0 0 0 0 0 0 0 0 0 0 0 0 0 0 0 0 0 0 0 0 0 0 0 0 0 0 0 0 0 0 0 0 0 0 0 ";
BA_ "GenSigCycleTime" SG_ 778 RSDS_FD2_0x30A 200;
BA_ "GenSigStartValue" SG_ 415 IFC_Line01_Dy 3001;
BA_ "GenSigCycleTime" SG_ 415 IFC_Line01_Dy 50;
BA_ "GenSigStartValue" SG_ 415 IFC_Line01_Curv 31250;
BA_ "GenSigCycleTime" SG_ 415 IFC_Line01_Curv 50;
BA_ "GenSigStartValue" SG_ 415 IFC_Line01_CurvChange 960000;
BA_ "GenSigCycleTime" SG_ 415 IFC_Line01_CurvChange 50;
BA_ "GenSigCycleTime" SG_ 415 IFC_Line01_Type 50;
BA_ "GenSigStartValue" SG_ 415 IFC_Line02_Dy 3001;
BA_ "GenSigCycleTime" SG_ 415 IFC_Line02_Dy 50;
BA_ "GenSigStartValue" SG_ 415 IFC_Line02_Curv 31250;
BA_ "GenSigCycleTime" SG_ 415 IFC_Line02_Curv 50;
BA_ "GenSigStartValue" SG_ 415 IFC_Line02_CurvChange 960000;
BA_ "GenSigCycleTime" SG_ 415 IFC_Line02_CurvChange 50;
BA_ "GenSigCycleTime" SG_ 415 IFC_Line02_Type 50;
BA_ "GenSigStartValue" SG_ 415 IFC_Line03_Dy 3001;
BA_ "GenSigCycleTime" SG_ 415 IFC_Line03_Dy 50;
BA_ "GenSigStartValue" SG_ 415 IFC_Line03_Curv 31250;
BA_ "GenSigCycleTime" SG_ 415 IFC_Line03_Curv 50;
BA_ "GenSigStartValue" SG_ 415 IFC_Line03_CurvChange 960000;
BA_ "GenSigCycleTime" SG_ 415 IFC_Line03_CurvChange 50;
BA_ "GenSigCycleTime" SG_ 415 IFC_Line03_Type 50;
BA_ "GenSigStartValue" SG_ 415 IFC_Line04_Dy 3001;
BA_ "GenSigCycleTime" SG_ 415 IFC_Line04_Dy 50;
BA_ "GenSigStartValue" SG_ 415 IFC_Line04_Curv 31250;
BA_ "GenSigCycleTime" SG_ 415 IFC_Line04_Curv 50;
BA_ "GenSigStartValue" SG_ 415 IFC_Line04_CurvChange 960000;
BA_ "GenSigCycleTime" SG_ 415 IFC_Line04_CurvChange 50;
BA_ "GenSigCycleTime" SG_ 415 IFC_Line04_Type 50;
BA_ "GenSigStartValue" SG_ 415 IFC_Roadedge01_Dy 3001;
BA_ "GenSigCycleTime" SG_ 415 IFC_Roadedge01_Dy 50;
BA_ "GenSigStartValue" SG_ 415 IFC_Roadedge01_Curv 31250;
BA_ "GenSigCycleTime" SG_ 415 IFC_Roadedge01_Curv 50;
BA_ "GenSigStartValue" SG_ 415 IFC_Roadedge01_CurvChange 960000;
BA_ "GenSigCycleTime" SG_ 415 IFC_Roadedge01_CurvChange 50;
BA_ "GenSigCycleTime" SG_ 415 IFC_Roadedge01_Type 50;
BA_ "GenSigStartValue" SG_ 415 IFC_Roadedge02_Dy 3001;
BA_ "GenSigCycleTime" SG_ 415 IFC_Roadedge02_Dy 50;
BA_ "GenSigStartValue" SG_ 415 IFC_Roadedge02_Curv 31250;
BA_ "GenSigCycleTime" SG_ 415 IFC_Roadedge02_Curv 50;
BA_ "GenSigStartValue" SG_ 415 IFC_Roadedge02_CurvChange 960000;
BA_ "GenSigCycleTime" SG_ 415 IFC_Roadedge02_CurvChange 50;
BA_ "GenSigCycleTime" SG_ 415 IFC_Roadedge02_Type 50;
BA_ "TransparentInitValue" SG_ 415 IFC_FD5_0x19F "0 93 207 161 46 166 0 0 0 93 207 161 46 166 0 0 0 93 207 161 46 166 0 0 0 93 207 161 46 166 0 0 0 93 207 161 46 166 0 0 0 93 207 161 46 166 0 0 0 0 0 0 0 0 0 0 0 0 0 0 0 0 0 0 ";
BA_ "GenSigCycleTime" SG_ 415 IFC_FD5_0x19F 50;
BA_ "GenSigCycleTime" SG_ 546 IFC_Line01_DxStart 50;
BA_ "GenSigCycleTime" SG_ 546 IFC_Line01_DxEnd 50;
BA_ "GenSigStartValue" SG_ 546 IFC_Line01_HeadingAngle 201;
BA_ "GenSigCycleTime" SG_ 546 IFC_Line01_HeadingAngle 50;
BA_ "GenSigStartValue" SG_ 546 IFC_Line02_HeadingAngle 201;
BA_ "GenSigCycleTime" SG_ 546 IFC_Line02_HeadingAngle 50;
BA_ "GenSigCycleTime" SG_ 546 IFC_Line02_DxStart 50;
BA_ "GenSigCycleTime" SG_ 546 IFC_Line02_DxEnd 50;
BA_ "GenSigCycleTime" SG_ 546 IFC_Line03_DxStart 50;
BA_ "GenSigCycleTime" SG_ 546 IFC_Line03_DxEnd 50;
BA_ "GenSigStartValue" SG_ 546 IFC_Line03_HeadingAngle 201;
BA_ "GenSigCycleTime" SG_ 546 IFC_Line03_HeadingAngle 50;
BA_ "GenSigCycleTime" SG_ 546 IFC_Line04_DxStart 50;
BA_ "GenSigStartValue" SG_ 546 IFC_Line04_HeadingAngle 201;
BA_ "GenSigCycleTime" SG_ 546 IFC_Line04_HeadingAngle 50;
BA_ "GenSigCycleTime" SG_ 546 IFC_Line04_DxEnd 50;
BA_ "GenSigCycleTime" SG_ 546 IFC_Roadedge01_DxStart 50;
BA_ "GenSigCycleTime" SG_ 546 IFC_Roadedge01_DxEnd 50;
BA_ "GenSigStartValue" SG_ 546 IFC_Roadedge01_HeadingAngle 201;
BA_ "GenSigCycleTime" SG_ 546 IFC_Roadedge01_HeadingAngle 50;
BA_ "GenSigCycleTime" SG_ 546 IFC_Roadedge02_DxStart 50;
BA_ "GenSigCycleTime" SG_ 546 IFC_Roadedge02_DxEnd 50;
BA_ "GenSigStartValue" SG_ 546 IFC_Roadedge02_HeadingAngle 201;
BA_ "GenSigCycleTime" SG_ 546 IFC_Roadedge02_HeadingAngle 50;
BA_ "TransparentInitValue" SG_ 546 IFC_FD6_0x222 "0 0 0 0 1 146 201 0 0 0 0 0 0 0 0 0 0 0 0 201 0 0 201 0 0 0 0 0 0 0 0 0 0 100 128 0 0 0 201 0 0 0 0 0 0 0 0 0 0 0 0 0 0 0 0 0 0 0 0 0 0 0 0 0 ";
BA_ "GenSigCycleTime" SG_ 546 IFC_FD6_0x222 50;
BA_ "GenSigCycleTime" SG_ 705 ChairMemPosnSetSwtFB 100;
BA_ "GenSigCycleTime" SG_ 705 DrvSeatMassgModeSts 100;
BA_ "GenSigCycleTime" SG_ 705 DrvSeatMassgLvlSetSts 100;
BA_ "GenSigCycleTime" SG_ 705 DrvSeatLumSMAdjSts 100;
BA_ "TransparentInitValue" SG_ 705 DSM1_0x2C1 "0 0 0 0 0 0 0 0 ";
BA_ "GenSigCycleTime" SG_ 705 DSM1_0x2C1 100;
BA_ "GenSigSendType" SG_ 491 DrvSeatMassgLvlSet 2;
BA_ "GenSigSendType" SG_ 491 DrvSeatMassgModSet 2;
BA_ "GenSigStartValue" SG_ 491 DrvBehvTestSetUp 1;
BA_ "GenSigSendType" SG_ 491 DrvBehvTestSetUp 2;
BA_ "GenSigStartValue" SG_ 491 GazeAreaIntracSetUp 1;
BA_ "GenSigSendType" SG_ 491 GazeAreaIntracSetUp 2;
BA_ "TransparentInitValue" SG_ 491 HUT39_0x1EB "0 0 1 1 0 0 0 0 ";
BA_ "GenSigSendType" SG_ 491 HUT39_0x1EB 2;
BA_ "GenSigCycleTime" SG_ 694 DrvSeatSupportPosnSwt 100;
BA_ "TransparentInitValue" SG_ 694 HUT26_0x2B6 "0 0 0 0 0 0 0 0 ";
BA_ "GenSigCycleTime" SG_ 694 HUT26_0x2B6 100;
BA_ "GenSigCycleTime" SG_ 963 GMCU_MotorSerNumber_RM 1000;
BA_ "GenSigStartValue" SG_ 963 GMCU_InvActTemp_RM 65;
BA_ "GenSigCycleTime" SG_ 963 GMCU_InvActTemp_RM 1000;
BA_ "GenSigStartValue" SG_ 963 GMCU_ActSpd_RM 20000;
BA_ "GenSigCycleTime" SG_ 963 GMCU_ActSpd_RM 1000;
BA_ "GenSigStartValue" SG_ 963 GMCU_ActTrq_RM 20000;
BA_ "GenSigCycleTime" SG_ 963 GMCU_ActTrq_RM 1000;
BA_ "GenSigStartValue" SG_ 967 GMCU_ActHvDcCurr_RM 1000;
BA_ "GenSigCycleTime" SG_ 967 GMCU_ActHvDcCurr_RM 1000;
BA_ "GenSigCycleTime" SG_ 967 GMCU_ActHvDcVolt_RM 1000;
BA_ "GenSigStartValue" SG_ 967 GMCU_ActTemp_RM 65;
BA_ "GenSigCycleTime" SG_ 967 GMCU_ActTemp_RM 1000;
BA_ "GenSigCycleTime" SG_ 967 GMCU_Tempwarning_RM 1000;
BA_ "GenSigCycleTime" SG_ 967 GMCU_InvTempwarning_RM 1000;
BA_ "GenSigStartValue" SG_ 967 GMCU_OperMode_RM 4;
BA_ "GenSigCycleTime" SG_ 967 GMCU_OperMode_RM 1000;
BA_ "GenSigCycleTime" SG_ 763 MbrMonrEnaSts 100;
BA_ "TransparentInitValue" SG_ 763 VMDR1_0x2FB "0 0 0 0 0 0 0 0 ";
BA_ "GenSigCycleTime" SG_ 763 VMDR1_0x2FB 100;
BA_ "GenSigSendType" SG_ 731 ALCMSwtSts 2;
BA_ "TransparentInitValue" SG_ 731 ALCM1_0x2DB "0 0 0 0 0 0 0 0 ";
BA_ "GenSigSendType" SG_ 731 ALCM1_0x2DB 2;
BA_ "GenSigSendType" SG_ 1122 SyncRequestMessageId 2;
BA_ "GenSigSendType" SG_ 1122 SyncRequstReseverData 2;
BA_ "TransparentInitValue" SG_ 1122 HUT_Sync_Req_0x462 "0 0 0 0 0 0 0 0 0 0 0 0 0 0 0 0 ";
BA_ "GenSigSendType" SG_ 1122 HUT_Sync_Req_0x462 2;
VAL_ 482 HCU_PhoneChrgnModeResp 0 "inactive" 1 "active" ;
VAL_ 482 HCU_PhoneChrgnReqResp 0 "inactive" 1 "active" ;
VAL_ 482 HCU_HUTChrgnModeResp 0 "inactive" 1 "active" ;
VAL_ 482 HCU_HUTChrgnReqResp 0 "inactive" 1 "active" ;
VAL_ 482 HCU_TboxEngStrtReq 0 "NO Request" 1 "Request" ;
VAL_ 482 HCU_TotalScore 0 "Valid value" 5 "Valid value" 6 "Reserved" 7 "Reserved" ;
VAL_ 482 HCU_IntelBattTempMagResp 0 "inactive" 1 "active" ;
VAL_ 482 HCU_RemtVehStartReq 0 "No Request" 1 "Request" ;
VAL_ 909 HCU_PowertrainSts_RM 1 "ON" 2 "OFF" 3 "Other Mode" ;
VAL_ 909 HCU_ChargSts_RM 1 "Parking charging" 2 "Driving charging" 3 "Uncharged" 4 "Charge end" 5 "Reserved" 7 "Reserved" ;
VAL_ 909 HCU_PTDrvMod_RM 1 "EV Mode" 2 "Hybrid Mode" 3 "Fuel oil Mode" ;
VAL_ 909 HCU_Powerflag_RM 0 "No power" 1 "Power" ;
VAL_ 909 HCU_AccelPedalPosn_Diag_RM 0 "Vaild value" 100 "Vaild value" ;
VAL_ 909 HCU_BrkPedalSts_RM 0 "0%" 101 "Brake pedal pressed" ;
VAL_ 909 HCU_DrvPower_RM 0 "No Power" 1 "Power" ;
VAL_ 909 HCU_BrkPower_RM 0 "No Power" 1 "Power" ;
VAL_ 909 HCU_GearSts_RM 0 "N" 1 "Valid value" 12 "Valid value" 13 "R" 14 "D" 15 "P" ;
VAL_ 241 CheckSum_BMS4 0 "Valid value" 255 "Valid value" ;
VAL_ 241 BMS_PowerDownCmplt 0 "Not complete" 1 "Complete" ;
VAL_ 241 BMS_BattPoweErr 0 "No Error" 1 "TM power unavailable" 2 "P2M power unavailable" 3 "OBC power unavailable" ;
VAL_ 241 BMS_ErrCategory 0 "No Error" 1 "Warning" 2 "Derating" 3 "Instrument Displayï¼ˆYellowï¼‰" 4 "Range Limitedï¼ˆYellowï¼‰" 5 "Pre-charge Lockedï¼ˆRedï¼‰" 6 "Delayed Openï¼ˆRedï¼‰" 7 "Emergency Open(Red)" ;
VAL_ 241 BMS_PackCurr 0 "Valid value" 10000 "Valid value" 10001 "Reserved" 16382 "Reserved" 16383 "Invalid" ;
VAL_ 241 BMS_PackVolt 0 "Valid value" 245 "Valid value" 246 "Reserved" 254 "Reserved" 255 "Invalid" ;
VAL_ 241 RollingCounter_BMS4 0 "Valid value" 14 "Valid value" 15 "Invalid value" ;
VAL_ 645 BMS_BattHeatRunaway 0 "inactive" 1 "running thermalrunaway" 2 "parking thermalrunaway" 3 "reserved" ;
VAL_ 708 BMS_BattSOC 0 "Valid values" 1000 "Valid values" 1001 "Reserved" 1022 "Reserved" 1023 "Invalid values" ;
VAL_ 708 BMS_BattSOCLimResp 0 "100%" 1 "50%" 2 "60%" 3 "70%" 4 "80%" 5 "90%" 6 "Invalid" 7 "reserved" ;
VAL_ 850 BMS_RemtPreHeatSts 0 "Default" 1 "Remote Pre-Heat Successfully set but not start" 2 "start heating" 3 "Fail to start heating" 4 "Remote Pre-Heating is complete" 5 "Reserved" 7 "Reserved" ;
VAL_ 850 BMS_BattKeepTempSts 0 "Off" 1 "On" ;
VAL_ 850 BMS_IntelEngIdlChrgnSts 0 "Default" 1 "ON" 2 "Off" 3 "Reserved" ;
VAL_ 959 BMS_ChrgDurationTime 0 "Valid value" 1022 "Valid value" 1023 "Invalid" ;
VAL_ 976 BMS_BattTempMax 0 "Valid value" 165 "Valid value" 166 "Reserved" 254 "Reserved" 255 "invalid" ;
VAL_ 976 BMS_BattTempMin 0 "Valid value" 165 "Valid value" 166 "Reserved" 254 "Reserved" 255 "invalid" ;
VAL_ 1009 BMS_CellUnderVolt 0 "Normal" 1 "warning" ;
VAL_ 1009 BMS_CellOverVolt 0 "Normal" 1 "warning" ;
VAL_ 1009 BMS_CellDeltaVolt 0 "Normal" 1 "warning" ;
VAL_ 1009 BMS_BattUnderVolt 0 "Normal" 1 "warning" ;
VAL_ 1009 BMS_BattOverVolt 0 "Normal" 1 "warning" ;
VAL_ 1009 BMS_BattUnderTemp 0 "Normal" 1 "warning" ;
VAL_ 1009 BMS_SOC_Plaucheck 0 "Normal" 1 "warningï¼ˆï¼ž10%ï¼‰" ;
VAL_ 1009 BMS_DeltaTemp 0 "Normal" 1 "warning" ;
VAL_ 1009 BMS_CANComErr 0 "Normal" 1 "warning" ;
VAL_ 1009 BMS_SOCLowWarn 0 "Normal" 1 "Need to charge" ;
VAL_ 1009 BMS_BattSOCLow 0 "Normal" 1 "warning" ;
VAL_ 1009 BMS_BattSOCTooLow 0 "Normal" 1 "warning" ;
VAL_ 1009 BMS_BattSOCHigh 0 "Normal" 1 "warning" ;
VAL_ 1009 BMS_ChrgnCurrLager 0 "Normal" 1 "warning" ;
VAL_ 1009 BMS_DischrgnCurrLager 0 "Normal" 1 "warning" ;
VAL_ 1009 BMS_ModuleMismatchWarn 0 "Normal" 1 "warning" ;
VAL_ 1009 BMS_cohrnc 0 "Normal" 1 "warning" ;
VAL_ 1009 BMS_moduleNumber 0 "Module1~Module9" 8 "Module1~Module9" ;
VAL_ 1009 BMS_NumModuleTempSnsr 0 "sensor1~sensor18" 17 "sensor1~sensor18" 18 "Reserved" 31 "Reserved" ;
VAL_ 1009 BMS_NumCell 0 "Cell1~Cell108" 107 "Cell1~Cell108" 108 "Reserved" 255 "Reserved" ;
VAL_ 1010 BMS_CellVoltMin 0 "Valid value" 65535 "Valid value" ;
VAL_ 1010 BMS_NumberCellVoltMin 0 "Cell1~Cell108" 107 "Cell1~Cell108" 108 "Reserved" 255 "Reserved" ;
VAL_ 1010 BMS_CellMaxVolt 0 "Valid value" 65535 "Valid value" ;
VAL_ 1010 BMS_NumberCellMaxVolt 0 "Cell1~Cell108" 107 "Cell1~Cell108" 108 "Reserved" 255 "Reserved" ;
VAL_ 1010 BMS_CellBalanceSts 0 "not active" 1 "active normally" 2 "reserved" 3 "reserved" ;
VAL_ 1010 BMS_RlyCounterSts 0 "Normal" 1 "positive relay OUL(over use of life)" 2 "negative relay OUL" 3 "Precharge relay OUL" ;
VAL_ 1010 BMS_SOH_R 0 "Valid value" 1000 "Valid value" 1001 "Reserved" 1022 "Reserved" 1023 "Invalid" ;
VAL_ 1011 BMS_ModuleMinTemp 0 "Valid Value" 130 "Valid Value" 131 "Reserved" 254 "Reserved" 255 "Invalid" ;
VAL_ 1011 BMS_ModuleNumCellMinTemp 0 "Module1~Module9" 8 "Module1~Module9" ;
VAL_ 1011 BMS_ModuleNumCellMaxTemp 0 "Module1~Module9" 8 "Module1~Module9" ;
VAL_ 1011 BMS_ModuleMaxTemp 0 "Valid Value" 130 "Valid Value" 131 "Reserved" 254 "Reserved" 255 "Invalid" ;
VAL_ 1011 BMS_NumCellMinTemp 0 "Module1~Module18" 17 "Module1~Module18" 18 "Reserved" 31 "Reserved" ;
VAL_ 1011 BMS_NumCellMaxTemp 0 "Module1~Module18" 17 "Module1~Module18" 18 "Reserved" 31 "Reserved" ;
VAL_ 1011 BMS_BattOverTempWarn 0 "Normal" 1 "warning 1 (55~65ÂºC)" 2 "warning 2 (â‰¥65ÂºC)" 3 "Reserved" ;
VAL_ 1011 BMS_ModuleNumberCellMinVolt 0 "Number1~number9" 8 "Number1~number9" ;
VAL_ 1011 BMS_ModuleNumberCellMaxVolt 0 "Number1~number9" 8 "Number1~number9" ;
VAL_ 790 OBC_ModSts 0 "Discharging" 1 "Init" 2 "Standby" 3 "Heating" 4 "Charging Normal" 5 "Reserved" 7 "Reserved" 8 "Fault" 9 "Reduced Power" 10 "Reserved" 11 "Sleep (Shutdown)" 12 "OFF" 13 "Reserved" 15 "Reserved" ;
VAL_ 791 OBC_ConnectSts 0 "Not connected" 1 "Connected" 2 "Error" 3 "Reserved" ;
VAL_ 96 HCU_AccelPedalPosn_Diag 0 "Vaild value" 255 "Vaild value" ;
VAL_ 96 HCU_AccelPedalPosn_DiagValid 0 "Invaild" 1 "Vaild" ;
VAL_ 96 TMCU_ActRotSpd 0 "Valid value" 32765 "Valid value" 32766 "Reserved" 65533 "Reserved" 65534 "Init" 65535 "invalid" ;
VAL_ 96 HCU_PowertrainSts 0 "Sleep" 1 "Initialize Mode" 2 "power up" 3 "power down" 4 "Home" 5 "run" 6 "Charging" 7 "Cellphone AC" 8 "Limphome" 9 "Emergency Mode" 10 "V2L" 11 "Prepare Sleep" 12 "ready" 13 "LV Charging" 14 "LT Charging" 15 "IL heating" 16 "Thermal run away" 17 "End of line" 18 "BattTempKeep" 19 "Reserved" 31 "Reserved" ;
VAL_ 96 HCU_RaceLaunchSts 0 "Not active" 1 "Active" 2 "Timeout protection" 3 "Super race launch active" 4 "Super race launch is not available due to battery available power low, normal race activated" 5 "Super race launch is not available due to transmission temperature high, normal race activated" 6 "The maximum times of super race launch is reached, normal race activatedivated" 7 "Reserved" ;
VAL_ 96 HCU_RaceLaunchAvail 0 "Race Launch is available" 1 "Race Launch is not available due to ESP is not OFF" 2 "Race Launch is not available due to temporary hybrid system limitations" 3 "Race Launch is not available due to battery SOCtemperature low" ;
VAL_ 330 HCU_DrvMod 0 "AutoNormal Mode started" 1 "EV Mode started" 2 "Save Mode started" 3 "SPORT Mode started" 4 "AWD Normal Mode started" 5 "Snow Mode started" 6 "Muddy Mode started" 7 "Sand Mode started" 8 "ECO" 9 "SPORT Plus Mode started" 10 "Reserved" 15 "Reserved" ;
VAL_ 330 HCUImmoAuthRes 0 "Idle" 1 "Passed" 2 "Failed" 3 "Invalid value" ;
VAL_ 330 HCU_EVLmpSts 0 "Not active" 1 "Active" ;
VAL_ 330 HCU_ECODrvHabit_Indcn 0 "Valid values" 200 "Valid values" 201 "Reversed" 255 "Reversed" ;
VAL_ 330 HCU_TotDrvReqPower 0 "Valid values-Power percentage Valueï¼ˆ-100-0-100ï¼‰" 200 "Valid values-Power percentage Valueï¼ˆ-100-0-100ï¼‰" 201 "invalid values" 255 "invalid values" ;
VAL_ 330 HCU_AvailPower_TM 0 "Valid values" 100 "Valid values" 101 "invalid values" 255 "invalid values" ;
VAL_ 584 CheckSum_HCU_PT7 0 "Valid values" 255 "Valid values" ;
VAL_ 584 HCU_HybSysErr_1 0 "Not indicate" 1 "Indicate" ;
VAL_ 584 HCU_HybSysErr_2 0 "Not indicate" 1 "Indicate" ;
VAL_ 584 HCU_HybSysErr_3 0 "Not indicate" 1 "Indicate" ;
VAL_ 584 HCU_HybSysErr_4 0 "Not indicate" 1 "Indicate" ;
VAL_ 584 HCU_HybSysErr_5 0 "Not indicate" 1 "Indicate" ;
VAL_ 584 HCU_HybSysErr_6 0 "Not indicate" 1 "Indicate" ;
VAL_ 584 HCU_HybSysErr_7 0 "Not indicate" 1 "Indicate" ;
VAL_ 584 HCU_12VSysErrLmpSts 0 "OFF" 1 "ON" ;
VAL_ 584 HCU_HybSysErrLmpSts 0 "OFF" 1 "Yellow Light ON" 2 "Red Light ON" 3 "Reserved" ;
VAL_ 584 HCU_PowerRedWarnLmpCmd 0 "Lamp off" 1 "Lamp on" ;
VAL_ 584 HCU_12VSysErr_1 0 "Not indicate" 1 "Indicate" ;
VAL_ 584 HCU_12VSysErr_2 0 "Not indicate" 1 "Indicate" ;
VAL_ 584 HCU_RdyLmpSts 0 "OFF" 1 "ON" ;
VAL_ 584 HCU_ModSwtFail 0 "Default" 1 "EV not available due to low battery charge" 2 "EV not available due to temporary hybrid system limitations" 3 "SAVE not available due to temporary hybrid system limitations" 4 "AWD not available due to temporary hybrid system limitations" 5 "SPORT not available due to temporary hybrid system limitations" 6 "Manual gear change ,drive mode goes SPORT" 7 "Manual gear change,only SPORT available" 8 "EV mode available" 9 "Snow not available due to temporary hybrid system limitations" 10 "Muddy not available due to temporary hybrid system limitations" 11 "Sand not available due to temporary hybrid system limitations" 12 "SPORT Plus Mode not available due to temporary hybrid system limitations" 13 "EV mode is not available due to battery available power low" 14 "EV not available due to engine needs to start" 15 "Reserved" ;
VAL_ 584 HCU_EnrgFlowInd 0 "Mode 0 Vehicle standstill" 1 "Engine running and BSG is a conventional generator" 2 "Engine Auto-stopped" 3 "Boost" 4 "Energy Recovery" 5 "E-Creep" 6 "pure engine drive" 7 "Reserved" 31 "Reserved" ;
VAL_ 584 HCU_OPDSts 0 "Not active" 1 "Active" 2 "Abnormal quit" 3 "Cannot active" 4 "Have no OPD function" 5 "Reserved" 7 "Reserved" ;
VAL_ 584 HCU_OPDLmpSts 0 "Off" 1 "On" ;
VAL_ 584 RollingCounter_HCU_PT7 0 "Valid value" 14 "Valid value" 15 "Invalid value" ;
VAL_ 448 HCU_ChrgSysLmpSts 0 "OFF" 1 "Green Light ON" 2 "Red Light ON" 3 "Yellow Light with slanting line" 4 "Red Light with slanting line" 5 "Reserved" 7 "Reserved" ;
VAL_ 448 HCU_ChrgSysErr_1 0 "Not indicate" 1 "Indicate" ;
VAL_ 448 HCU_ChrgSysErr_2 0 "Not indicate" 1 "Indicate" ;
VAL_ 448 HCU_ChrgSysErr_3 0 "Not indicate" 1 "Indicate" ;
VAL_ 448 HCU_ChrgSysErr_4 0 "Not indicate" 1 "Indicate" ;
VAL_ 448 HCU_ChrgSysErr_5 0 "Not indicate" 1 "Indicate" ;
VAL_ 448 HCU_ChrgSysErr_6 0 "Not indicate" 1 "Indicate" ;
VAL_ 448 HCU_ChrgSysErr_7 0 "Not indicate" 1 "Indicate" ;
VAL_ 448 HCU_ChrgSysErr_8 0 "Not indicate" 1 "Indicate" ;
VAL_ 762 CheckSum_HCU_PT4 0 "Valid values" 255 "Valid values" ;
VAL_ 762 HCU_BattPowerRedWarn 0 "Inactive" 1 "Battery temperature is low,power may decrease" 2 "Battery temperature is high,power may decrease" 3 "Reserved" ;
VAL_ 762 HCU_EnerSavePowerMod 0 "No action" 1 "Close blower" 2 "Close seat heat" 3 "Close both blower and seat heat" ;
VAL_ 762 HCU_SOCLow_Indcn 0 "Not active" 1 "Active" ;
VAL_ 762 HCU_RemoveChrgLine_Indcn 0 "Not active" 1 "Active" ;
VAL_ 762 HCU_WadeModeSetSts 0 "OFF" 1 "ON" ;
VAL_ 762 HCU_Shift_P_Indcn 0 "Not active" 1 "Active" ;
VAL_ 762 HCU_ConnectChrgLine_Indcn 0 "Not active" 1 "Active" ;
VAL_ 762 HCU_EgyRecFB 0 "Standard" 1 "Enhanced" 2 "Low" 3 "Not Available" ;
VAL_ 762 HCU_ACStsReq 0 "Disable" 1 "Derating" 2 "Normal" 3 "Invalid" ;
VAL_ 762 HCU_RefuReq 0 "No request" 1 "Refueling request" 2 "When vehicle is ready inhibit refuel" 3 "When engine is run inhibit refuel" 4 "When charger is connected inhibit refuel" 5 "Reserved" 7 "Reserved" ;
VAL_ 762 HCU_OilTankCoverSts 0 "Closed" 1 "Open" ;
VAL_ 762 HCU_InhbChrgInfo 0 "No warning" 1 "When vehicle is refueling inhibit charge" ;
VAL_ 762 OPDParkWarnReq 0 "No Request" 1 "Request" ;
VAL_ 762 HCU_OPDFail 0 "Normal (Default)" 1 "OPD function not available due to temporary hybrid system limitations" 2 "OPD function not available due to Snow mode" 3 "Reserved" ;
VAL_ 762 CarWashMode_StsDisp 0 "No Display" 1 "Speed too high,TransportCar Wash Mode is not available" 2 "12V battery SOC too low,TransportCar Wash Mode is not available" 3 "Reserved" 7 "Reserved" ;
VAL_ 762 CarWashMode_Sts 0 "Normal Mode" 1 "Car Wash Mode" ;
VAL_ 762 HCU_RefuBtnSts 0 "No pressed" 1 "Pressed" ;
VAL_ 762 RollingCounter_HCU_PT4 0 "Valid value" 14 "Valid value" 15 "Invalid value" ;
VAL_ 513 Checksum_HCU_HP5 0 "Valid values" 255 "Valid values" ;
VAL_ 513 HCU_EnrgFlowInd_DHT 0 "Mode 1 Vehicle standstill, engine not start" 1 "mode 2 Vehicle standstill,engine start" 2 "mode 3 engine idling charging" 3 "mode 4 Pure electricity drive (T-Motor)" 4 "mode 5 Engine direct drive (battery not working)" 5 "mode 6 Series drive (battery not working) (T-Motor)" 6 "mode 7 Engine direct drive (battery discharging)" 7 "mode 8 Series drive (battery discharging)" 8 "mode 9 Engine direct drive (battery charging)" 9 "mode 10 Series drive (battery charging)" 10 "mode 11 Energy recovery (T-Motor)" 11 "mode 12 T-Motor Energy recovery (T-Motor) + Battery charging" 12 "mode 13 Plug-in-warming" 13 "mode 14 Plug-in-charging&warming" 14 "mode 15AC charging" 15 "mode 16 DC charging" 16 "Reserved" 63 "Reserved" ;
VAL_ 513 HCU_PrsBrkWarn 0 "No warning" 1 "Press brake and Unlock-button to shift" 2 "Press Unlock-button to shift" 3 "Press brake to shift" ;
VAL_ 513 DrvModDisp_0x201 0 "P" 1 "R" 2 "N" 3 "D" 4 "M" 5 "Reserved" 7 "Reserved" ;
VAL_ 513 DrvModDispSts_0x201 0 "BlankNo Display" 1 "On" 2 "Flashing" 3 "Reserved(treat as BlankNo Display)" ;
VAL_ 513 DrvGearDisp 0 "Neutral" 1 "E Gear" 2 "L Gear" 3 "M Gear" 4 "H Gear" 5 "S Gear" 6 "X Gear" 7 "Reserved" ;
VAL_ 513 DrvGearDispSts_0x201 0 "Blank  No display" 1 "On" 2 "Flashing" 3 "Reserved (treat as BlankNo display)" ;
VAL_ 513 HCU_ShftNotAlwd_Warn 0 "No warning" 1 "Vehicle speed too high, shift not allowed" 2 "Engage P not allowed due to high vehicle speed" 3 "reserved" ;
VAL_ 513 DrvFaiMsg_0x201 0 "No Message" 1 "Transmission Malfunction" 2 "Transmission P engagement fault" 3 "Transmission P disengagement fault" 4 "Please press the brake pedal untill the P-gear reference is completed" 5 "Reference is not completed,please shift gears after reference is completed" 6 "P-gear reference completed, please released the brake pedal" 7 "Reserved" 14 "Reserved" 15 "Transmission limit function" ;
VAL_ 513 RollingCounter_HCU_HP5 0 "Valid value" 14 "Valid value" 15 "Invalid value" ;
VAL_ 288 IB_Warn 0 "Warning lamp off" 1 "Warning lamp on" ;
VAL_ 200 ESP_HMI_WarningOn 0 "No warning lamp" 1 "Yellow Lamp" 2 "Red Lamp" 3 "reserved" ;
VAL_ 216 TgtRcprtnTrqSts 0 "Not Initialized" 1 "Normal" 2 "Faulty" 3 "Reserved" ;
VAL_ 957 DCDC_Tempwarning_RM 0 "No warning" 1 "warning" ;
VAL_ 957 DCDC_ActSts_RM 0 "Initial value" 1 "On" 2 "Off" 3 "Reserved" ;
VAL_ 957 DCDC_FailStswarning_RM 0 "No warning" 1 "warning" ;
VAL_ 969 TMCU_Amount_RM 0 "Reserved" 1 "Valid value" 253 "Valid value" 254 "Invalid value" 255 "Invalid value" ;
VAL_ 969 TMCU_MotorSerNumber_RM 0 "Reserved" 1 "Valid value" 253 "Valid value" 254 "Invalid value" 255 "Invalid value" ;
VAL_ 969 TMCU_InvActTemp_RM 0 "Valid value" 250 "Valid value" 251 "Reserved" 253 "Reserved" 254 "Error" 255 "Invalid value" ;
VAL_ 969 TMCU_ActSpd_RM 0 "Valid value" 65531 "Valid value" 65532 "Reserved" 65533 "Reserved" 65534 "Error" 65535 "Invalid value" ;
VAL_ 969 TMCU_ActTrq_RM 0 "Valid value" 65531 "Valid value" 65532 "Reserved" 65533 "Reserved" 65534 "Error" 65535 "Invalid value" ;
VAL_ 948 TMCU_ActHvDcCurr_RM 0 "Valid value" 20000 "Valid value" 20001 "Reserved" 65533 "Reserved" 65534 "Error" 65535 "Invalid value" ;
VAL_ 948 TMCU_ActHvDcVolt_RM 0 "Valid value" 60000 "Valid value" 60001 "Reserved" 65533 "Reserved" 65534 "Error" 65535 "Invalid value" ;
VAL_ 948 TMCU_ActTemp_RM 0 "Valid value" 250 "Valid value" 251 "Reserved" 253 "Reserved" 254 "Error" 255 "Invalid value" ;
VAL_ 948 TMCU_Tempwarning_RM 0 "Normal" 1 "Warning" ;
VAL_ 948 TMCU_InvTempwarning_RM 0 "Normal" 1 "Warning" ;
VAL_ 948 TMCU_OperMode_RM 0 "Reserved" 1 "Consume power" 2 "Generate electricity" 3 "Shut down" 4 "Ready" 5 "Reserved" 253 "Reserved" 254 "Error" 255 "Invalid value" ;
VAL_ 977 BMS_BattModuleTe_11 0 "Valid value" 165 "Valid value" 166 "Reserved" 254 "Reserved" 255 "invalid" ;
VAL_ 977 BMS_BattModuleTe_12 0 "Valid value" 165 "Valid value" 166 "Reserved" 254 "Reserved" 255 "invalid" ;
VAL_ 977 BMS_BattModuleTe_21 0 "Valid value" 165 "Valid value" 166 "Reserved" 254 "Reserved" 255 "invalid" ;
VAL_ 977 BMS_BattModuleTe_22 0 "Valid value" 165 "Valid value" 166 "Reserved" 254 "Reserved" 255 "invalid" ;
VAL_ 977 BMS_BattModuleTe_31 0 "Valid value" 165 "Valid value" 166 "Reserved" 254 "Reserved" 255 "invalid" ;
VAL_ 977 BMS_BattModuleTe_32 0 "Valid value" 165 "Valid value" 166 "Reserved" 254 "Reserved" 255 "invalid" ;
VAL_ 977 BMS_BattModuleTe_41 0 "Valid value" 165 "Valid value" 166 "Reserved" 254 "Reserved" 255 "invalid" ;
VAL_ 977 BMS_BattModuleTe_42 0 "Valid value" 165 "Valid value" 166 "Reserved" 254 "Reserved" 255 "invalid" ;
VAL_ 977 BMS_BattModuleTe_51 0 "Valid value" 165 "Valid value" 166 "Reserved" 254 "Reserved" 255 "invalid" ;
VAL_ 977 BMS_BattModuleTe_52 0 "Valid value" 165 "Valid value" 166 "Reserved" 254 "Reserved" 255 "invalid" ;
VAL_ 977 BMS_BattModuleTe_61 0 "Valid value" 165 "Valid value" 166 "Reserved" 254 "Reserved" 255 "invalid" ;
VAL_ 977 BMS_BattModuleTe_62 0 "Valid value" 165 "Valid value" 166 "Reserved" 254 "Reserved" 255 "invalid" ;
VAL_ 977 BMS_BattModuleTe_71 0 "Valid value" 165 "Valid value" 166 "Reserved" 254 "Reserved" 255 "invalid" ;
VAL_ 977 BMS_BattModuleTe_72 0 "Valid value" 165 "Valid value" 166 "Reserved" 254 "Reserved" 255 "invalid" ;
VAL_ 977 BMS_BattModuleTe_81 0 "Valid value" 165 "Valid value" 166 "Reserved" 254 "Reserved" 255 "invalid" ;
VAL_ 977 BMS_BattModuleTe_82 0 "Valid value" 165 "Valid value" 166 "Reserved" 254 "Reserved" 255 "invalid" ;
VAL_ 977 BMS_SingleCellVolt_1 0 "Valid value" 60000 "Valid value" 60001 "Reserved" 65535 "Reserved" ;
VAL_ 977 BMS_SingleCellVolt_2 0 "Valid value" 60000 "Valid value" 60001 "Reserved" 65535 "Reserved" ;
VAL_ 977 BMS_SingleCellVolt_3 0 "Valid value" 60000 "Valid value" 60001 "Reserved" 65535 "Reserved" ;
VAL_ 977 BMS_SingleCellVolt_4 0 "Valid value" 60000 "Valid value" 60001 "Reserved" 65535 "Reserved" ;
VAL_ 977 BMS_SingleCellVolt_5 0 "Valid value" 60000 "Valid value" 60001 "Reserved" 65535 "Reserved" ;
VAL_ 977 BMS_SingleCellVolt_6 0 "Valid value" 60000 "Valid value" 60001 "Reserved" 65535 "Reserved" ;
VAL_ 977 BMS_SingleCellVolt_7 0 "Valid value" 60000 "Valid value" 60001 "Reserved" 65535 "Reserved" ;
VAL_ 977 BMS_SingleCellVolt_8 0 "Valid value" 60000 "Valid value" 60001 "Reserved" 65535 "Reserved" ;
VAL_ 977 BMS_SingleCellVolt_9 0 "Valid value" 60000 "Valid value" 60001 "Reserved" 65535 "Reserved" ;
VAL_ 977 BMS_SingleCellVolt_10 0 "Valid value" 60000 "Valid value" 60001 "Reserved" 65535 "Reserved" ;
VAL_ 977 BMS_SingleCellVolt_11 0 "Valid value" 60000 "Valid value" 60001 "Reserved" 65535 "Reserved" ;
VAL_ 977 BMS_SingleCellVolt_12 0 "Valid value" 60000 "Valid value" 60001 "Reserved" 65535 "Reserved" ;
VAL_ 978 BMS_SingleCellVolt_13 0 "Valid value" 60000 "Valid value" 60001 "Reserved" 65535 "Reserved" ;
VAL_ 978 BMS_SingleCellVolt_14 0 "Valid value" 60000 "Valid value" 60001 "Reserved" 65535 "Reserved" ;
VAL_ 978 BMS_SingleCellVolt_15 0 "Valid value" 60000 "Valid value" 60001 "Reserved" 65535 "Reserved" ;
VAL_ 978 BMS_SingleCellVolt_16 0 "Valid value" 60000 "Valid value" 60001 "Reserved" 65535 "Reserved" ;
VAL_ 978 BMS_SingleCellVolt_17 0 "Valid value" 60000 "Valid value" 60001 "Reserved" 65535 "Reserved" ;
VAL_ 978 BMS_SingleCellVolt_18 0 "Valid value" 60000 "Valid value" 60001 "Reserved" 65535 "Reserved" ;
VAL_ 978 BMS_SingleCellVolt_19 0 "Valid value" 60000 "Valid value" 60001 "Reserved" 65535 "Reserved" ;
VAL_ 978 BMS_SingleCellVolt_20 0 "Valid value" 60000 "Valid value" 60001 "Reserved" 65535 "Reserved" ;
VAL_ 978 BMS_SingleCellVolt_21 0 "Valid value" 60000 "Valid value" 60001 "Reserved" 65535 "Reserved" ;
VAL_ 978 BMS_SingleCellVolt_22 0 "Valid value" 60000 "Valid value" 60001 "Reserved" 65535 "Reserved" ;
VAL_ 978 BMS_SingleCellVolt_23 0 "Valid value" 60000 "Valid value" 60001 "Reserved" 65535 "Reserved" ;
VAL_ 978 BMS_SingleCellVolt_24 0 "Valid value" 60000 "Valid value" 60001 "Reserved" 65535 "Reserved" ;
VAL_ 978 BMS_SingleCellVolt_25 0 "Valid value" 60000 "Valid value" 60001 "Reserved" 65535 "Reserved" ;
VAL_ 978 BMS_SingleCellVolt_26 0 "Valid value" 60000 "Valid value" 60001 "Reserved" 65535 "Reserved" ;
VAL_ 978 BMS_SingleCellVolt_27 0 "Valid value" 60000 "Valid value" 60001 "Reserved" 65535 "Reserved" ;
VAL_ 978 BMS_SingleCellVolt_28 0 "Valid value" 60000 "Valid value" 60001 "Reserved" 65535 "Reserved" ;
VAL_ 978 BMS_SingleCellVolt_29 0 "Valid value" 60000 "Valid value" 60001 "Reserved" 65535 "Reserved" ;
VAL_ 978 BMS_SingleCellVolt_30 0 "Valid value" 60000 "Valid value" 60001 "Reserved" 65535 "Reserved" ;
VAL_ 978 BMS_SingleCellVolt_31 0 "Valid value" 60000 "Valid value" 60001 "Reserved" 65535 "Reserved" ;
VAL_ 978 BMS_SingleCellVolt_32 0 "Valid value" 60000 "Valid value" 60001 "Reserved" 65535 "Reserved" ;
VAL_ 978 BMS_SingleCellVolt_33 0 "Valid value" 60000 "Valid value" 60001 "Reserved" 65535 "Reserved" ;
VAL_ 978 BMS_SingleCellVolt_34 0 "Valid value" 60000 "Valid value" 60001 "Reserved" 65535 "Reserved" ;
VAL_ 978 BMS_SingleCellVolt_35 0 "Valid value" 60000 "Valid value" 60001 "Reserved" 65535 "Reserved" ;
VAL_ 978 BMS_SingleCellVolt_36 0 "Valid value" 60000 "Valid value" 60001 "Reserved" 65535 "Reserved" ;
VAL_ 978 BMS_SingleCellVolt_37 0 "Valid value" 60000 "Valid value" 60001 "Reserved" 65535 "Reserved" ;
VAL_ 978 BMS_SingleCellVolt_38 0 "Valid value" 60000 "Valid value" 60001 "Reserved" 65535 "Reserved" ;
VAL_ 978 BMS_SingleCellVolt_39 0 "Valid value" 60000 "Valid value" 60001 "Reserved" 65535 "Reserved" ;
VAL_ 978 BMS_SingleCellVolt_40 0 "Valid value" 60000 "Valid value" 60001 "Reserved" 65535 "Reserved" ;
VAL_ 979 BMS_SingleCellVolt_41 0 "Valid value" 60000 "Valid value" 60001 "Reserved" 65535 "Reserved" ;
VAL_ 979 BMS_SingleCellVolt_42 0 "Valid value" 60000 "Valid value" 60001 "Reserved" 65535 "Reserved" ;
VAL_ 979 BMS_SingleCellVolt_43 0 "Valid value" 60000 "Valid value" 60001 "Reserved" 65535 "Reserved" ;
VAL_ 979 BMS_SingleCellVolt_44 0 "Valid value" 60000 "Valid value" 60001 "Reserved" 65535 "Reserved" ;
VAL_ 979 BMS_SingleCellVolt_45 0 "Valid value" 60000 "Valid value" 60001 "Reserved" 65535 "Reserved" ;
VAL_ 979 BMS_SingleCellVolt_46 0 "Valid value" 60000 "Valid value" 60001 "Reserved" 65535 "Reserved" ;
VAL_ 979 BMS_SingleCellVolt_47 0 "Valid value" 60000 "Valid value" 60001 "Reserved" 65535 "Reserved" ;
VAL_ 979 BMS_SingleCellVolt_48 0 "Valid value" 60000 "Valid value" 60001 "Reserved" 65535 "Reserved" ;
VAL_ 979 BMS_SingleCellVolt_49 0 "Valid value" 60000 "Valid value" 60001 "Reserved" 65535 "Reserved" ;
VAL_ 979 BMS_SingleCellVolt_50 0 "Valid value" 60000 "Valid value" 60001 "Reserved" 65535 "Reserved" ;
VAL_ 979 BMS_SingleCellVolt_51 0 "Valid value" 60000 "Valid value" 60001 "Reserved" 65535 "Reserved" ;
VAL_ 979 BMS_SingleCellVolt_52 0 "Valid value" 60000 "Valid value" 60001 "Reserved" 65535 "Reserved" ;
VAL_ 979 BMS_SingleCellVolt_53 0 "Valid value" 60000 "Valid value" 60001 "Reserved" 65535 "Reserved" ;
VAL_ 979 BMS_SingleCellVolt_54 0 "Valid value" 60000 "Valid value" 60001 "Reserved" 65535 "Reserved" ;
VAL_ 979 BMS_SingleCellVolt_55 0 "Valid value" 60000 "Valid value" 60001 "Reserved" 65535 "Reserved" ;
VAL_ 979 BMS_SingleCellVolt_56 0 "Valid value" 60000 "Valid value" 60001 "Reserved" 65535 "Reserved" ;
VAL_ 979 BMS_SingleCellVolt_57 0 "Valid value" 60000 "Valid value" 60001 "Reserved" 65535 "Reserved" ;
VAL_ 979 BMS_SingleCellVolt_58 0 "Valid value" 60000 "Valid value" 60001 "Reserved" 65535 "Reserved" ;
VAL_ 979 BMS_SingleCellVolt_59 0 "Valid value" 60000 "Valid value" 60001 "Reserved" 65535 "Reserved" ;
VAL_ 979 BMS_SingleCellVolt_60 0 "Valid value" 60000 "Valid value" 60001 "Reserved" 65535 "Reserved" ;
VAL_ 979 BMS_SingleCellVolt_61 0 "Valid value" 60000 "Valid value" 60001 "Reserved" 65535 "Reserved" ;
VAL_ 979 BMS_SingleCellVolt_62 0 "Valid value" 60000 "Valid value" 60001 "Reserved" 65535 "Reserved" ;
VAL_ 979 BMS_SingleCellVolt_63 0 "Valid value" 60000 "Valid value" 60001 "Reserved" 65535 "Reserved" ;
VAL_ 979 BMS_SingleCellVolt_64 0 "Valid value" 60000 "Valid value" 60001 "Reserved" 65535 "Reserved" ;
VAL_ 979 BMS_SingleCellVolt_65 0 "Valid value" 60000 "Valid value" 60001 "Reserved" 65535 "Reserved" ;
VAL_ 979 BMS_SingleCellVolt_66 0 "Valid value" 60000 "Valid value" 60001 "Reserved" 65535 "Reserved" ;
VAL_ 979 BMS_SingleCellVolt_67 0 "Valid value" 60000 "Valid value" 60001 "Reserved" 65535 "Reserved" ;
VAL_ 979 BMS_SingleCellVolt_68 0 "Valid value" 60000 "Valid value" 60001 "Reserved" 65535 "Reserved" ;
VAL_ 980 BMS_SingleCellVolt_69 0 "Valid value" 60000 "Valid value" 60001 "Reserved" 65535 "Reserved" ;
VAL_ 980 BMS_SingleCellVolt_70 0 "Valid value" 60000 "Valid value" 60001 "Reserved" 65535 "Reserved" ;
VAL_ 980 BMS_SingleCellVolt_71 0 "Valid value" 60000 "Valid value" 60001 "Reserved" 65535 "Reserved" ;
VAL_ 980 BMS_SingleCellVolt_72 0 "Valid value" 60000 "Valid value" 60001 "Reserved" 65535 "Reserved" ;
VAL_ 980 BMS_SingleCellVolt_73 0 "Valid value" 60000 "Valid value" 60001 "Reserved" 65535 "Reserved" ;
VAL_ 980 BMS_SingleCellVolt_74 0 "Valid value" 60000 "Valid value" 60001 "Reserved" 65535 "Reserved" ;
VAL_ 980 BMS_SingleCellVolt_75 0 "Valid value" 60000 "Valid value" 60001 "Reserved" 65535 "Reserved" ;
VAL_ 980 BMS_SingleCellVolt_76 0 "Valid value" 60000 "Valid value" 60001 "Reserved" 65535 "Reserved" ;
VAL_ 980 BMS_SingleCellVolt_77 0 "Valid value" 60000 "Valid value" 60001 "Reserved" 65535 "Reserved" ;
VAL_ 980 BMS_SingleCellVolt_78 0 "Valid value" 60000 "Valid value" 60001 "Reserved" 65535 "Reserved" ;
VAL_ 980 BMS_SingleCellVolt_79 0 "Valid value" 60000 "Valid value" 60001 "Reserved" 65535 "Reserved" ;
VAL_ 980 BMS_SingleCellVolt_80 0 "Valid value" 60000 "Valid value" 60001 "Reserved" 65535 "Reserved" ;
VAL_ 980 BMS_SingleCellVolt_81 0 "Valid value" 60000 "Valid value" 60001 "Reserved" 65535 "Reserved" ;
VAL_ 980 BMS_SingleCellVolt_82 0 "Valid value" 60000 "Valid value" 60001 "Reserved" 65535 "Reserved" ;
VAL_ 980 BMS_SingleCellVolt_83 0 "Valid value" 60000 "Valid value" 60001 "Reserved" 65535 "Reserved" ;
VAL_ 980 BMS_SingleCellVolt_84 0 "Valid value" 60000 "Valid value" 60001 "Reserved" 65535 "Reserved" ;
VAL_ 980 BMS_SingleCellVolt_85 0 "Valid value" 60000 "Valid value" 60001 "Reserved" 65535 "Reserved" ;
VAL_ 980 BMS_SingleCellVolt_86 0 "Valid value" 60000 "Valid value" 60001 "Reserved" 65535 "Reserved" ;
VAL_ 980 BMS_SingleCellVolt_87 0 "Valid value" 60000 "Valid value" 60001 "Reserved" 65535 "Reserved" ;
VAL_ 980 BMS_SingleCellVolt_88 0 "Valid value" 60000 "Valid value" 60001 "Reserved" 65535 "Reserved" ;
VAL_ 980 BMS_SingleCellVolt_89 0 "Valid value" 60000 "Valid value" 60001 "Reserved" 65535 "Reserved" ;
VAL_ 980 BMS_SingleCellVolt_90 0 "Valid value" 60000 "Valid value" 60001 "Reserved" 65535 "Reserved" ;
VAL_ 980 BMS_SingleCellVolt_91 0 "Valid value" 60000 "Valid value" 60001 "Reserved" 65535 "Reserved" ;
VAL_ 980 BMS_SingleCellVolt_92 0 "Valid value" 60000 "Valid value" 60001 "Reserved" 65535 "Reserved" ;
VAL_ 980 BMS_SingleCellVolt_93 0 "Valid value" 60000 "Valid value" 60001 "Reserved" 65535 "Reserved" ;
VAL_ 980 BMS_SingleCellVolt_94 0 "Valid value" 60000 "Valid value" 60001 "Reserved" 65535 "Reserved" ;
VAL_ 980 BMS_SingleCellVolt_95 0 "Valid value" 60000 "Valid value" 60001 "Reserved" 65535 "Reserved" ;
VAL_ 980 BMS_SingleCellVolt_96 0 "Valid value" 60000 "Valid value" 60001 "Reserved" 65535 "Reserved" ;
VAL_ 981 BMS_SingleCellVolt_97 0 "Valid value" 60000 "Valid value" 60001 "Reserved" 65535 "Reserved" ;
VAL_ 981 BMS_SingleCellVolt_98 0 "Valid value" 60000 "Valid value" 60001 "Reserved" 65535 "Reserved" ;
VAL_ 981 BMS_SingleCellVolt_99 0 "Valid value" 60000 "Valid value" 60001 "Reserved" 65535 "Reserved" ;
VAL_ 981 BMS_SingleCellVolt_100 0 "Valid value" 60000 "Valid value" 60001 "Reserved" 65535 "Reserved" ;
VAL_ 981 BMS_SingleCellVolt_101 0 "Valid value" 60000 "Valid value" 60001 "Reserved" 65535 "Reserved" ;
VAL_ 981 BMS_SingleCellVolt_102 0 "Valid value" 60000 "Valid value" 60001 "Reserved" 65535 "Reserved" ;
VAL_ 981 BMS_SingleCellVolt_103 0 "Valid value" 60000 "Valid value" 60001 "Reserved" 65535 "Reserved" ;
VAL_ 981 BMS_SingleCellVolt_104 0 "Valid value" 60000 "Valid value" 60001 "Reserved" 65535 "Reserved" ;
VAL_ 981 BMS_SingleCellVolt_105 0 "Valid value" 60000 "Valid value" 60001 "Reserved" 65535 "Reserved" ;
VAL_ 981 BMS_SingleCellVolt_106 0 "Valid value" 60000 "Valid value" 60001 "Reserved" 65535 "Reserved" ;
VAL_ 981 BMS_SingleCellVolt_107 0 "Valid value" 60000 "Valid value" 60001 "Reserved" 65535 "Reserved" ;
VAL_ 981 BMS_SingleCellVolt_108 0 "Valid value" 60000 "Valid value" 60001 "Reserved" 65535 "Reserved" ;
VAL_ 981 BMS_SingleCellVolt_109 0 "Valid value" 60000 "Valid value" 60001 "Reserved" 65535 "Reserved" ;
VAL_ 981 BMS_SingleCellVolt_110 0 "Valid value" 60000 "Valid value" 60001 "Reserved" 65535 "Reserved" ;
VAL_ 981 BMS_SingleCellVolt_111 0 "Valid value" 60000 "Valid value" 60001 "Reserved" 65535 "Reserved" ;
VAL_ 981 BMS_SingleCellVolt_112 0 "Valid value" 60000 "Valid value" 60001 "Reserved" 65535 "Reserved" ;
VAL_ 981 BMS_BattModuleTe_91 0 "Valid value" 165 "Valid value" 166 "Reserved" 254 "Reserved" 255 "invalid" ;
VAL_ 981 BMS_BattModuleTe_92 0 "Valid value" 165 "Valid value" 166 "Reserved" 254 "Reserved" 255 "invalid" ;
VAL_ 981 BMS_DTCNumber 0 "Default" 1 "Valid value" 501 "Valid value" 502 "Reserved" 511 "Reserved" ;
VAL_ 981 BMS_NumberCellVoltMin_RM 0 "Reseved" 1 "Valid value" 250 "Valid value" 251 "Reseved" 255 "Reseved" ;
VAL_ 981 BMS_ModuleMaxTemp_RM 0 "Valid value" 250 "Valid value" 251 "Reseved" 255 "Reseved" ;
VAL_ 981 BMS_BattModuleTe_13 0 "Valid value" 165 "Valid value" 166 "Reserved" 254 "Reserved" 255 "invalid" ;
VAL_ 981 BMS_BattModuleTe_23 0 "Valid value" 165 "Valid value" 166 "Reserved" 254 "Reserved" 255 "invalid" ;
VAL_ 981 BMS_BattModuleTe_33 0 "Valid value" 165 "Valid value" 166 "Reserved" 254 "Reserved" 255 "invalid" ;
VAL_ 981 BMS_BattModuleTe_43 0 "Valid value" 165 "Valid value" 166 "Reserved" 254 "Reserved" 255 "invalid" ;
VAL_ 981 BMS_BattModuleTe_53 0 "Valid value" 165 "Valid value" 166 "Reserved" 254 "Reserved" 255 "invalid" ;
VAL_ 981 BMS_BattModuleTe_63 0 "Valid value" 165 "Valid value" 166 "Reserved" 254 "Reserved" 255 "invalid" ;
VAL_ 1008 BMS_CellMaxVolt_RM 0 "Valid" 15000 "Valid" 15001 "Reserved" 65535 "Reserved" ;
VAL_ 1008 BMS_CellVoltMin_RM 0 "Valid" 15000 "Valid" 15001 "Reserved" 65535 "Reserved" ;
VAL_ 1008 BMS_NumCellMaxTemp_RM 0 "Reseved" 1 "Valid value" 250 "Valid value" 251 "Reseved" 255 "Reseved" ;
VAL_ 1008 BMS_NumCellMinTemp_RM 0 "Reseved" 1 "Valid value" 250 "Valid value" 251 "Reseved" 255 "Reseved" ;
VAL_ 1008 BMS_ModuleMinTemp_RM 0 "Valid value" 250 "Valid value" 251 "Reseved" 255 "Reseved" ;
VAL_ 1008 BMS_NumberCellVoltMax_RM 0 "Reseved" 1 "Valid value" 250 "Valid value" 251 "Reseved" 255 "Reseved" ;
VAL_ 1008 BMS_SocJumpWarn_RM 0 "No warning" 1 "warning" ;
VAL_ 1008 BMS_PackOverChrgWarn_RM 0 "No warning" 1 "warning" ;
VAL_ 1008 BMS_IsolationRValue_RM 0 "Valid value" 60000 "Valid value" 60001 "Reseved" 65535 "Reseved" ;
VAL_ 1008 BMS_PackCurr_RM 0 "Valid value" 20000 "Valid value" 20001 "Reserved" 32767 "Reserved" ;
VAL_ 1008 BMS_SocOverWarn_RM 0 "No warning" 1 "warning" ;
VAL_ 1008 BMS_BattOverTempRank_RM 0 "Normal" 1 "Waining" ;
VAL_ 1008 BMS_BattOverVoltRank_RM 0 "Normal" 1 "Waining" ;
VAL_ 1008 BMS_BattSOCLowRank_RM 0 "Normal" 1 "Waining" ;
VAL_ 1008 BMS_VCUIsolateErr_RM 0 "Normal" 1 "Waining" ;
VAL_ 1008 BMS_BattUnderVoltRank_RM 0 "Normal" 1 "Waining" ;
VAL_ 1008 BMS_CellDeltaVoltRank_RM 0 "Normal" 1 "Waining" ;
VAL_ 1008 BMS_CellOverVoltRank_RM 0 "Normal" 1 "Waining" ;
VAL_ 1008 BMS_CellUnderVoltRank_RM 0 "Normal" 1 "Waining" ;
VAL_ 1008 BMS_DeltaTempRank_RM 0 "Normal" 1 "Waining" ;
VAL_ 1008 BMS_PackMismatchWarn_RM 0 "No warning" 1 "warning" ;
VAL_ 1008 BMS_PackVolt_RM 0 "Valid value" 10000 "Valid value" 10001 "Reserved" 16383 "Reserved" ;
VAL_ 1008 BMS_SysNumberCellVoltMax_RM 0 "Reseved" 1 "Valid value" 250 "Valid value" 251 "Reseved" 255 "Reseved" ;
VAL_ 1008 BMS_SysNumberCellVoltMin_RM 0 "Reseved" 1 "Valid value" 250 "Valid value" 251 "Reseved" 255 "Reseved" ;
VAL_ 1008 BMS_SysNumCellMaxTemp_RM 0 "Reseved" 1 "Valid value" 250 "Valid value" 251 "Reseved" 255 "Reseved" ;
VAL_ 1008 BMS_SysNumCellMinTemp_RM 0 "Reseved" 1 "Valid value" 250 "Valid value" 251 "Reseved" 255 "Reseved" ;
VAL_ 1008 BMS_BattSysNum_RM 0 "Reseved" 1 "Valid value" 250 "Valid value" 251 "Reseved" 255 "Reseved" ;
VAL_ 483 BMS_BattKeepTempResp_PHEV 0 "Immediate Charging" 1 "Delay Charging" 2 "Invalid" 3 "No action" ;
VAL_ 147 TMCU_ActPosRotSpd 0 "Valid" 65534 "Valid" 65535 "Invalid" ;
VAL_ 193 CheckSum_DHT1 0 "Valid values" 255 "Valid values" ;
VAL_ 193 TCU_ClutchHotWarning 0 "Normal" 1 "Warnining" 2 "Degrading" 3 "ClutchOpen" ;
VAL_ 193 TCU_ErrCategory 1 "Warning" 2 "Partial function-external" 4 "Partial function-internal" 8 "Disable-NP" 16 "Diable" 128 "EOL not finish" ;
VAL_ 193 RollingCounter_DHT1 0 "Valid value" 14 "Valid value" 15 "Invalid value" ;
VAL_ 282 HCU_GearSts 0 "Select lever in position 'P'" 1 "Reserved" 2 "Reserved" 3 "Reserved" 4 "Reserved" 5 "Select lever in position 'D'" 6 "Select lever in position 'N'" 7 "Select lever in position 'R'" 8 "Reserved" 13 "Reserved" 14 "Intermediate position" 15 "Invalid" ;
VAL_ 265 IFCTrqOvlCmdProtnValue 0 "Valid value" 16383 "Valid value" ;
VAL_ 265 IFCTrqOvlCmdReqValue 0 "Valid value" 2047 "Valid value" ;
VAL_ 350 CR_FCTA_Resp 0 "OFF" 1 "ON" ;
VAL_ 350 CR_FCTB_Resp 0 "OFF" 1 "ON" ;
VAL_ 350 CR_BliSts 0 "No Blindness" 1 "Blindness" ;
VAL_ 350 FCTA_Warn 0 "No warning" 1 "Warning" ;
VAL_ 350 FCTBTrig 0 "Not tirggered" 1 "tirggered" ;
VAL_ 350 FCTA_B_FuncSts 0 "No display" 1 "error" 2 "FCTA_B temporarily unavailable" 3 "FCTA_B Performance degradation" ;
VAL_ 350 FCTA_B_TTC 0 "No Display" 1 "valid value" 63 "valid value" ;
VAL_ 692 AEB_LePedDetn 0 "Not dectected" 1 "Dectected" 2 "Reserved" 3 "Invalid" ;
VAL_ 692 AEB_LePedDy 0 "Valid value" 160 "Valid value" 161 "Reserved" 255 "Reserved" ;
VAL_ 692 AEB_LePedTyp 0 "Unkown" 1 "Sedan" 2 "Truck" 3 "Motorcycle" 4 "Pedestrian" 5 "Bicycle" 6 "Reserved" 7 "Invalid" ;
VAL_ 692 AEB_LePed_collisionprob 0 "no collisionprob" 1 "collisionprob" ;
VAL_ 692 AEB_RiPedDetn 0 "Not dectected" 1 "Dectected" 2 "Reserved" 3 "Invalid" ;
VAL_ 692 AEB_RiPedDy 0 "Valid value" 160 "Valid value" 161 "Reserved" 255 "Reserved" ;
VAL_ 692 AEB_RiPedTyp 0 "Unkown" 1 "Sedan" 2 "Truck" 3 "Motorcycle" 4 "Pedestrian" 5 "Bicycle" 6 "Reserved" 7 "Invalid" ;
VAL_ 692 AEB_RiPed_collisionprob 0 "no collisionprob" 1 "collisionprob" ;
VAL_ 692 AEB_LeCyclistDy 0 "Valid value" 160 "Valid value" 161 "Reserved" 255 "Reserved" ;
VAL_ 692 AEB_LeCyclist_collisionprob 0 "no collisionprob" 1 "collisionprob" ;
VAL_ 692 AEB_RiCyclistDy 0 "Valid value" 160 "Valid value" 161 "Reserved" 255 "Reserved" ;
VAL_ 692 AEB_RiCyclist_collisionprob 0 "no collisionprob" 1 "collisionprob" ;
VAL_ 692 JAPedObjExist 0 "Valid Value" 63 "Valid Value" ;
VAL_ 692 AEBJAObjID 0 "Valid Value" 254 "Valid Value" 255 "No Object" ;
VAL_ 692 AEBJAObjExist 0 "Valid Value" 63 "Valid Value" ;
VAL_ 692 JAPedObjID 0 "Valid Value" 254 "Valid Value" 255 "No Object" ;
VAL_ 692 AEBJAObjVideoCfmd 0 "No Fusion" 1 "Fusion" ;
VAL_ 692 AEBJAObjVx 0 "Valid Value" 2047 "Valid Value" 4081 "Reserved" 4095 "Reserved" ;
VAL_ 692 AEBJAObjDx 0 "Valid Value" 4095 "Valid Value" ;
VAL_ 692 JAPedObjVideoCfmd 0 "No Fusion" 1 "Fusion" ;
VAL_ 692 AEBJAObjState 0 "UNDEFINED" 1 "PRECEDING" 2 "STATIONARY" 3 "STOPPED" 4 "ONCOMING" 5 "Reserved" 7 "Reserved" ;
VAL_ 692 AEBJAObjCntAlive 0 "Valid Value" 3855 "Valid Value" 3856 "Reserved" 4095 "Reserved" ;
VAL_ 692 AEBJAObjDy 0 "Valid Value" 2047 "Valid Value" ;
VAL_ 692 JAPedObjState 0 "UNDEFINED" 1 "PRECEDING" 2 "STATIONARY" 3 "STOPPED" 4 "ONCOMING" 5 "Reserved" 7 "Reserved" ;
VAL_ 692 AEBJAObjObstcl 0 "Valid Value" 31 "Valid Value" ;
VAL_ 692 AEBJAObjVy 0 "Valid Value" 1023 "Valid Value" ;
VAL_ 692 AEBJAObjAx 0 "Valid Value" 1023 "Valid Value" ;
VAL_ 692 AEBJAObjAy 0 "Valid Value" 1023 "Valid Value" ;
VAL_ 692 JAPedObjObstcl 0 "Valid Value" 31 "Valid Value" ;
VAL_ 692 JAPedObjDy 0 "Valid Value" 2047 "Valid Value" ;
VAL_ 692 JAPedObjDx 0 "Valid Value" 4095 "Valid Value" ;
VAL_ 692 FCWAEB_JATTC 0 "No Display" 1 "valid value" 63 "valid value" ;
VAL_ 692 JAPedObjVx 0 "Valid Value" 4080 "Valid Value" 4081 "Reserved" 4095 "Reserved" ;
VAL_ 692 JAPedObjVy 0 "Valid Value" 1023 "Valid Value" ;
VAL_ 692 JAPedObjAy 0 "Valid Value" 1023 "Valid Value" ;
VAL_ 692 JAPedObjCntAlive 0 "Valid Value" 3855 "Valid Value" 3856 "Reserved" 4095 "Reserved" ;
VAL_ 692 FCWAEB_longTTC 0 "No Display" 1 "valid value" 63 "valid value" ;
VAL_ 692 FCWAEB_crossingTTC 0 "No Display" 1 "valid value" 63 "valid value" ;
VAL_ 692 JAPedObjAx 0 "Valid Value" 1023 "Valid Value" ;
VAL_ 692 AEB_LePedDx 0 "Valid value" 300 "Valid value" 301 "Reserved" 511 "Reserved" ;
VAL_ 692 AEB_RiPedDx 0 "Valid value" 300 "Valid value" 301 "Reserved" 511 "Reserved" ;
VAL_ 692 AEB_LeCyclistDetn 0 "Not dectected" 1 "Dectected" 2 "Reserved" 3 "Invalid" ;
VAL_ 692 AEB_LeCyclistDx 0 "Valid value" 300 "Valid value" 301 "Reserved" 511 "Reserved" ;
VAL_ 692 AEB_LeCyclistTyp 0 "Unkown" 1 "Sedan" 2 "Truck" 3 "Motorcycle" 4 "Pedestrian" 5 "Bicycle" 6 "Reserved" 7 "Invalid" ;
VAL_ 692 AEB_RiCyclistDetn 0 "Not dectected" 1 "Dectected" 2 "Reserved" 3 "Invalid" ;
VAL_ 692 AEB_RiCyclistDx 0 "Valid value" 300 "Valid value" 301 "Reserved" 511 "Reserved" ;
VAL_ 692 AEB_RiCyclistTyp 0 "Unkown" 1 "Sedan" 2 "Truck" 3 "Motorcycle" 4 "Pedestrian" 5 "Bicycle" 6 "Reserved" 7 "Invalid" ;
VAL_ 778 RCTA_B_TTC 0 "No Display" 1 "valid value" 63 "valid value" ;
VAL_ 778 BSD_LCA_Left_TTC 0 "No Display" 1 "valid value" 63 "valid value" ;
VAL_ 778 BSD_LCA_Right_TTC 0 "No Display" 1 "valid value" 63 "valid value" ;
VAL_ 778 RCW_TTC 0 "No Display" 1 "valid value" 63 "valid value" ;
VAL_ 778 RSDS_LeTgt_01 0 "No target" 1 "target detected" ;
VAL_ 778 RSDS_LeTgt_01_dx 0 "Valid Value" 950 "Valid Value" 951 "Reserved" 1023 "Reserved" ;
VAL_ 778 RSDS_LeTgt_01_dy 0 "Valid Value" 80 "Valid Value" 81 "Reserved" 127 "Reserved" ;
VAL_ 778 RSDS_LeTgt_02 0 "No target" 1 "target detected" ;
VAL_ 778 RSDS_LeTgt_02_dx 0 "Valid Value" 950 "Valid Value" 951 "Reserved" 1023 "Reserved" ;
VAL_ 778 RSDS_LeTgt_02_dy 0 "Valid Value" 80 "Valid Value" 81 "Reserved" 127 "Reserved" ;
VAL_ 778 RSDS_RiTgt_01 0 "No target" 1 "target detected" ;
VAL_ 778 RSDS_RiTgt_01_dx 0 "Valid Value" 950 "Valid Value" 951 "Reserved" 1023 "Reserved" ;
VAL_ 778 RSDS_RiTgt_01_dy 0 "Valid Value" 80 "Valid Value" 81 "Reserved" 127 "Reserved" ;
VAL_ 778 RSDS_RiTgt_02 0 "No target" 1 "target detected" ;
VAL_ 778 RSDS_RiTgt_02_dx 0 "Valid Value" 950 "Valid Value" 951 "Reserved" 1023 "Reserved" ;
VAL_ 778 RSDS_RiTgt_02_dy 0 "Valid Value" 80 "Valid Value" 81 "Reserved" 127 "Reserved" ;
VAL_ 778 RSDS_MidTgt_01 0 "No target" 1 "target detected" ;
VAL_ 778 RSDS_MidTgt_01_dx 0 "Valid Value" 950 "Valid Value" 951 "Reserved" 1023 "Reserved" ;
VAL_ 778 RSDS_MidTgt_01_dy 0 "Valid Value" 80 "Valid Value" 81 "Reserved" 127 "Reserved" ;
VAL_ 778 RSDS_MidTgt_02 0 "No target" 1 "target detected" ;
VAL_ 778 RSDS_MidTgt_02_dx 0 "Valid Value" 950 "Valid Value" 951 "Reserved" 1023 "Reserved" ;
VAL_ 778 RSDS_MidTgt_02_dy 0 "Valid Value" 80 "Valid Value" 81 "Reserved" 127 "Reserved" ;
VAL_ 415 IFC_Line01_Dy 0 "Valid value" 6001 "Valid value" 6002 "Reversed" 8191 "Reversed" ;
VAL_ 415 IFC_Line01_Curv 0 "Valid value" 31250 "Valid value" 31251 "Reversed" 32767 "Reversed" ;
VAL_ 415 IFC_Line01_CurvChange 0 "Valid value" 960000 "Valid value" 960001 "Reversed" 1048575 "Reversed" ;
VAL_ 415 IFC_Line01_Type 0 "undecided" 1 "solid" 2 "dashed" 3 "double solid dashed" 4 "double dashed solid" 5 "double solid solid" 6 "double dashed dashed" 7 "botts" 8 "deceleration" 9 "hov_lane" 10 "road edge" 11 "elevated_structure" 12 "curb" 13 "cones_poles" ;
VAL_ 415 IFC_Line02_Dy 0 "Valid value" 6001 "Valid value" 6002 "Reversed" 8191 "Reversed" ;
VAL_ 415 IFC_Line02_Curv 0 "Valid value" 31250 "Valid value" 31251 "Reversed" 32767 "Reversed" ;
VAL_ 415 IFC_Line02_CurvChange 0 "Valid value" 960000 "Valid value" 960001 "Reversed" 1048575 "Reversed" ;
VAL_ 415 IFC_Line02_Type 0 "undecided" 1 "solid" 2 "dashed" 3 "double solid dashed" 4 "double dashed solid" 5 "double solid solid" 6 "double dashed dashed" 7 "botts" 8 "deceleration" 9 "hov_lane" 10 "road edge" 11 "elevated_structure" 12 "curb" 13 "cones_poles" ;
VAL_ 415 IFC_Line03_Dy 0 "valid value" 6001 "valid value" 6002 "reversed" 8191 "reversed" ;
VAL_ 415 IFC_Line03_Curv 0 "valid value" 31250 "valid value" 31251 "reversed" 32767 "reversed" ;
VAL_ 415 IFC_Line03_CurvChange 0 "valid value" 960000 "valid value" 960001 "reversed" 1048575 "reversed" ;
VAL_ 415 IFC_Line03_Type 0 "undecided" 1 "solid" 2 "dashed" 3 "double solid dashed" 4 "double dashed solid" 5 "double solid solid" 6 "double dashed dashed" 7 "botts" 8 "deceleration" 9 "hov_lane" 10 "road edge" 11 "elevated_structure" 12 "curb" 13 "cones_poles" ;
VAL_ 415 IFC_Line04_Dy 0 "valid value" 6001 "valid value" 6002 "reversed" 8191 "reversed" ;
VAL_ 415 IFC_Line04_Curv 0 "valid value" 31250 "valid value" 31251 "reversed" 32767 "reversed" ;
VAL_ 415 IFC_Line04_CurvChange 0 "valid value" 960000 "valid value" 960001 "reversed" 1048575 "reversed" ;
VAL_ 415 IFC_Line04_Type 0 "undecided" 1 "solid" 2 "dashed" 3 "double solid dashed" 4 "double dashed solid" 5 "double solid solid" 6 "double dashed dashed" 7 "botts" 8 "deceleration" 9 "hov_lane" 10 "road edge" 11 "elevated_structure" 12 "curb" 13 "cones_poles" ;
VAL_ 415 IFC_Roadedge01_Dy 0 "valid value" 6001 "valid value" 6002 "reversed" 8191 "reversed" ;
VAL_ 415 IFC_Roadedge01_Curv 0 "valid value" 31250 "valid value" 31251 "reversed" 32767 "reversed" ;
VAL_ 415 IFC_Roadedge01_Type 0 "undecided" 1 "solid" 2 "dashed" 3 "double solid dashed" 4 "double dashed solid" 5 "double solid solid" 6 "double dashed dashed" 7 "botts" 8 "deceleration" 9 "hov_lane" 10 "road edge" 11 "elevated_structure" 12 "curb" 13 "cones_poles" ;
VAL_ 415 IFC_Roadedge02_Dy 0 "valid value" 6001 "valid value" 6002 "reversed" 8191 "reversed" ;
VAL_ 415 IFC_Roadedge02_Curv 0 "valid value" 31250 "valid value" 32767 "reversed" ;
VAL_ 415 IFC_Roadedge02_CurvChange 0 "valid value" 960000 "valid value" 1048575 "reversed" ;
VAL_ 415 IFC_Roadedge02_Type 0 "undecided" 1 "solid" 2 "dashed" 3 "double solid dashed" 4 "double dashed solid" 5 "double solid solid" 6 "double dashed dashed" 7 "botts" 8 "deceleration" 9 "hov_lane" 10 "road edge" 11 "elevated_structure" 12 "curb" 13 "cones_poles" ;
VAL_ 546 IFC_Line01_DxStart 0 "valid value" 20001 "valid value" 20002 "reversed" 32767 "reversed" ;
VAL_ 546 IFC_Line01_DxEnd 0 "valid value" 20001 "valid value" 20002 "reversed" 32767 "reversed" ;
VAL_ 546 IFC_Line01_HeadingAngle 0 "valid value" 401 "valid value" 402 "reversed" 511 "reversed" ;
VAL_ 546 IFC_Line02_HeadingAngle 0 "valid value" 401 "valid value" 402 "reversed" 511 "reversed" ;
VAL_ 546 IFC_Line02_DxStart 0 "valid value" 20001 "valid value" 20002 "reversed" 32767 "reversed" ;
VAL_ 546 IFC_Line02_DxEnd 0 "valid value" 20001 "valid value" 20002 "reversed" 32767 "reversed" ;
VAL_ 546 IFC_Line03_DxStart 0 "valid value" 20001 "valid value" 20002 "reversed" 32767 "reversed" ;
VAL_ 546 IFC_Line03_DxEnd 0 "valid value" 20001 "valid value" 20002 "reversed" 32767 "reversed" ;
VAL_ 546 IFC_Line03_HeadingAngle 0 "valid value" 401 "valid value" 402 "reversed" 511 "reversed" ;
VAL_ 546 IFC_Line04_DxStart 0 "valid value" 20001 "valid value" 20002 "reversed" 32767 "reversed" ;
VAL_ 546 IFC_Line04_HeadingAngle 0 "valid value" 401 "valid value" 402 "reversed" 511 "reversed" ;
VAL_ 546 IFC_Line04_DxEnd 0 "valid value" 20001 "valid value" 20002 "reversed" 32767 "reversed" ;
VAL_ 546 IFC_Roadedge01_DxStart 0 "valid value" 20001 "valid value" 20002 "reversed" 32767 "reversed" ;
VAL_ 546 IFC_Roadedge01_DxEnd 0 "valid value" 20001 "valid value" 20002 "reversed" 32767 "reversed" ;
VAL_ 546 IFC_Roadedge01_HeadingAngle 0 "valid value" 401 "valid value" 402 "reversed" 511 "reversed" ;
VAL_ 546 IFC_Roadedge02_DxStart 0 "valid value" 20001 "valid value" 20002 "reversed" 32767 "reversed" ;
VAL_ 546 IFC_Roadedge02_DxEnd 0 "valid value" 20001 "valid value" 20002 "reversed" 32767 "reversed" ;
VAL_ 546 IFC_Roadedge02_HeadingAngle 0 "valid value" 401 "valid value" 402 "reversed" 511 "reversed" ;
VAL_ 705 ChairMemPosnSetSwtFB 0 "noÂ action" 1 "setÂ memoryÂ buttonÂ 1Â successfully" 2 "setÂ memoryÂ buttonÂ 1Â unsuccessfully" 3 "setÂ memoryÂ buttonÂ 2Â successfully" 4 "setÂ memoryÂ buttonÂ 2Â unsuccessfully" 5 "setÂ memoryÂ buttonÂ 3Â successfullyï¼›" 6 "setÂ memoryÂ buttonÂ 3Â unsuccessfully" 7 "reserved" ;
VAL_ 705 DrvSeatMassgModeSts 0 "No Action" 1 "Wave Mode" 2 "Serpentine Mode" 3 "Catwalk Mode" 4 "Shoulder Mode" 5 "Lumbar Mode" 6 "reserved" 7 "reserved" ;
VAL_ 705 DrvSeatMassgLvlSetSts 0 "OFF" 1 "Low" 2 "Middle" 3 "High" 4 "reserved" 7 "reserved" ;
VAL_ 705 DrvSeatLumSMAdjSts 0 "No Action" 1 "forward" 2 "rear" 3 "up" 4 "down" 5 "reserved" 7 "reserved" ;
VAL_ 491 DrvSeatMassgLvlSet 0 "OFF" 1 "Level1_Low" 2 "Level2_Middle" 3 "Level3_High" 4 "No action" 5 "Reserved" 7 "Reserved" ;
VAL_ 491 DrvSeatMassgModSet 0 "No Action" 1 "Wave Mode" 2 "Serpentine Mode" 3 "Catwalk Mode" 4 "Shoulder Mode" 5 "Lumbar Mode" 6 "Reserved" 7 "Reserved" ;
VAL_ 491 DrvBehvTestSetUp 0 "No action" 1 "Disable" 2 "Enable" 3 "Reserved" ;
VAL_ 491 GazeAreaIntracSetUp 0 "No action" 1 "Disable" 2 "Enable" 3 "Reserved" ;
VAL_ 694 DrvSeatSupportPosnSwt 0 "No Action" 1 "Forward" 2 "Rear" 3 "Up" 4 "Down" 5 "Reserved" 7 "Reserved" ;
VAL_ 963 GMCU_MotorSerNumber_RM 0 "Reserved" 1 "Valid value" 253 "Valid value" 254 "Invalid value" 255 "Invalid value" ;
VAL_ 963 GMCU_InvActTemp_RM 0 "Valid value" 250 "Valid value" 251 "Reserved" 253 "Reserved" 254 "Error" 255 "Invalid value" ;
VAL_ 963 GMCU_ActSpd_RM 0 "Valid value" 65531 "Valid value" 65532 "Reserved" 65533 "Reserved" 65534 "Error" 65535 "Invalid value" ;
VAL_ 963 GMCU_ActTrq_RM 0 "Valid value" 65531 "Valid value" 65532 "Reserved" 65533 "Reserved" 65534 "Error" 65535 "Invalid value" ;
VAL_ 967 GMCU_ActHvDcCurr_RM 0 "Valid value" 20000 "Valid value" 20001 "Reserved" 65533 "Reserved" 65534 "Error" 65535 "Invalid value" ;
VAL_ 967 GMCU_ActHvDcVolt_RM 0 "Valid value" 60000 "Valid value" 60001 "Reserved" 65533 "Reserved" 65534 "Error" 65535 "Invalid value" ;
VAL_ 967 GMCU_ActTemp_RM 0 "Valid value" 250 "Valid value" 251 "Reserved" 253 "Reserved" 254 "Error" 255 "Invalid value" ;
VAL_ 967 GMCU_Tempwarning_RM 0 "Normal" 1 "Warning" ;
VAL_ 967 GMCU_InvTempwarning_RM 0 "Normal" 1 "Warning" ;
VAL_ 967 GMCU_OperMode_RM 0 "Reserved" 1 "Consume power" 2 "Generate electricity" 3 "Shut down" 4 "Ready" 5 "Reserved" 253 "Reserved" 254 "Error" 255 "Invalid value" ;
VAL_ 763 MbrMonrEnaSts 0 "Disable" 1 "Enable" ;
VAL_ 731 ALCMSwtSts 0 "OFF" 1 "ON" ;
SIG_GROUP_ 241 BMS4 1 : CheckSum_BMS4 BMS_PackCurr dummy_BMS4_0 BMS_PackVolt dummy_BMS4_1 dummy_BMS4_2 dummy_BMS4_3 BMS_PowerDownCmplt dummy_BMS4_4 BMS_BattPoweErr BMS_ErrCategory RollingCounter_BMS4;
SIG_GROUP_ 584 HCU_PT7 1 : CheckSum_HCU_PT7 HCU_HybSysErr_1 HCU_HybSysErr_2 HCU_HybSysErr_3 HCU_HybSysErr_4 HCU_HybSysErr_5 HCU_HybSysErr_6 HCU_HybSysErr_7 HCU_12VSysErrLmpSts dummy_HCU_PT7_0 dummy_HCU_PT7_1 HCU_HybSysErrLmpSts HCU_PowerRedWarnLmpCmd HCU_12VSysErr_1 HCU_12VSysErr_2 dummy_HCU_PT7_2 HCU_RdyLmpSts HCU_OPDLmpSts dummy_HCU_PT7_3 dummy_HCU_PT7_4 HCU_OPDSts dummy_HCU_PT7_5 HCU_EnrgFlowInd dummy_HCU_PT7_6 HCU_ModSwtFail RollingCounter_HCU_PT7;
SIG_GROUP_ 762 HCU_PT4 1 : CheckSum_HCU_PT4 dummy_HCU_PT4_0 HCU_RefuReq dummy_HCU_PT4_1 HCU_BattPowerRedWarn HCU_OPDFail HCU_EnerSavePowerMod OPDParkWarnReq dummy_HCU_PT4_2 HCU_SOCLow_Indcn HCU_RemoveChrgLine_Indcn dummy_HCU_PT4_3 HCU_WadeModeSetSts HCU_Shift_P_Indcn HCU_ConnectChrgLine_Indcn dummy_HCU_PT4_4 HCU_EgyRecFB HCU_OilTankCoverSts HCU_InhbChrgInfo dummy_HCU_PT4_5 dummy_HCU_PT4_6 HCU_ACStsReq HCU_RefuBtnSts CarWashMode_Sts CarWashMode_StsDisp RollingCounter_HCU_PT4;
SIG_GROUP_ 513 HCU_HP5 1 : Checksum_HCU_HP5 HCU_EnrgFlowInd_DHT dummy_HCU_HP5_0 HCU_PrsBrkWarn dummy_HCU_HP5_1 dummy_HCU_HP5_2 DrvModDisp_0x201 DrvModDispSts_0x201 DrvGearDisp DrvGearDispSts_0x201 HCU_ShftNotAlwd_Warn DrvFaiMsg_0x201 dummy_HCU_HP5_3 dummy_HCU_HP5_4 RollingCounter_HCU_HP5;
SIG_GROUP_ 193 DHT_FD1 1 : CheckSum_DHT1 dummy_DHT_FD1_8 TCU_ClutchHotWarning dummy_DHT_FD1_9 dummy_DHT_FD1_10 TCU_ErrCategory dummy_DHT_FD1_11 dummy_DHT_FD1_12 dummy_DHT_FD1_13 RollingCounter_DHT1;
